VERSION ""

NS_ :

BS_:

BU_: FUSION ESC eBST FCM EPS SRR_M ABM

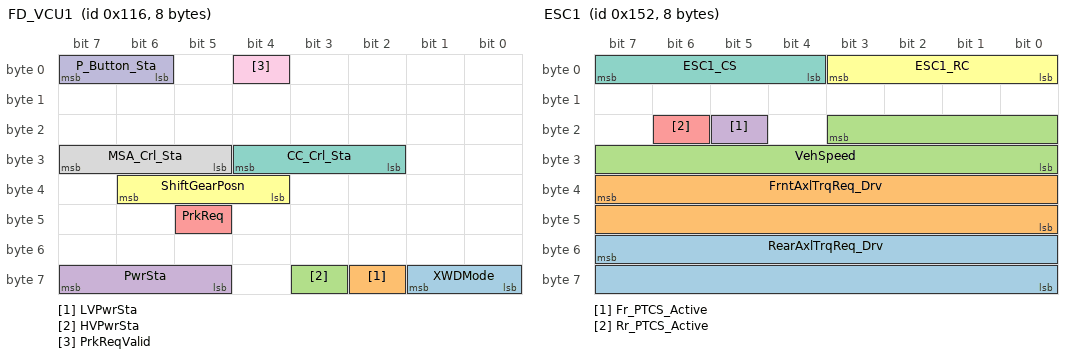
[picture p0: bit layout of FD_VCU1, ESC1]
BO_ 278 FD_VCU1: 8 FUSION
 SG_ XWDMode : 57|2@0+ (1,0) [0|2] "" ESC
 SG_ LVPwrSta : 58|1@0+ (1,0) [0|1] "" Vector__XXX
 SG_ HVPwrSta : 59|1@0+ (1,0) [0|1] "" Vector__XXX
 SG_ PwrSta : 63|3@0+ (1,0) [0|5] "" ESC,eBST,FCM,EPS,SRR_M,ABM
 SG_ PrkReq : 45|1@0+ (1,0) [0|1] "" ESC
 SG_ ShiftGearPosn : 38|3@0+ (1,0) [0|7] "" ESC,eBST,FCM,SRR_M,ABM
 SG_ CC_Crl_Sta : 28|3@0+ (1,0) [0|7] "" Vector__XXX
 SG_ MSA_Crl_Sta : 31|3@0+ (1,0) [0|7] "" Vector__XXX
 SG_ PrkReqValid : 4|1@0+ (1,0) [0|1] "" ESC
 SG_ P_Button_Sta : 7|2@0+ (1,0) [0|3] "" ESC

BO_ 338 ESC1: 8 ESC
 SG_ RearAxlTrqReq_Drv : 55|16@0+ (0.5,-5300) [0|5300] "Nm" FUSION
 SG_ FrntAxlTrqReq_Drv : 39|16@0+ (0.5,-5300) [0|5300] "Nm" FUSION
 SG_ VehSpeed : 19|12@0+ (0.125,0) [0|255.875] "km/h" FUSION
 SG_ Fr_PTCS_Active : 21|1@0+ (1,0) [0|1] "" FUSION
 SG_ Rr_PTCS_Active : 22|1@0+ (1,0) [0|1] "" FUSION
 SG_ ESC1_RC : 3|4@0+ (1,0) [0|15] "" FUSION
 SG_ ESC1_CS : 7|4@0+ (1,0) [0|15] "" FUSION

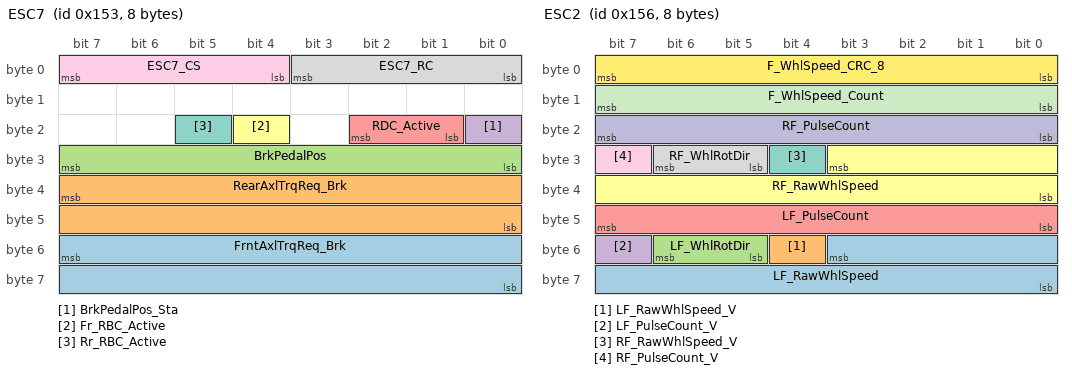
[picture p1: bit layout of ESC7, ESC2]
BO_ 339 ESC7: 8 ESC
 SG_ FrntAxlTrqReq_Brk : 55|16@0+ (0.5,-5300) [-5300|0] "Nm" FUSION
 SG_ RearAxlTrqReq_Brk : 39|16@0+ (0.5,-5300) [-5300|0] "Nm" FUSION
 SG_ BrkPedalPos : 31|8@0+ (0.4,0) [0|100] "%" FUSION
 SG_ BrkPedalPos_Sta : 16|1@0+ (1,0) [0|1] "" FUSION
 SG_ RDC_Active : 18|2@0+ (1,0) [0|2] "" FUSION
 SG_ Fr_RBC_Active : 20|1@0+ (1,0) [0|1] "" FUSION
 SG_ Rr_RBC_Active : 21|1@0+ (1,0) [0|1] "" FUSION
 SG_ ESC7_RC : 3|4@0+ (1,0) [0|15] "" FUSION
 SG_ ESC7_CS : 7|4@0+ (1,0) [0|15] "" FUSION

BO_ 340 FD_VCU2: 16 FUSION
 SG_ ActAPSPosn : 127|8@0+ (0.394,0) [0|100.076] "%" ESC,FCM,ABM
 SG_ DriverTq : 111|16@0+ (1,-4300) [-4300|4300] "Nm" FCM
 SG_ VehActPwr : 87|24@0+ (1,-600000) [-600000|600000] "W" Vector__XXX
 SG_ Rr_DriverTq : 39|16@0+ (0.5,-5300) [-5300|5300] "Nm" ESC
 SG_ Fr_DriverTq : 23|16@0+ (0.5,-5300) [-5300|5300] "Nm" ESC
 SG_ AccPedal_Override : 14|1@0+ (1,0) [0|1] "" FCM
 SG_ ACC_CtrlAvail : 15|1@0+ (1,0) [0|1] "" FCM
 SG_ CS_VCU2_CAN1 : 7|8@0+ (1,0) [0|255] "" FCM
 SG_ RC_VCU2_CAN1 : 11|4@0+ (1,0) [0|15] "" FCM

BO_ 342 ESC2: 8 ESC
 SG_ LF_RawWhlSpeed : 51|12@0+ (0.0625,0) [0|255.9375] "km/h" FUSION
 SG_ LF_RawWhlSpeed_V : 52|1@0+ (1,0) [0|1] "" FUSION
 SG_ LF_WhlRotDir : 54|2@0+ (1,0) [0|3] "" FUSION
 SG_ LF_PulseCount_V : 55|1@0+ (1,0) [0|1] "" FUSION
 SG_ LF_PulseCount : 47|8@0+ (1,0) [0|255] "" FUSION
 SG_ RF_RawWhlSpeed : 27|12@0+ (0.0625,0) [0|255.9375] "km/h" FUSION
 SG_ RF_RawWhlSpeed_V : 28|1@0+ (1,0) [0|1] "" FUSION
 SG_ RF_WhlRotDir : 30|2@0+ (1,0) [0|3] "" FUSION
 SG_ RF_PulseCount_V : 31|1@0+ (1,0) [0|1] "" FUSION
 SG_ RF_PulseCount : 23|8@0+ (1,0) [0|255] "" FUSION
 SG_ F_WhlSpeed_Count : 15|8@0+ (1,0) [0|255] "" FUSION
 SG_ F_WhlSpeed_CRC_8 : 7|8@0+ (1,0) [0|255] "" FUSION

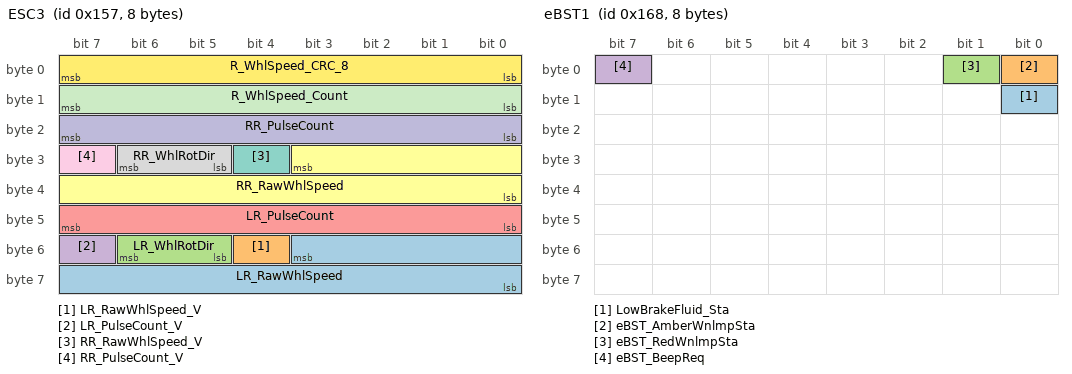
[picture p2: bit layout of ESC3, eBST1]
BO_ 343 ESC3: 8 ESC
 SG_ LR_RawWhlSpeed : 51|12@0+ (0.0625,0) [0|255.9375] "km/h" FUSION
 SG_ LR_RawWhlSpeed_V : 52|1@0+ (1,0) [0|1] "" FUSION
 SG_ LR_WhlRotDir : 54|2@0+ (1,0) [0|3] "" FUSION
 SG_ LR_PulseCount_V : 55|1@0+ (1,0) [0|1] "" FUSION
 SG_ LR_PulseCount : 47|8@0+ (1,0) [0|255] "" FUSION
 SG_ RR_RawWhlSpeed : 27|12@0+ (0.0625,0) [0|255.9375] "km/h" FUSION
 SG_ RR_RawWhlSpeed_V : 28|1@0+ (1,0) [0|1] "" FUSION
 SG_ RR_WhlRotDir : 30|2@0+ (1,0) [0|3] "" FUSION
 SG_ RR_PulseCount_V : 31|1@0+ (1,0) [0|1] "" FUSION
 SG_ RR_PulseCount : 23|8@0+ (1,0) [0|255] "" FUSION
 SG_ R_WhlSpeed_Count : 15|8@0+ (1,0) [0|255] "" FUSION
 SG_ R_WhlSpeed_CRC_8 : 7|8@0+ (1,0) [0|255] "" FUSION

BO_ 345 FD_VCU3: 20 FUSION
 SG_ Fr_EDURealDrvOrBRgnTq : 151|16@0+ (0.5,-5300) [-5300|5300] "Nm" ESC,eBST
 SG_ Fr_EDUAvailBrkRgnTq : 135|16@0+ (0.5,-5300) [-5300|0] "Nm" ESC,eBST
 SG_ Fr_EDURealARgnTq : 119|16@0+ (1,-5300) [-5300|5300] "Nm" ESC
 SG_ Fr_EDUSpd : 99|12@0+ (1,-2000) [-2000|2000] "RPM" ESC
 SG_ Fr_EDUAvailBrkRgnTqValid : 102|1@0+ (1,0) [0|1] "" ESC,eBST
 SG_ Rr_EDUAvailBrkRgnTqValid : 103|1@0+ (1,0) [0|1] "" ESC,eBST
 SG_ Rr_EDURealDrvOrBRgnTq : 87|16@0+ (0.5,-5300) [-5300|5300] "Nm" ESC,eBST
 SG_ Rr_EDUAvailBrkRgnTq : 71|16@0+ (0.5,-5300) [-5300|0] "Nm" ESC,eBST
 SG_ Rr_EDURealARgnTq : 55|16@0+ (1,-5300) [-5300|5300] "Nm" ESC
 SG_ Rr_EDUSpd : 35|12@0+ (1,-2000) [-2000|2000] "RPM" ESC
 SG_ EquivAccPedalSWSta : 38|1@0+ (1,0) [0|1] "" ESC,eBST
 SG_ PTCS_PermSta : 39|1@0+ (1,0) [0|1] "" ESC
 SG_ Rr_RgnPermSta : 24|1@0+ (1,0) [0|1] "" ESC
 SG_ Fr_RgnPermSta : 25|1@0+ (1,0) [0|1] "" ESC
 SG_ Rr_RgnDecrSta : 26|1@0+ (1,0) [0|1] "" ESC
 SG_ Fr_RgnDecrSta : 27|1@0+ (1,0) [0|1] "" ESC
 SG_ RgnAbnorSta : 28|1@0+ (1,0) [0|1] "" ESC
 SG_ Rr_EDUSpdValid : 29|1@0+ (1,0) [0|1] "" ESC
 SG_ Fr_EDUSpdValid : 30|1@0+ (1,0) [0|1] "" ESC
 SG_ RC_VCU3_CAN1 : 15|4@0+ (1,0) [0|15] "" ESC,eBST
 SG_ CS_VCU3_CAN1 : 7|8@0+ (1,0) [0|255] "" ESC,eBST

BO_ 360 eBST1: 8 eBST
 SG_ LowBrakeFluid_Sta : 8|1@0+ (1,0) [0|1] "" FUSION
 SG_ eBST_AmberWnlmpSta : 0|1@0+ (1,0) [0|1] "" FUSION
 SG_ eBST_RedWnlmpSta : 1|1@0+ (1,0) [0|1] "" FUSION
 SG_ eBST_BeepReq : 7|1@0+ (1,0) [0|1] "" FUSION

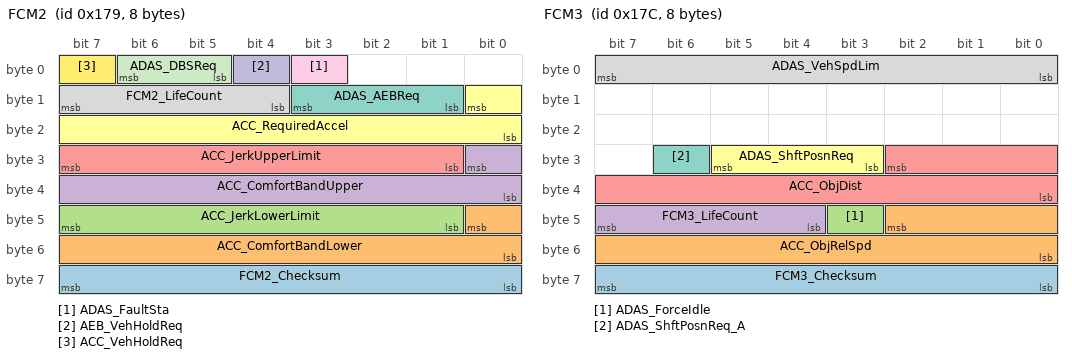
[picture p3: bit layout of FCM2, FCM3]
BO_ 377 FCM2: 8 FCM
 SG_ FCM2_Checksum : 63|8@0+ (1,0) [0|255] "" FUSION
 SG_ ACC_ComfortBandLower : 40|9@0+ (0.05,-15) [-15|10.55] "m/s^2" FUSION
 SG_ ACC_JerkLowerLimit : 47|7@0+ (0.1,-6) [-6|6.7] "m/s^3" FUSION
 SG_ ACC_ComfortBandUpper : 24|9@0+ (0.05,-15) [-15|10.55] "m/s^2" FUSION
 SG_ ACC_JerkUpperLimit : 31|7@0+ (0.1,-6) [-6|6.7] "m/s^3" FUSION
 SG_ ACC_RequiredAccel : 8|9@0+ (0.05,-15) [-15|10.55] "m/s^2" FUSION
 SG_ ADAS_AEBReq : 11|3@0+ (1,0) [0|7] "" FUSION
 SG_ FCM2_LifeCount : 15|4@0+ (1,0) [0|15] "" FUSION
 SG_ ADAS_FaultSta : 3|1@0+ (1,0) [0|1] "" FUSION
 SG_ AEB_VehHoldReq : 4|1@0+ (1,0) [0|1] "" FUSION
 SG_ ADAS_DBSReq : 6|2@0+ (1,0) [0|3] "" FUSION
 SG_ ACC_VehHoldReq : 7|1@0+ (1,0) [0|1] "" FUSION

BO_ 380 FCM3: 8 FCM
 SG_ FCM3_Checksum : 63|8@0+ (1,0) [0|255] "" FUSION
 SG_ ACC_ObjRelSpd : 42|11@0+ (0.1,-100) [-100|104.6] "m/s" FUSION
 SG_ ADAS_ForceIdle : 43|1@0+ (1,0) [0|1] "" FUSION
 SG_ FCM3_LifeCount : 47|4@0+ (1,0) [0|15] "" FUSION
 SG_ ACC_ObjDist : 26|11@0+ (0.1,0) [0|204.6] "m" FUSION
 SG_ ADAS_ShftPosnReq : 29|3@0+ (1,0) [0|7] "" FUSION
 SG_ ADAS_ShftPosnReq_A : 30|1@0+ (1,0) [0|1] "" FUSION
 SG_ ADAS_VehSpdLim : 7|8@0+ (1,0) [0|254] "" FUSION

BO_ 386 FD_THCM1: 20 FUSION
 SG_ Rr_Coolanttemp : 144|9@0+ (1,-40) [-40|214] "Deg^C" Vector__XXX
 SG_ Rr_Coolantflow : 150|6@0+ (0.25,0) [0|15.75] "L/min" Vector__XXX
 SG_ FD_AGS_Cmd : 143|8@0+ (1,0) [0|255] "" Vector__XXX
 SG_ sigClntTHvBattOut : 135|8@0+ (0.5,-40) [-40|85] "Deg^C" Vector__XXX
 SG_ sigCbnSolarLeft : 127|8@0+ (5,0) [0|1265] "W" Vector__XXX
 SG_ CabinMode : 115|4@0+ (1,0) [0|9] "" Vector__XXX
 SG_ BatteryMode : 118|3@0+ (1,0) [0|5] "" Vector__XXX
 SG_ FD_RecyAuto_Cmd : 111|3@0+ (1,0) [0|6] "" Vector__XXX
 SG_ sigCbnSolarRight : 103|8@0+ (5,0) [0|1265] "W" Vector__XXX
 SG_ sigAmbAirT : 95|8@0+ (0.5,-40) [-40|85] "Deg^C" ESC
 SG_ sigCbnAirT : 87|8@0+ (0.5,-40) [-40|85] "Deg^C" Vector__XXX
 SG_ sigCbnPTCPwrAct : 79|8@0+ (50,0) [0|12650] "W" Vector__XXX
 SG_ sigClmtCmprPwrAct : 71|8@0+ (50,0) [0|12650] "W" Vector__XXX
 SG_ Fr_Coolantflow : 61|6@0+ (0.25,0) [0|15.75] "L/min" Vector__XXX
 SG_ EDriveMode : 63|2@0+ (1,0) [0|2] "" Vector__XXX
 SG_ sigSetTempZon1St : 53|6@0+ (0.5,17) [17|32] "Deg^C" Vector__XXX
 SG_ HPThermalRecoveryReq : 55|2@0+ (1,0) [0|1] "" Vector__XXX
 SG_ sigSetTempZon2St : 45|6@0+ (0.5,17) [17|32] "Deg^C" Vector__XXX
 SG_ sigHvacSt : 46|1@0+ (1,0) [0|1] "" Vector__XXX
 SG_ sigRecircSt : 47|1@0+ (1,0) [0|1] "" Vector__XXX
 SG_ sigSetTempZon3St : 37|6@0+ (0.5,17) [17|32] "Deg^C" Vector__XXX
 SG_ sigDfrstSt : 38|1@0+ (1,0) [0|1] "" Vector__XXX
 SG_ CCU_SyncLampSts : 39|1@0+ (1,0) [0|1] "" Vector__XXX
 SG_ sigAirIntenZon3St : 27|4@0+ (1,0) [0|15] "" Vector__XXX
 SG_ sigAirIntenZon1St : 31|4@0+ (1,0) [0|15] "" Vector__XXX
 SG_ sigWindDirZon3St : 18|3@0+ (1,0) [0|7] "" Vector__XXX
 SG_ CCU_FrtOnOffLampSts : 19|1@0+ (1,0) [0|1] "" Vector__XXX
 SG_ sigWindDirZon1St : 22|3@0+ (1,0) [0|7] "" Vector__XXX
 SG_ CCU_RrOnOffLampSts : 23|1@0+ (1,0) [0|1] "" Vector__XXX
 SG_ Fr_Coolanttemp : 0|9@0+ (1,-40) [-40|214] "Deg^C" Vector__XXX
 SG_ CCU_ACMaxLampSts : 1|1@0+ (1,0) [0|1] "" Vector__XXX
 SG_ CCU_AutoLampSts : 2|1@0+ (1,0) [0|1] "" Vector__XXX
 SG_ CCU_AutoMidLampSts : 3|1@0+ (1,0) [0|1] "" Vector__XXX
 SG_ CCU_EcoSts : 4|1@0+ (1,0) [0|1] "" Vector__XXX
 SG_ CCU_Dispaly_Request : 5|1@0+ (1,0) [0|1] "" Vector__XXX
 SG_ CCU_ACLampSts : 6|1@0+ (1,0) [0|1] "" Vector__XXX
 SG_ CCU_HEATMaxLampSts : 7|1@0+ (1,0) [0|1] "" Vector__XXX

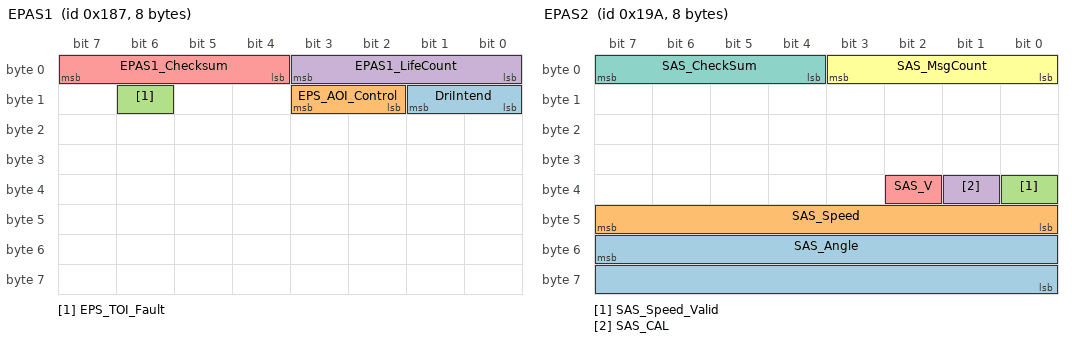
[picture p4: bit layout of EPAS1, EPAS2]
BO_ 391 EPAS1: 8 EPS
 SG_ DriIntend : 9|2@0+ (1,0) [0|2] "" FUSION
 SG_ EPS_AOI_Control : 11|2@0+ (1,0) [0|3] "" FUSION
 SG_ EPS_TOI_Fault : 14|1@0+ (1,0) [0|1] "" FUSION
 SG_ EPAS1_LifeCount : 3|4@0+ (1,0) [0|15] "" FUSION
 SG_ EPAS1_Checksum : 7|4@0+ (1,0) [0|15] "" FUSION

BO_ 410 EPAS2: 8 EPS
 SG_ SAS_Angle : 55|16@0+ (0.1,-900) [-900|900] "Deg" FUSION
 SG_ SAS_Speed : 47|8@0+ (4,0) [0|1020] "Deg/s" FUSION
 SG_ SAS_Speed_Valid : 32|1@0+ (1,0) [0|1] "" FUSION
 SG_ SAS_CAL : 33|1@0+ (1,0) [0|1] "" FUSION
 SG_ SAS_V : 34|1@0+ (1,0) [0|1] "" FUSION
 SG_ SAS_MsgCount : 3|4@0+ (1,0) [0|15] "" FUSION
 SG_ SAS_CheckSum : 7|4@0+ (1,0) [0|15] "" FUSION

BO_ 419 ESC4: 8 ESC
 SG_ Red_WnlmpSta : 59|1@0+ (1,0) [0|1] "" FUSION
 SG_ ABS_WnlmpSta : 60|1@0+ (1,0) [0|1] "" FUSION
 SG_ ESC_Off_lmpSta : 61|1@0+ (1,0) [0|1] "" FUSION
 SG_ ESC_WnlmpSta : 63|2@0+ (1,0) [0|2] "" FUSION
 SG_ GRADE : 55|8@0+ (0.354331,-45) [-45|45] "Deg" FUSION
 SG_ EBD_Active : 44|1@0+ (1,0) [0|1] "" FUSION
 SG_ ABS_Active : 45|1@0+ (1,0) [0|1] "" FUSION
 SG_ TCS_Active : 46|1@0+ (1,0) [0|1] "" FUSION
 SG_ ESC_Active : 47|1@0+ (1,0) [0|1] "" FUSION
 SG_ HBB_Active : 32|1@0+ (1,0) [0|1] "" FUSION
 SG_ PBA_Active : 33|1@0+ (1,0) [0|1] "" FUSION
 SG_ HSA_Active : 34|1@0+ (1,0) [0|1] "" FUSION
 SG_ AVH_Active : 35|1@0+ (1,0) [0|1] "" FUSION
 SG_ Amber_WnlmpSta : 36|1@0+ (1,0) [0|1] "" FUSION
 SG_ BTCS_Active : 37|1@0+ (1,0) [0|1] "" FUSION
 SG_ ESS_Active : 38|1@0+ (1,0) [0|1] "" FUSION
 SG_ HDD_Active : 39|1@0+ (1,0) [0|1] "" FUSION
 SG_ EBD_Failed : 24|1@0+ (1,0) [0|1] "" FUSION
 SG_ ABS_Failed : 25|1@0+ (1,0) [0|1] "" FUSION
 SG_ TCS_Failed : 26|1@0+ (1,0) [0|1] "" FUSION
 SG_ ESC_Failed : 27|1@0+ (1,0) [0|1] "" FUSION
 SG_ HBB_Failed : 28|1@0+ (1,0) [0|1] "" FUSION
 SG_ PBA_Failed : 29|1@0+ (1,0) [0|1] "" FUSION
 SG_ HSA_Failed : 30|1@0+ (1,0) [0|1] "" FUSION
 SG_ AVH_Failed : 31|1@0+ (1,0) [0|1] "" FUSION
 SG_ HDD_Failed : 16|1@0+ (1,0) [0|1] "" FUSION
 SG_ ESC_OFF_Status : 18|2@0+ (1,0) [0|2] "" FUSION
 SG_ ESC_BeepReq : 15|1@0+ (1,0) [0|1] "" FUSION
 SG_ SystemVoltage : 7|8@0+ (0.08,0) [0|20.32] "V" FUSION

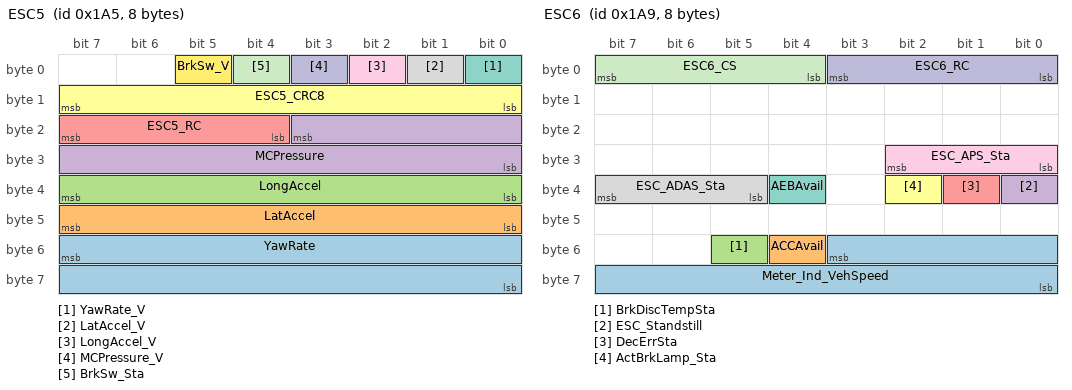
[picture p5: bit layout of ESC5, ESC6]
BO_ 421 ESC5: 8 ESC
 SG_ YawRate : 55|16@0+ (0.1,-100) [-100|100] "Deg/s" FUSION
 SG_ LatAccel : 47|8@0+ (0.01,-1.27) [-1.27|1.27] "G's" FUSION
 SG_ LongAccel : 39|8@0+ (0.01,-1.27) [-1.27|1.27] "G's" FUSION
 SG_ MCPressure : 19|12@0+ (0.1,-9.7) [-9.7|195] "bar" FUSION
 SG_ ESC5_RC : 23|4@0+ (1,0) [0|15] "" FUSION
 SG_ ESC5_CRC8 : 15|8@0+ (1,0) [0|255] "" FUSION
 SG_ YawRate_V : 0|1@0+ (1,0) [0|1] "" FUSION
 SG_ LatAccel_V : 1|1@0+ (1,0) [0|1] "" FUSION
 SG_ LongAccel_V : 2|1@0+ (1,0) [0|1] "" FUSION
 SG_ MCPressure_V : 3|1@0+ (1,0) [0|1] "" FUSION
 SG_ BrkSw_Sta : 4|1@0+ (1,0) [0|1] "" FUSION
 SG_ BrkSw_V : 5|1@0+ (1,0) [0|1] "" FUSION

BO_ 425 ESC6: 8 ESC
 SG_ Meter_Ind_VehSpeed : 51|12@0+ (0.125,0) [0|300] "km/h" FUSION
 SG_ ACCAvail : 52|1@0+ (1,0) [0|1] "" FUSION
 SG_ BrkDiscTempSta : 53|1@0+ (1,0) [0|1] "" FUSION
 SG_ ESC_Standstill : 32|1@0+ (1,0) [0|1] "" FUSION
 SG_ DecErrSta : 33|1@0+ (1,0) [0|1] "" FUSION
 SG_ ActBrkLamp_Sta : 34|1@0+ (1,0) [0|1] "" FUSION
 SG_ AEBAvail : 36|1@0+ (1,0) [0|1] "" FUSION
 SG_ ESC_ADAS_Sta : 39|3@0+ (1,0) [0|6] "" FUSION
 SG_ ESC_APS_Sta : 26|3@0+ (1,0) [0|5] "" FUSION
 SG_ ESC6_RC : 3|4@0+ (1,0) [0|15] "" FUSION
 SG_ ESC6_CS : 7|4@0+ (1,0) [0|15] "" FUSION

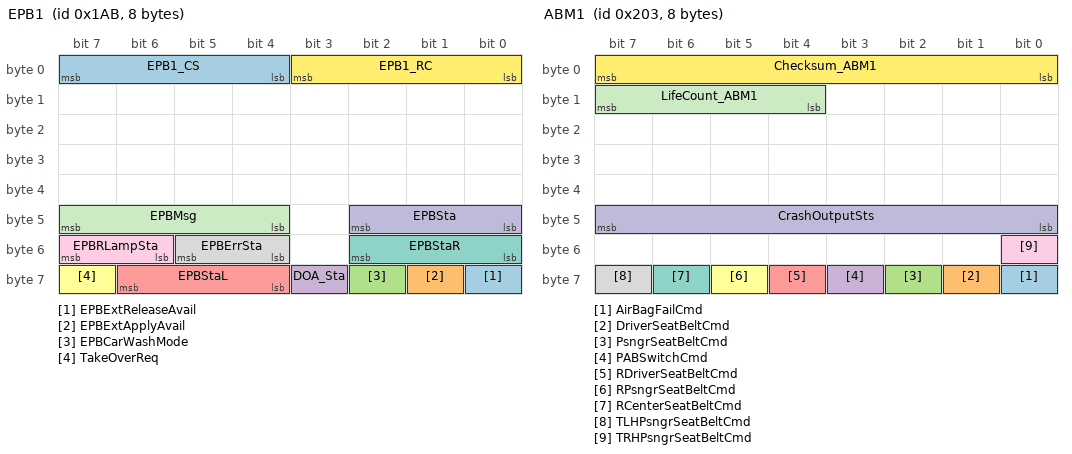
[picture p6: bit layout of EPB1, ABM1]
BO_ 427 EPB1: 8 ESC
 SG_ EPBExtReleaseAvail : 56|1@0+ (1,0) [0|1] "" FUSION
 SG_ EPBExtApplyAvail : 57|1@0+ (1,0) [0|1] "" FUSION
 SG_ EPBCarWashMode : 58|1@0+ (1,0) [0|1] "" FUSION
 SG_ DOA_Sta : 59|1@0+ (1,0) [0|1] "" FUSION
 SG_ EPBStaL : 62|3@0+ (1,0) [0|7] "" FUSION
 SG_ TakeOverReq : 63|1@0+ (1,0) [0|1] "" FUSION
 SG_ EPBStaR : 50|3@0+ (1,0) [0|7] "" FUSION
 SG_ EPBErrSta : 53|2@0+ (1,0) [0|2] "" FUSION
 SG_ EPBRLampSta : 55|2@0+ (1,0) [0|2] "" FUSION
 SG_ EPBSta : 42|3@0+ (1,0) [0|4] "" FUSION
 SG_ EPBMsg : 47|4@0+ (1,0) [0|12] "" FUSION
 SG_ EPB1_RC : 3|4@0+ (1,0) [0|15] "" FUSION
 SG_ EPB1_CS : 7|4@0+ (1,0) [0|15] "" FUSION

BO_ 515 ABM1: 8 ABM
 SG_ AirBagFailCmd : 56|1@0+ (1,0) [0|1] "" FUSION
 SG_ DriverSeatBeltCmd : 57|1@0+ (1,0) [0|1] "" FUSION
 SG_ PsngrSeatBeltCmd : 58|1@0+ (1,0) [0|1] "" FUSION
 SG_ PABSwitchCmd : 59|1@0+ (1,0) [0|1] "" FUSION
 SG_ RDriverSeatBeltCmd : 60|1@0+ (1,0) [0|1] "" FUSION
 SG_ RPsngrSeatBeltCmd : 61|1@0+ (1,0) [0|1] "" FUSION
 SG_ RCenterSeatBeltCmd : 62|1@0+ (1,0) [0|1] "" FUSION
 SG_ TLHPsngrSeatBeltCmd : 63|1@0+ (1,0) [0|1] "" FUSION
 SG_ TRHPsngrSeatBeltCmd : 48|1@0+ (1,0) [0|1] "" FUSION
 SG_ CrashOutputSts : 47|8@0+ (1,0) [0|16] "" FUSION
 SG_ LifeCount_ABM1 : 15|4@0+ (1,0) [0|15] "" FUSION
 SG_ Checksum_ABM1 : 7|8@0+ (1,0) [0|255] "" FUSION

BO_ 517 SRR1: 8 SRR_M
 SG_ SRR1_Chksum : 63|8@0+ (1,0) [0|255] "" FUSION
 SG_ SRR_RCTA_WarnR : 48|1@0+ (1,0) [0|1] "" FUSION
 SG_ SRR_RCTA_WarnL : 49|1@0+ (1,0) [0|1] "" FUSION
 SG_ SRR_BSD_WarnR : 41|2@0+ (1,0) [0|3] "" FUSION
 SG_ SRR_BSD_WarnL : 43|2@0+ (1,0) [0|3] "" FUSION
 SG_ SRR_BSD_SoundR : 44|1@0+ (1,0) [0|1] "" FUSION
 SG_ SRR_BSD_SoundL : 45|1@0+ (1,0) [0|1] "" FUSION
 SG_ SRR_BSD_Mute : 46|1@0+ (1,0) [0|1] "" FUSION
 SG_ SRR_ODA_WarnR : 33|2@0+ (1,0) [0|3] "" FUSION
 SG_ SRR_ODA_WarnL : 35|2@0+ (1,0) [0|3] "" FUSION
 SG_ SRR_ODA_SoundR : 36|1@0+ (1,0) [0|1] "" FUSION
 SG_ SRR_ODA_SoundL : 37|1@0+ (1,0) [0|1] "" FUSION
 SG_ SRR_ODA_Mute : 38|1@0+ (1,0) [0|1] "" FUSION
 SG_ SRR_ODA_Sta : 18|3@0+ (1,0) [0|7] "" FUSION
 SG_ SRR_BSD_Sta : 10|3@0+ (1,0) [0|7] "" FUSION
 SG_ SRR_RCTA_Sta : 14|3@0+ (1,0) [0|7] "" FUSION
 SG_ SRR_FltWrnReq : 15|1@0+ (1,0) [0|1] "" FUSION
 SG_ SRR1_LifeCount : 7|4@0+ (1,0) [0|15] "" FUSION

BO_ 528 FD_APS2: 32 FUSION
 SG_ PAS_A_FCL : 219|4@0+ (1,0) [0|15] "" Vector__XXX
 SG_ PAS_Chime : 223|4@0+ (1,0) [0|15] "" Vector__XXX
 SG_ APS_Progress_PCT : 215|8@0+ (1,0) [0|100] "%" Vector__XXX
 SG_ APS_RQ_Display : 207|8@0+ (1,0) [0|255] "" Vector__XXX
 SG_ PAS_D_RMR : 199|8@0+ (1,0) [0|150] "" Vector__XXX
 SG_ PAS_D_RML : 191|8@0+ (1,0) [0|150] "" Vector__XXX
 SG_ PAS_D_RCR : 183|8@0+ (1,0) [0|150] "" Vector__XXX
 SG_ PAS_D_RCL : 175|8@0+ (1,0) [0|150] "" Vector__XXX
 SG_ APS_SW_Ver : 167|8@0+ (1,0) [0|255] "" Vector__XXX
 SG_ APS_HW_Ver : 159|8@0+ (1,0) [0|255] "" Vector__XXX
 SG_ APS_ExitCondition : 151|8@0+ (1,0) [0|255] "" Vector__XXX
 SG_ PAS_D_FMR : 143|8@0+ (1,0) [0|150] "" Vector__XXX
 SG_ PAS_D_FML : 135|8@0+ (1,0) [0|150] "" Vector__XXX
 SG_ PAS_D_FCR : 127|8@0+ (1,0) [0|150] "" Vector__XXX
 SG_ PAS_D_FCL : 119|8@0+ (1,0) [0|150] "" Vector__XXX
 SG_ APS_D_RLR : 97|10@0+ (1,0) [0|1023] "" Vector__XXX
 SG_ APS_D_RLL : 81|10@0+ (1,0) [0|1023] "" Vector__XXX
 SG_ APS_D_FLR : 65|10@0+ (1,0) [0|1023] "" Vector__XXX
 SG_ APS_D_FLL : 49|10@0+ (1,0) [0|1023] "" Vector__XXX
 SG_ PAS_SNSR_Layout : 43|4@0+ (1,0) [0|15] "" Vector__XXX
 SG_ PAS_A_RMR : 47|4@0+ (1,0) [0|15] "" Vector__XXX
 SG_ PAS_A_RML : 35|4@0+ (1,0) [0|15] "" Vector__XXX
 SG_ PAS_A_RCR : 39|4@0+ (1,0) [0|15] "" Vector__XXX
 SG_ PAS_A_RCL : 27|4@0+ (1,0) [0|15] "" Vector__XXX
 SG_ PAS_A_FMR : 31|4@0+ (1,0) [0|15] "" Vector__XXX
 SG_ PAS_A_FML : 19|4@0+ (1,0) [0|15] "" Vector__XXX
 SG_ PAS_A_FCR : 23|4@0+ (1,0) [0|15] "" Vector__XXX
 SG_ PAS_Sta_F_Sys : 9|1@0+ (1,0) [0|1] "" Vector__XXX
 SG_ PAS_Mod_Operation : 11|2@0+ (1,0) [0|3] "" Vector__XXX
 SG_ USS_Sta_RMR : 12|1@0+ (1,0) [0|1] "" Vector__XXX
 SG_ USS_Sta_RML : 13|1@0+ (1,0) [0|1] "" Vector__XXX
 SG_ USS_Sta_RLR : 14|1@0+ (1,0) [0|1] "" Vector__XXX
 SG_ USS_Sta_RLL : 15|1@0+ (1,0) [0|1] "" Vector__XXX
 SG_ USS_Sta_RCR : 0|1@0+ (1,0) [0|1] "" Vector__XXX
 SG_ USS_Sta_RCL : 1|1@0+ (1,0) [0|1] "" Vector__XXX
 SG_ USS_Sta_FMR : 2|1@0+ (1,0) [0|1] "" Vector__XXX
 SG_ USS_Sta_FML : 3|1@0+ (1,0) [0|1] "" Vector__XXX
 SG_ USS_Sta_FLR : 4|1@0+ (1,0) [0|1] "" Vector__XXX
 SG_ USS_Sta_FLL : 5|1@0+ (1,0) [0|1] "" Vector__XXX
 SG_ USS_Sta_FCR : 6|1@0+ (1,0) [0|1] "" Vector__XXX
 SG_ USS_Sta_FCL : 7|1@0+ (1,0) [0|1] "" Vector__XXX

BO_ 534 FD_BCM1: 16 FUSION
 SG_ DrDoorSW : 120|1@0+ (1,0) [0|1] "" ESC,FCM,SRR_M
 SG_ PsDoorSW : 121|1@0+ (1,0) [0|1] "" FCM,SRR_M
 SG_ RLDoorSW : 122|1@0+ (1,0) [0|1] "" FCM,SRR_M
 SG_ RRDoorSW : 123|1@0+ (1,0) [0|1] "" FCM,SRR_M
 SG_ AllDoorSW : 124|1@0+ (1,0) [0|1] "" FCM
 SG_ DoorLockIND : 125|1@0+ (1,0) [0|1] "" Vector__XXX
 SG_ HoodSW : 126|1@0+ (1,0) [0|1] "" Vector__XXX
 SG_ Tailgate_SW : 127|1@0+ (1,0) [0|1] "" FCM
 SG_ CTDCtrl : 113|2@0+ (1,0) [0|3] "" Vector__XXX
 SG_ Fr_ChargingDoorCtrl : 115|2@0+ (1,0) [0|3] "" Vector__XXX
 SG_ Rr_ChargingDoorCtrl : 117|2@0+ (1,0) [0|3] "" Vector__XXX
 SG_ CTDLockSW : 118|1@0+ (1,0) [0|1] "" Vector__XXX
 SG_ CTDUnlockSW : 119|1@0+ (1,0) [0|1] "" Vector__XXX
 SG_ MirrorDefog : 104|1@0+ (1,0) [0|1] "" Vector__XXX
 SG_ Rr_Defog : 105|1@0+ (1,0) [0|1] "" Vector__XXX
 SG_ TrunkRel : 106|1@0+ (1,0) [0|1] "" Vector__XXX
 SG_ TailgateHDSW : 107|1@0+ (1,0) [0|1] "" Vector__XXX
 SG_ MirrorCtrl : 109|2@0+ (1,0) [0|3] "" Vector__XXX
 SG_ Fr_Wiper_H : 110|1@0+ (1,0) [0|1] "" FCM
 SG_ Fr_Wiper_L : 111|1@0+ (1,0) [0|1] "" FCM
 SG_ Rr_Wiper : 96|1@0+ (1,0) [0|1] "" Vector__XXX
 SG_ WiperFixMode : 97|1@0+ (1,0) [0|1] "" Vector__XXX
 SG_ WasherCtrl : 99|2@0+ (1,0) [0|3] "" Vector__XXX
 SG_ L_Beam : 100|1@0+ (1,0) [0|1] "" FCM
 SG_ H_Beam : 101|1@0+ (1,0) [0|1] "" FCM
 SG_ PosLamp : 102|1@0+ (1,0) [0|1] "" Vector__XXX
 SG_ LDRL : 103|1@0+ (1,0) [0|1] "" Vector__XXX
 SG_ RDRL : 88|1@0+ (1,0) [0|1] "" Vector__XXX
 SG_ ReverseLamp : 89|1@0+ (1,0) [0|1] "" Vector__XXX
 SG_ BrakeLamp : 90|1@0+ (1,0) [0|1] "" Vector__XXX
 SG_ LBSD : 91|1@0+ (1,0) [0|1] "" SRR_M
 SG_ RBSD : 92|1@0+ (1,0) [0|1] "" SRR_M
 SG_ Fr_FogLamp : 93|1@0+ (1,0) [0|1] "" Vector__XXX
 SG_ Rr_FogLamp : 94|1@0+ (1,0) [0|1] "" Vector__XXX
 SG_ HazardSW : 95|1@0+ (1,0) [0|1] "" FCM
 SG_ LTurnLP : 80|1@0+ (1,0) [0|1] "" FCM,SRR_M
 SG_ RTurnLP : 81|1@0+ (1,0) [0|1] "" FCM,SRR_M
 SG_ AntitheftSta : 83|2@0+ (1,0) [0|3] "" SRR_M
 SG_ AntiTheftSeatFold : 84|1@0+ (1,0) [0|1] "" Vector__XXX
 SG_ Dimmer : 78|7@0+ (1,0) [0|100] "%" Vector__XXX
 SG_ LockSetting : 79|1@0+ (1,0) [0|1] "" Vector__XXX
 SG_ BCM_Buzzer_Req : 64|1@0+ (1,0) [0|1] "" Vector__XXX
 SG_ TailgateRemote : 66|2@0+ (1,0) [0|3] "" Vector__XXX
 SG_ RoomLampL : 67|1@0+ (1,0) [0|1] "" Vector__XXX
 SG_ RoomLampH : 68|1@0+ (1,0) [0|1] "" Vector__XXX
 SG_ DimmerEN : 69|1@0+ (1,0) [0|1] "" Vector__XXX
 SG_ BCM_DoorLock_Sta : 70|1@0+ (1,0) [0|1] "" Vector__XXX
 SG_ HornCtrl : 71|1@0+ (1,0) [0|1] "" Vector__XXX
 SG_ CrashDetd : 85|1@0+ (1,0) [0|1] "" Vector__XXX
 SG_ L_APM_WdwEnable : 87|1@0+ (1,0) [0|1] "" Vector__XXX

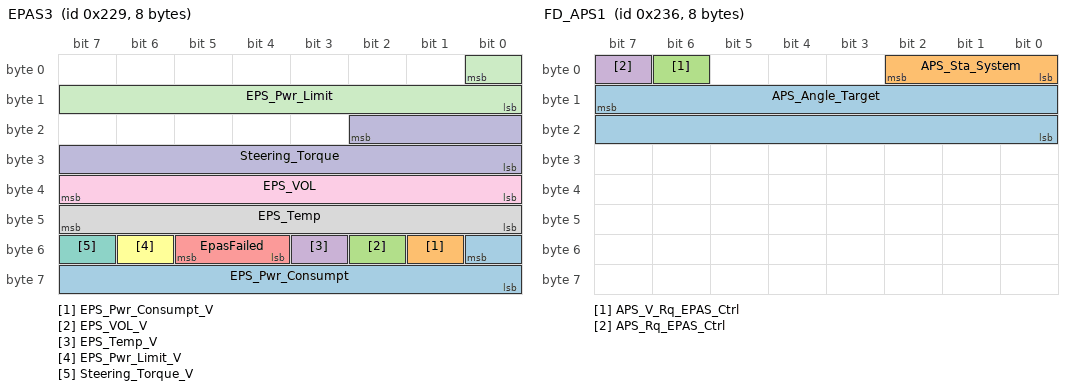
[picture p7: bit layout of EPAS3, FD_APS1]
BO_ 553 EPAS3: 8 EPS
 SG_ EPS_Pwr_Consumpt : 48|9@0+ (0.5,0) [0|135] "A" FUSION
 SG_ EPS_Pwr_Consumpt_V : 49|1@0+ (1,0) [0|1] "" FUSION
 SG_ EPS_VOL_V : 50|1@0+ (1,0) [0|1] "" FUSION
 SG_ EPS_Temp_V : 51|1@0+ (1,0) [0|1] "" FUSION
 SG_ EpasFailed : 53|2@0+ (1,0) [0|2] "" FUSION
 SG_ EPS_Pwr_Limit_V : 54|1@0+ (1,0) [0|1] "" FUSION
 SG_ Steering_Torque_V : 55|1@0+ (1,0) [0|1] "" FUSION
 SG_ EPS_Temp : 47|8@0+ (1,-100) [-100|155] "Deg^C" FUSION
 SG_ EPS_VOL : 39|8@0+ (0.1,0) [0|25.5] "V" FUSION
 SG_ Steering_Torque : 18|11@0+ (0.01,-10) [-10|10] "Nm" FUSION
 SG_ EPS_Pwr_Limit : 0|9@0+ (0.5,0) [0|135] "A" FUSION

BO_ 566 FD_APS1: 8 FUSION
 SG_ APS_Angle_Target : 15|16@0+ (0.1,-900) [-900|900] "Deg" EPS
 SG_ APS_Sta_System : 2|3@0+ (1,0) [0|7] "" ESC,FCM
 SG_ APS_V_Rq_EPAS_Ctrl : 6|1@0+ (1,0) [0|1] "" EPS
 SG_ APS_Rq_EPAS_Ctrl : 7|1@0+ (1,0) [0|1] "" EPS

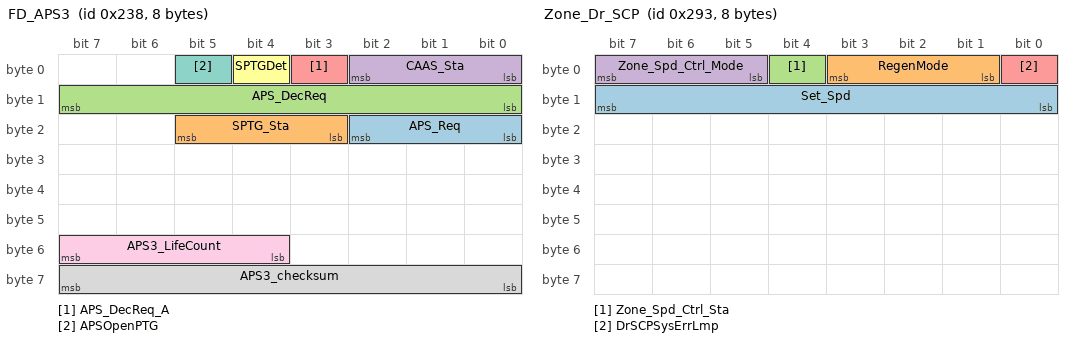
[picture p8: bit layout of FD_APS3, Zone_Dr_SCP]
BO_ 568 FD_APS3: 8 FUSION
 SG_ APS_Req : 18|3@0+ (1,0) [0|7] "" ESC
 SG_ SPTG_Sta : 21|3@0+ (1,0) [0|7] "" Vector__XXX
 SG_ APS_DecReq : 15|8@0+ (0.1,0) [0|25.4] "m/s^2" ESC
 SG_ CAAS_Sta : 2|3@0+ (1,0) [0|7] "" Vector__XXX
 SG_ APS_DecReq_A : 3|1@0+ (1,0) [0|1] "" ESC
 SG_ SPTGDet : 4|1@0+ (1,0) [0|1] "" Vector__XXX
 SG_ APSOpenPTG : 5|1@0+ (1,0) [0|1] "" Vector__XXX
 SG_ APS3_checksum : 63|8@0+ (1,0) [0|255] "" ESC
 SG_ APS3_LifeCount : 55|4@0+ (1,0) [0|15] "" ESC

BO_ 570 FCM4: 8 FCM
 SG_ FCM4_Checksum : 63|8@0+ (1,0) [0|255] "" FUSION
 SG_ ADAS_SLIF_SpdLim : 52|5@0+ (1,0) [0|31] "" FUSION
 SG_ Target_Type : 40|4@0+ (1,0) [0|15] "" FUSION
 SG_ ADAS_CAM_SpdLim : 47|5@0+ (1,0) [0|31] "" FUSION
 SG_ ADAS_WarningMsg : 35|4@0+ (1,0) [0|15] "" FUSION
 SG_ ACC_TakeoverReq : 36|1@0+ (1,0) [0|1] "" FUSION
 SG_ ACCSetSpeed_Disp : 39|3@0+ (1,0) [0|7] "" FUSION
 SG_ ACCSetSpeed : 31|8@0+ (1,0) [0|254] "" FUSION
 SG_ TimeGapLevel : 18|3@0+ (1,0) [0|7] "" FUSION
 SG_ ForceLowBeam : 20|2@0+ (1,0) [0|1] "" FUSION
 SG_ ACC_ObjDstLvl : 23|3@0+ (1,0) [0|7] "" FUSION
 SG_ ADAS_ACC_Sta : 10|3@0+ (1,0) [0|7] "" FUSION
 SG_ ADAS_FltWrnReq : 11|1@0+ (1,0) [0|1] "" FUSION
 SG_ ADAS_LDW_Sta : 14|3@0+ (1,0) [0|7] "" FUSION
 SG_ LeftTurnLightReq : 15|1@0+ (1,0) [0|1] "" FUSION
 SG_ ADAS_FCW_Sta : 2|3@0+ (1,0) [0|7] "" FUSION
 SG_ RightTurnLightReq : 3|1@0+ (1,0) [0|1] "" FUSION
 SG_ ADAS_AEB_Sta : 6|3@0+ (1,0) [0|7] "" FUSION
 SG_ HazardWarningReq : 7|1@0+ (1,0) [0|1] "" FUSION

BO_ 572 FCM5: 8 FCM
 SG_ FCM5_Checksum : 63|8@0+ (1,0) [0|255] "" FUSION
 SG_ ADAS_LFC_Warn_Sound : 55|8@0+ (1,0) [0|255] "" FUSION
 SG_ LVDA_ACCStatusInformation : 40|1@0+ (1,0) [0|1] "" FUSION
 SG_ LVDA_Warning : 41|1@0+ (1,0) [0|1] "" FUSION
 SG_ LVDA_Failinfo : 42|1@0+ (1,0) [0|1] "" FUSION
 SG_ LVDA_Mute_Sta : 44|2@0+ (1,0) [0|3] "" FUSION
 SG_ LVDA_Disabled : 45|1@0+ (1,0) [0|1] "" FUSION
 SG_ ADAS_LFC_Hands_Off_Warning : 47|2@0+ (1,0) [0|3] "" FUSION
 SG_ ADAS_FCW_Mute : 32|1@0+ (1,0) [0|1] "" FUSION
 SG_ ADAS_LDW_Mute : 34|1@0+ (1,0) [0|1] "" FUSION
 SG_ ADAS_ISA_Sta : 36|2@0+ (1,0) [0|3] "" FUSION
 SG_ ADAS_SLIF_Sta : 30|3@0+ (1,0) [0|5] "" FUSION
 SG_ ADAS_LaneModeR : 22|3@0+ (1,0) [0|7] "" FUSION
 SG_ ADAS_LaneModeL : 10|3@0+ (1,0) [0|7] "" FUSION
 SG_ ADAS_LFC_Sta : 2|3@0+ (1,0) [0|7] "" FUSION
 SG_ LKA_HOD_Sound_Warning : 3|1@0+ (1,0) [0|1] "" FUSION
 SG_ ADAS_LKA_Sta : 6|3@0+ (1,0) [0|7] "" FUSION
 SG_ LKA_HOD_Display_Warning : 7|1@0+ (1,0) [0|1] "" FUSION

BO_ 602 GW_METER1: 24 FUSION
 SG_ ODOMETER : 175|24@0+ (0.1,0) [0|999999.9] "KM" ESC,eBST,FCM
 SG_ Trip_A : 151|24@0+ (0.1,0) [0|99999.9] "KM" Vector__XXX
 SG_ Trip_B : 127|24@0+ (0.1,0) [0|99999.9] "KM" Vector__XXX
 SG_ ParkBrake : 112|1@0+ (1,0) [0|1] "" Vector__XXX
 SG_ Charge : 113|1@0+ (1,0) [0|1] "" Vector__XXX
 SG_ LEDlitWarnReq : 114|1@0+ (1,0) [0|1] "" Vector__XXX
 SG_ Spd_Crl_Sta : 115|1@0+ (1,0) [0|1] "" FCM
 SG_ Spd_Crl_Mode : 118|3@0+ (1,0) [0|7] "" FCM
 SG_ AvailableTrip : 103|16@0+ (0.1,0) [0|999.9] "KM" Vector__XXX
 SG_ APCforDTE : 87|16@0+ (0.1,-999.9) [-999.9|999.9] "Wh/km" Vector__XXX
 SG_ AVGPwrConsumption : 71|16@0+ (0.1,-999.9) [-999.9|999.9] "Wh/km" Vector__XXX
 SG_ Averaged_vehspeed : 49|10@0+ (1,0) [0|300] "km/h" Vector__XXX
 SG_ METER_MPH_Real : 35|12@0+ (0.077675,0) [0|160.0105] "mph" FCM,SRR_M
 SG_ METER_KPH_Real : 31|12@0+ (0.125,0) [0|255.875] "km/h" FCM,SRR_M
 SG_ METER_MPH_Calcu : 23|8@0+ (1,0) [0|160] "mph" FCM,SRR_M
 SG_ METER_KPH_Calcu : 15|8@0+ (1,0) [0|254] "km/h" FCM,SRR_M

BO_ 659 Zone_Dr_SCP: 8 FUSION
 SG_ Set_Spd : 15|8@0+ (1,0) [0|255] "km/h" FCM
 SG_ RegenMode : 3|3@0+ (1,0) [0|7] "" Vector__XXX
 SG_ Zone_Spd_Ctrl_Sta : 4|1@0+ (1,0) [0|1] "" FCM
 SG_ Zone_Spd_Ctrl_Mode : 7|3@0+ (1,0) [0|7] "" FCM
 SG_ DrSCPSysErrLmp : 0|1@0+ (1,0) [0|1] "" Vector__XXX

BO_ 826 GW_ZoneDR2: 8 FUSION
 SG_ SWC_LKA_Sta : 61|1@0+ (1,0) [0|1] "" FCM
 SG_ SWC_Undefined_Sta : 62|1@0+ (1,0) [0|1] "" Vector__XXX
 SG_ SWC_VR_Sta : 63|1@0+ (1,0) [0|1] "" Vector__XXX
 SG_ SWC_Up_Sta : 48|1@0+ (1,0) [0|1] "" Vector__XXX
 SG_ SWC_Trip_Sta : 50|1@0+ (1,0) [0|1] "" Vector__XXX
 SG_ SWC_Set_down_Sta : 51|1@0+ (1,0) [0|1] "" FCM
 SG_ SWC_Right_Sta : 52|1@0+ (1,0) [0|1] "" Vector__XXX
 SG_ SWC_RegenDown : 53|1@0+ (1,0) [0|1] "" Vector__XXX
 SG_ SWC_Res_Up_Sta : 54|1@0+ (1,0) [0|1] "" FCM
 SG_ SWC_resp_error : 55|1@0+ (1,0) [0|1] "" Vector__XXX
 SG_ SWC_mode_Sta : 43|1@0+ (1,0) [0|1] "" Vector__XXX
 SG_ SWC_Left_Sta : 45|1@0+ (1,0) [0|1] "" Vector__XXX
 SG_ SWC_RegenUp : 46|1@0+ (1,0) [0|1] "" Vector__XXX
 SG_ SWC_Down_Sta : 47|1@0+ (1,0) [0|1] "" Vector__XXX
 SG_ SWC_Distance_Sta : 32|1@0+ (1,0) [0|1] "" FCM
 SG_ SWC_A_Resp_Err : 34|1@0+ (1,0) [0|1] "" Vector__XXX
 SG_ SWC_ACC_Sta : 36|1@0+ (1,0) [0|1] "" FCM
 SG_ SWC_CANCEL_Sta : 37|1@0+ (1,0) [0|1] "" FCM
 SG_ SWC_Drivemode_Sta : 39|2@0+ (1,0) [0|1] "" Vector__XXX
 SG_ SWC_A_HW_version : 23|16@0+ (0.01,0) [0|99.99] "" Vector__XXX
 SG_ SWC_A_SW_version : 7|16@0+ (0.01,0) [0|99.99] "" Vector__XXX

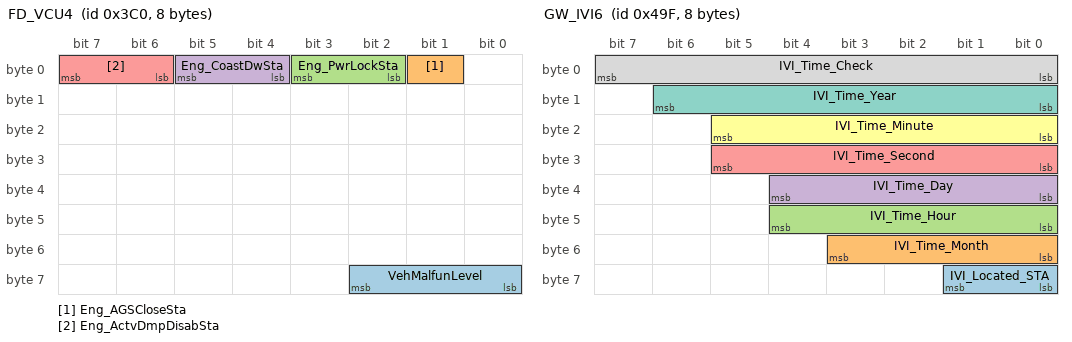
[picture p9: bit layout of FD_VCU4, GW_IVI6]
BO_ 960 FD_VCU4: 8 FUSION
 SG_ VehMalfunLevel : 58|3@0+ (1,0) [0|5] "" FCM
 SG_ Eng_AGSCloseSta : 1|1@0+ (1,0) [0|1] "" Vector__XXX
 SG_ Eng_PwrLockSta : 3|2@0+ (1,0) [0|2] "" Vector__XXX
 SG_ Eng_CoastDwSta : 5|2@0+ (1,0) [0|2] "" Vector__XXX
 SG_ Eng_ActvDmpDisabSta : 7|2@0+ (1,0) [0|2] "" Vector__XXX

BO_ 1008 APA_Debug0: 32 FUSION

BO_ 1009 APA_Debug1: 32 FUSION

BO_ 1010 APA_Debug2: 32 FUSION

BO_ 1011 APA_Debug3: 32 FUSION

BO_ 1012 APA_Debug4: 32 FUSION

BO_ 1013 APA_Debug5: 32 FUSION

BO_ 1014 APA_Debug6: 32 FUSION

BO_ 1015 APA_Debug7: 32 FUSION

BO_ 1173 GW_IVI2: 64 FUSION
 SG_ AVM_parking_cancel : 505|2@0+ (1,0) [0|3] "" Vector__XXX
 SG_ AVM_parking_excute : 507|2@0+ (1,0) [0|3] "" Vector__XXX
 SG_ AVM_OFF_Rec_Butt : 508|1@0+ (1,0) [0|1] "" Vector__XXX
 SG_ IVI_AGSCloseSW : 511|2@0+ (1,0) [0|3] "" Vector__XXX
 SG_ IVI_LVChrgFuncSW : 497|2@0+ (1,0) [0|3] "" Vector__XXX
 SG_ IVI_PwrLockSW : 499|2@0+ (1,0) [0|3] "" Vector__XXX
 SG_ IVI_CoastDwSW : 501|2@0+ (1,0) [0|3] "" Vector__XXX
 SG_ IVI_ActvDmpDisabSW : 503|2@0+ (1,0) [0|3] "" Vector__XXX
 SG_ Roll_Mode_SW_Cmd : 473|2@0+ (1,0) [0|3] "" ESC
 SG_ TCS_SW_Cmd : 475|2@0+ (1,0) [0|3] "" ESC
 SG_ SLIF_BUTT : 477|2@0+ (1,0) [0|2] "" FCM
 SG_ Roll_Eng_Mode : 478|1@0+ (1,0) [0|1] "" ESC
 SG_ SOC_Limit_Set : 468|5@0+ (2,50) [50|100] "%" Vector__XXX
 SG_ CDL_Lock_Butt : 469|1@0+ (1,0) [0|1] "" Vector__XXX
 SG_ CDL_Unlock_Butt : 470|1@0+ (1,0) [0|1] "" Vector__XXX
 SG_ SOC_ADJ_BUTT : 471|1@0+ (1,0) [0|1] "" Vector__XXX
 SG_ AC_Chg_Cur_Set : 462|7@0+ (1,5) [5|132] "A" Vector__XXX
 SG_ IVI_ISA_OffsetSpd : 451|4@0+ (1,0) [0|14] "" FCM
 SG_ RoomLampMode : 455|1@0+ (1,0) [0|1] "" Vector__XXX
 SG_ NAVI_SpeedLimit : 444|5@0+ (1,0) [0|31] "km/h" FCM
 SG_ NAVI_RoadClass : 447|3@0+ (1,0) [0|7] "" FCM
 SG_ NAVI_Tollgate : 427|12@0+ (1,0) [0|2000] "m" FCM
 SG_ NAVI_LinkClass : 431|4@0+ (1,0) [0|15] "" FCM
 SG_ NAVI_Tunnel : 411|12@0+ (1,0) [0|2000] "m" FCM
 SG_ NAVI_ForwardLinkLevel : 415|4@0+ (1,0) [0|15] "" FCM
 SG_ SenstivityPosition : 403|4@0+ (1,0) [0|15] "" Vector__XXX
 SG_ AVM_Parking_mode : 407|4@0+ (1,0) [0|15] "" Vector__XXX
 SG_ Hood_Latch_SW : 393|2@0+ (1,0) [0|3] "" Vector__XXX
 SG_ RCTA_BUTT : 396|2@0+ (1,0) [0|3] "" SRR_M
 SG_ IVI_Pwroff_req : 397|1@0+ (1,0) [0|1] "" Vector__XXX
 SG_ IVI_Trigger_req : 398|1@0+ (1,0) [0|1] "" Vector__XXX
 SG_ AVM_Err_STA : 399|1@0+ (1,0) [0|1] "" Vector__XXX
 SG_ NAVI_Distance_info : 375|24@0+ (1,0) [0|1.6777215E7] "m" Vector__XXX
 SG_ IVI_Mute_Sta : 360|1@0+ (1,0) [0|1] "" Vector__XXX
 SG_ IVI_PTG_USSta_SW : 361|1@0+ (1,0) [0|1] "" Vector__XXX
 SG_ IVI_WI_MAIN_SW : 362|1@0+ (1,0) [0|1] "" Vector__XXX
 SG_ IVI_RR_Def_Req : 363|1@0+ (1,0) [0|1] "" Vector__XXX
 SG_ IVI_Night_Mode_Sta : 364|1@0+ (1,0) [0|1] "" Vector__XXX
 SG_ IVI_Status : 365|1@0+ (1,0) [0|1] "" Vector__XXX
 SG_ LVDAMute_BUTT : 367|2@0+ (1,0) [0|3] "" FCM
 SG_ CAAS_Sw : 353|2@0+ (1,0) [0|3] "" Vector__XXX
 SG_ DSEAT_entryfun_set : 354|1@0+ (1,0) [0|1] "" Vector__XXX
 SG_ DSEAT_anti_set : 355|1@0+ (1,0) [0|1] "" Vector__XXX
 SG_ TPMS_Res_Butt : 357|1@0+ (1,0) [0|1] "" Vector__XXX
 SG_ FollowMeSW : 358|1@0+ (1,0) [0|1] "" Vector__XXX
 SG_ SetUnlockSingle : 359|1@0+ (1,0) [0|1] "" Vector__XXX
 SG_ IVI_PTG_Mode_SW : 345|2@0+ (1,0) [0|3] "" Vector__XXX
 SG_ IVI_PTG_Sta_SW : 347|2@0+ (1,0) [0|3] "" Vector__XXX
 SG_ SLG_Sw : 349|2@0+ (1,0) [0|3] "" Vector__XXX
 SG_ FS_Off_Sw : 351|2@0+ (1,0) [0|3] "" Vector__XXX
 SG_ PSEAT_vent_req : 338|3@0+ (1,0) [0|7] "" Vector__XXX
 SG_ FFogLampSW : 339|1@0+ (1,0) [0|1] "" Vector__XXX
 SG_ DSEAT_vent_req : 342|3@0+ (1,0) [0|7] "" Vector__XXX
 SG_ RFogLampSW : 343|1@0+ (1,0) [0|1] "" Vector__XXX
 SG_ MFRD_N_Bright_Req : 334|7@0+ (1,0) [0|100] "%" Vector__XXX
 SG_ User_p_download : 335|1@0+ (1,0) [0|1] "" Vector__XXX
 SG_ HeadLampSW : 321|2@0+ (1,0) [0|3] "" FCM
 SG_ NAVI_State : 323|2@0+ (1,0) [0|3] "" FCM
 SG_ Wifi_Sta_IVI_TBOX : 327|4@0+ (1,0) [0|15] "" Vector__XXX
 SG_ IVI_Panel_Y_Coor : 307|12@0+ (1,0) [0|4095] "" Vector__XXX
 SG_ IVI_Panel_X_Coor : 303|12@0+ (1,0) [0|4095] "" Vector__XXX
 SG_ NAVI_Cam_Dist_info : 295|8@0+ (1,0) [0|255] "m" Vector__XXX
 SG_ OFF_AC_MODE : 282|3@0+ (1,0) [0|7] "" Vector__XXX
 SG_ IVI_PW_Mode_Req : 284|2@0+ (1,0) [0|3] "" Vector__XXX
 SG_ User_p_upload : 285|1@0+ (1,0) [0|1] "" Vector__XXX
 SG_ CameraWrn : 286|1@0+ (1,0) [0|1] "" Vector__XXX
 SG_ Wifi_Reset : 287|1@0+ (1,0) [0|1] "" Vector__XXX
 SG_ NAVI_Direction_STA : 279|8@0+ (1,0) [0|255] "" Vector__XXX
 SG_ IVI_Screen : 269|6@0+ (1,0) [0|62] "" Vector__XXX
 SG_ TurnSwTimeSet : 271|2@0+ (1,0) [0|3] "" Vector__XXX
 SG_ Pressure_unit : 263|8@0+ (1,0) [0|255] "" Vector__XXX
 SG_ Time_system : 255|8@0+ (1,0) [0|255] "" Vector__XXX
 SG_ NAVI_Speed_Limit_A : 241|2@0+ (1,0) [0|3] "" Vector__XXX
 SG_ Temperature_unit : 242|1@0+ (1,0) [0|1] "" Vector__XXX
 SG_ Distance_unit : 243|1@0+ (1,0) [0|1] "" FCM,SRR_M
 SG_ ESC_SW_Cmd : 245|2@0+ (1,0) [0|3] "" ESC
 SG_ IVI_Panel_Act : 246|1@0+ (1,0) [0|1] "" Vector__XXX
 SG_ sigHvacRearReq : 247|1@0+ (1,0) [0|1] "" Vector__XXX
 SG_ FCWMute_BUTT : 233|2@0+ (1,0) [0|3] "" FCM
 SG_ LKA_BUTT : 235|2@0+ (1,0) [0|3] "" FCM
 SG_ ODAMute_BUTT : 237|2@0+ (1,0) [0|3] "" SRR_M
 SG_ LDWMute_BUTT : 239|2@0+ (1,0) [0|3] "" FCM
 SG_ BSDMute_BUTT : 225|2@0+ (1,0) [0|3] "" SRR_M
 SG_ sigWindDirZon3Req : 228|3@0+ (1,0) [0|7] "" Vector__XXX
 SG_ sigAirIntenZon3Req : 219|4@0+ (1,0) [0|15] "" Vector__XXX
 SG_ sigAirIntenZon1Req : 223|4@0+ (1,0) [0|15] "" Vector__XXX
 SG_ AEB_BUTT : 209|2@0+ (1,0) [0|3] "" FCM
 SG_ sigSetTempZon3Req : 215|6@0+ (0.5,17) [17|32] "Deg^C" Vector__XXX
 SG_ sigSetTempZon2Req : 205|6@0+ (0.5,17) [17|32] "Deg^C" Vector__XXX
 SG_ sigRecircReq : 206|1@0+ (1,0) [0|1] "" Vector__XXX
 SG_ sigHvacReq : 207|1@0+ (1,0) [0|1] "" Vector__XXX
 SG_ sigSetTempZon1Req : 197|6@0+ (0.5,17) [17|32] "Deg^C" Vector__XXX
 SG_ sigHvacFrontReq : 198|1@0+ (1,0) [0|1] "" Vector__XXX
 SG_ sigDfrstReq : 199|1@0+ (1,0) [0|1] "" Vector__XXX
 SG_ GPS_LAT : 167|32@0+ (1,0) [0|4.294967295E9] "SECOND" Vector__XXX
 SG_ GPS_LONG : 135|32@0+ (1,0) [0|4.294967295E9] "" Vector__XXX
 SG_ L_Drv_ControlCommand : 126|7@0+ (1,0) [0|127] "%" Vector__XXX
 SG_ TPMS_Cali_Butt : 127|1@0+ (1,0) [0|1] "" Vector__XXX
 SG_ L_Pas_ControlCommand : 118|7@0+ (1,0) [0|127] "%" Vector__XXX
 SG_ IVI_Unlock_Chg_req : 119|1@0+ (1,0) [0|1] "" Vector__XXX
 SG_ L_RLD_ControlCommand : 110|7@0+ (1,0) [0|127] "%" Vector__XXX
 SG_ IVI_Stop_Chg_req : 111|1@0+ (1,0) [0|1] "" Vector__XXX
 SG_ L_RRD_ControlCommand : 102|7@0+ (1,0) [0|127] "%" Vector__XXX
 SG_ IVI_Start_Chg_req : 103|1@0+ (1,0) [0|1] "" Vector__XXX
 SG_ METER_Malfunc_Sta : 89|2@0+ (1,0) [0|2] "" Vector__XXX
 SG_ sigFootReq : 90|1@0+ (1,0) [0|1] "" Vector__XXX
 SG_ sigFaceReq : 91|1@0+ (1,0) [0|1] "" Vector__XXX
 SG_ Sched_Chg_Start : 92|1@0+ (1,0) [0|1] "" Vector__XXX
 SG_ Sched_Chg_wake : 93|1@0+ (1,0) [0|1] "" Vector__XXX
 SG_ Sched_Chg_butt : 94|1@0+ (1,0) [0|1] "" Vector__XXX
 SG_ Sched_Chg_Stop : 95|1@0+ (1,0) [0|1] "" Vector__XXX
 SG_ Sched_Chg_limit : 84|5@0+ (2,50) [50|100] "%" Vector__XXX
 SG_ IVI_Req_V2L : 15|1@0+ (1,0) [0|1] "" Vector__XXX
 SG_ Perd_V2L : 3|4@0+ (1,0) [0|15] "" Vector__XXX
 SG_ SOC_V2LLimit : 7|4@0+ (5,20) [20|80] "%" Vector__XXX
 SG_ IVI_PTG_Open_Height : 14|3@0+ (1,0) [0|7] "" Vector__XXX
 SG_ IVI_CreepSW_Req : 11|1@0+ (1,0) [0|1] "" Vector__XXX
 SG_ FalseNPrevent_SW : 10|1@0+ (1,0) [0|1] "" Vector__XXX
 SG_ Approach_Unlock_SW : 9|1@0+ (1,0) [0|1] "" Vector__XXX
 SG_ Walkaway_Lock_SW : 8|1@0+ (1,0) [0|1] "" Vector__XXX

BO_ 1183 GW_IVI6: 8 FUSION
 SG_ IVI_Located_STA : 57|2@0+ (1,0) [0|3] "" Vector__XXX
 SG_ IVI_Time_Month : 51|4@0+ (1,0) [0|12] "MONTH" ESC,eBST,FCM,EPS,SRR_M,ABM
 SG_ IVI_Time_Hour : 44|5@0+ (1,0) [0|31] "HOUR" ESC,eBST,FCM,EPS,SRR_M,ABM
 SG_ IVI_Time_Day : 36|5@0+ (1,0) [0|31] "DAY" ESC,eBST,FCM,EPS,SRR_M,ABM
 SG_ IVI_Time_Second : 29|6@0+ (1,0) [0|63] "SECOND" ESC,eBST,FCM,EPS,SRR_M,ABM
 SG_ IVI_Time_Minute : 21|6@0+ (1,0) [0|63] "MINUTE" ESC,eBST,FCM,EPS,SRR_M,ABM
 SG_ IVI_Time_Year : 14|7@0+ (1,2000) [2000|2127] "YEAR" Vector__XXX
 SG_ IVI_Time_Check : 7|8@0+ (1,0) [0|255] "" ESC,eBST,FCM,EPS,SRR_M,ABM

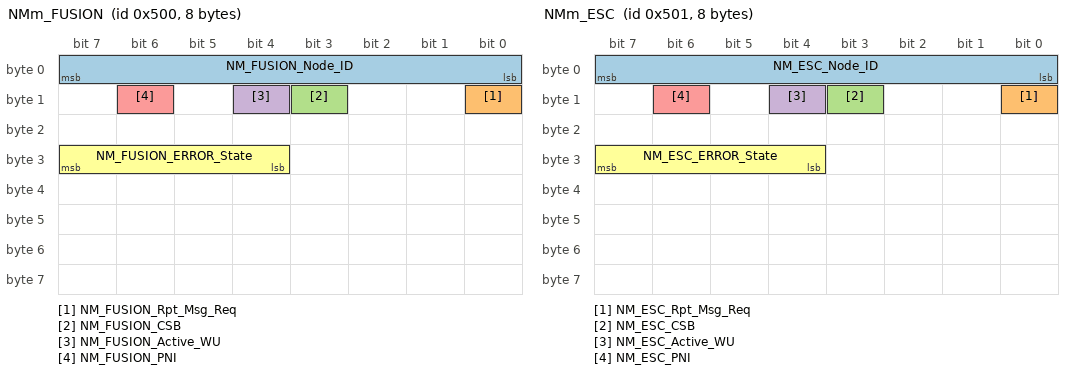
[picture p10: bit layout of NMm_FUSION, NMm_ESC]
BO_ 1280 NMm_FUSION: 8 FUSION
 SG_ NM_FUSION_Node_ID : 7|8@0+ (1,0) [0|127] "" ESC,eBST,FCM,EPS,SRR_M,ABM
 SG_ NM_FUSION_Rpt_Msg_Req : 8|1@0+ (1,0) [0|1] "" ESC,eBST,FCM,EPS,SRR_M,ABM
 SG_ NM_FUSION_CSB : 11|1@0+ (1,0) [0|1] "" ESC,eBST,FCM,EPS,SRR_M,ABM
 SG_ NM_FUSION_Active_WU : 12|1@0+ (1,0) [0|1] "" ESC,eBST,FCM,EPS,SRR_M,ABM
 SG_ NM_FUSION_PNI : 14|1@0+ (1,0) [0|1] "" ESC,eBST,FCM,EPS,SRR_M,ABM
 SG_ NM_FUSION_ERROR_State : 31|4@0+ (1,0) [0|8] "" ESC,eBST,FCM,EPS,SRR_M,ABM

BO_ 1281 NMm_ESC: 8 ESC
 SG_ NM_ESC_Node_ID : 7|8@0+ (1,0) [0|127] "" FUSION
 SG_ NM_ESC_Rpt_Msg_Req : 8|1@0+ (1,0) [0|1] "" FUSION
 SG_ NM_ESC_CSB : 11|1@0+ (1,0) [0|1] "" FUSION
 SG_ NM_ESC_Active_WU : 12|1@0+ (1,0) [0|1] "" FUSION
 SG_ NM_ESC_PNI : 14|1@0+ (1,0) [0|1] "" FUSION
 SG_ NM_ESC_ERROR_State : 31|4@0+ (1,0) [0|8] "" FUSION

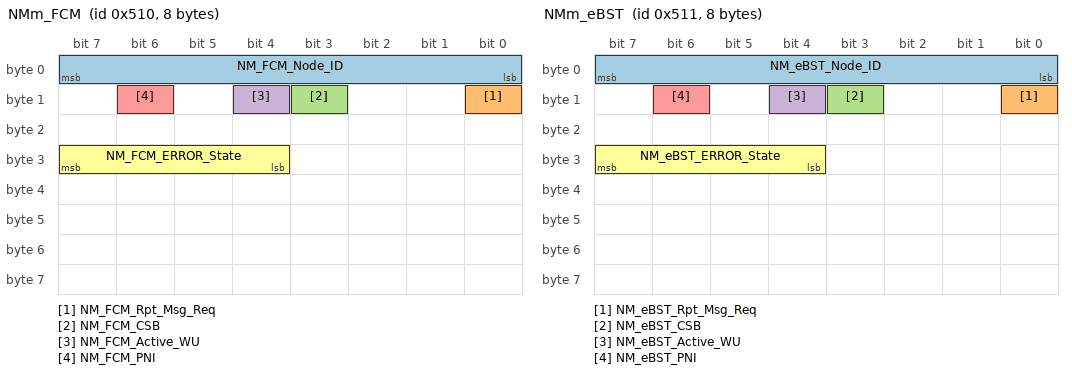
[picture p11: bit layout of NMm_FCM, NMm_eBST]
BO_ 1296 NMm_FCM: 8 FCM
 SG_ NM_FCM_Node_ID : 7|8@0+ (1,0) [0|127] "" FUSION
 SG_ NM_FCM_Rpt_Msg_Req : 8|1@0+ (1,0) [0|1] "" FUSION
 SG_ NM_FCM_CSB : 11|1@0+ (1,0) [0|1] "" FUSION
 SG_ NM_FCM_Active_WU : 12|1@0+ (1,0) [0|1] "" FUSION
 SG_ NM_FCM_PNI : 14|1@0+ (1,0) [0|1] "" FUSION
 SG_ NM_FCM_ERROR_State : 31|4@0+ (1,0) [0|8] "" FUSION

BO_ 1297 NMm_eBST: 8 eBST
 SG_ NM_eBST_Node_ID : 7|8@0+ (1,0) [0|127] "" FUSION
 SG_ NM_eBST_Rpt_Msg_Req : 8|1@0+ (1,0) [0|1] "" FUSION
 SG_ NM_eBST_CSB : 11|1@0+ (1,0) [0|1] "" FUSION
 SG_ NM_eBST_Active_WU : 12|1@0+ (1,0) [0|1] "" FUSION
 SG_ NM_eBST_PNI : 14|1@0+ (1,0) [0|1] "" FUSION
 SG_ NM_eBST_ERROR_State : 31|4@0+ (1,0) [0|8] "" FUSION

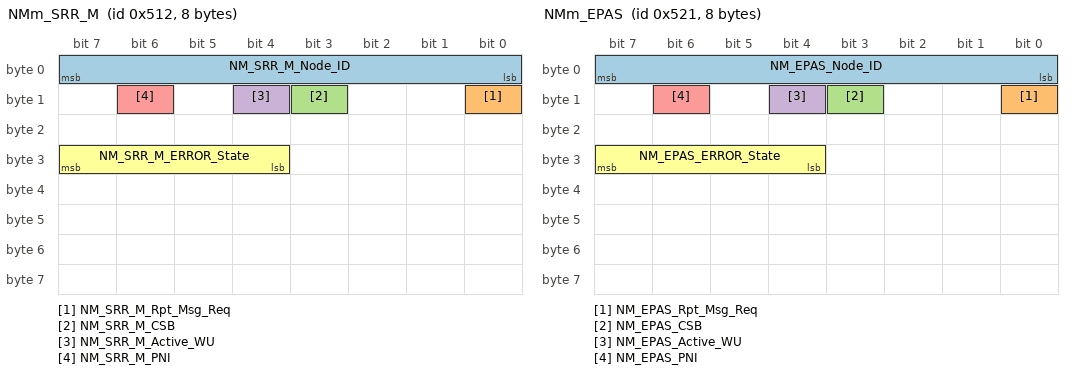
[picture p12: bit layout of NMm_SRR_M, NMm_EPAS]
BO_ 1298 NMm_SRR_M: 8 SRR_M
 SG_ NM_SRR_M_Node_ID : 7|8@0+ (1,0) [0|127] "" FUSION
 SG_ NM_SRR_M_Rpt_Msg_Req : 8|1@0+ (1,0) [0|1] "" FUSION
 SG_ NM_SRR_M_CSB : 11|1@0+ (1,0) [0|1] "" FUSION
 SG_ NM_SRR_M_Active_WU : 12|1@0+ (1,0) [0|1] "" FUSION
 SG_ NM_SRR_M_PNI : 14|1@0+ (1,0) [0|1] "" FUSION
 SG_ NM_SRR_M_ERROR_State : 31|4@0+ (1,0) [0|8] "" FUSION

BO_ 1313 NMm_EPAS: 8 EPS
 SG_ NM_EPAS_Node_ID : 7|8@0+ (1,0) [0|127] "" FUSION
 SG_ NM_EPAS_Rpt_Msg_Req : 8|1@0+ (1,0) [0|1] "" FUSION
 SG_ NM_EPAS_CSB : 11|1@0+ (1,0) [0|1] "" FUSION
 SG_ NM_EPAS_Active_WU : 12|1@0+ (1,0) [0|1] "" FUSION
 SG_ NM_EPAS_PNI : 14|1@0+ (1,0) [0|1] "" FUSION
 SG_ NM_EPAS_ERROR_State : 31|4@0+ (1,0) [0|8] "" FUSION

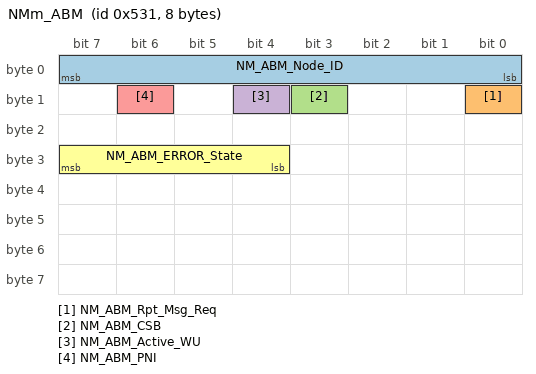
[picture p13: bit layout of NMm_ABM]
BO_ 1329 NMm_ABM: 8 ABM
 SG_ NM_ABM_Node_ID : 7|8@0+ (1,0) [0|127] "" FUSION
 SG_ NM_ABM_Rpt_Msg_Req : 8|1@0+ (1,0) [0|1] "" FUSION
 SG_ NM_ABM_CSB : 11|1@0+ (1,0) [0|1] "" FUSION
 SG_ NM_ABM_Active_WU : 12|1@0+ (1,0) [0|1] "" FUSION
 SG_ NM_ABM_PNI : 14|1@0+ (1,0) [0|1] "" FUSION
 SG_ NM_ABM_ERROR_State : 31|4@0+ (1,0) [0|8] "" FUSION

BO_ 1537 DiagRespFromESC: 8 ESC
 SG_ DiagRespFromESC : 7|64@0+ (1,0) [0|0] "" FUSION

BO_ 1552 DiagRespFromFCM: 8 FCM
 SG_ DiagRespFromFCM : 7|64@0+ (1,0) [0|0] "" FUSION

BO_ 1553 DiagRespFromeBST: 8 eBST
 SG_ DiagRespFromeBST : 7|64@0+ (1,0) [0|0] "" FUSION

BO_ 1554 DiagRespFromSRR_M: 8 SRR_M
 SG_ DiagRespFromSRR_M : 7|64@0+ (1,0) [0|0] "" FUSION

BO_ 1557 DiagRespFromMRR: 8 FCM
 SG_ DiagRespFromMRR : 7|64@0+ (1,0) [0|0] "" FUSION

BO_ 1569 DiagRespFromEPAS: 8 EPS
 SG_ DiagRespFromEPAS : 7|64@0+ (1,0) [0|0] "" FUSION

BO_ 1585 DiagRespFromABM: 8 ABM
 SG_ DiagRespFromABM : 7|64@0+ (1,0) [0|0] "" FUSION

BO_ 1665 DiagPhysReqToESC: 8 FUSION
 SG_ DiagPhysReqToESC : 7|64@0+ (1,0) [0|0] "" ESC

BO_ 1680 DiagPhysReqToFCM: 8 FUSION
 SG_ DiagPhysReqToFCM : 7|64@0+ (1,0) [0|0] "" FCM

BO_ 1681 DiagPhysReqToeBST: 8 FUSION
 SG_ DiagPhysReqToeBST : 7|64@0+ (1,0) [0|0] "" eBST

BO_ 1682 DiagPhysReqToSRR_M: 8 FUSION
 SG_ DiagPhysReqToSRR_M : 7|64@0+ (1,0) [0|0] "" SRR_M

BO_ 1685 DiagPhysReqToMRR: 8 FUSION
 SG_ DiagPhysReqToMRR : 7|64@0+ (1,0) [0|0] "" FCM

BO_ 1697 DiagPhysReqToEPAS: 8 FUSION
 SG_ DiagPhysReqToEPAS : 7|64@0+ (1,0) [0|0] "" EPS

BO_ 1713 DiagPhysReqToABM: 8 FUSION
 SG_ DiagPhysReqToABM : 7|64@0+ (1,0) [0|0] "" ABM

BO_ 2000 DiagFuncReqFT: 8 FUSION
 SG_ DiagFuncReqFT : 7|64@0+ (1,0) [0|0] "" ESC,eBST,FCM,EPS,SRR_M,ABM

BO_ 2002 XCPReqToESC: 8 FUSION
 SG_ XCPReqToESC : 7|64@0+ (1,0) [0|1.8446744073709551E19] "" ESC

BO_ 2003 XCPRespFromESC: 8 ESC
 SG_ XCPRespFromESC : 7|64@0+ (1,0) [0|1.8446744073709551E19] "" FUSION

BO_ 2004 XCPReqToeBST: 8 FUSION
 SG_ XCPReqToeBST : 7|64@0+ (1,0) [0|1.8446744073709551E19] "" eBST

BO_ 2005 XCPRespFromeBST: 8 eBST
 SG_ XCPRespFromeBST : 7|64@0+ (1,0) [0|1.8446744073709551E19] "" FUSION

BO_ 2040 CCP1ReqToEPAS: 8 FUSION
 SG_ CCP1ReqToEPAS : 7|64@0+ (1,0) [0|1.8446744073709551E19] "" EPS

BO_ 2041 CCP1RespFromEPAS: 8 EPS
 SG_ CCP1RespFromEPAS : 7|64@0+ (1,0) [0|1.8446744073709551E19] "" FUSION

BO_ 550 GW_ZoneDR1: 16 FUSION
 SG_ DrLockSta : 56|1@0+ (1,0) [0|1] "" Vector__XXX
 SG_ PsLockSta : 57|1@0+ (1,0) [0|1] "" Vector__XXX
 SG_ RLLockSta : 58|1@0+ (1,0) [0|1] "" Vector__XXX
 SG_ RRLockSta : 59|1@0+ (1,0) [0|1] "" Vector__XXX
 SG_ AllLockSta : 60|1@0+ (1,0) [0|1] "" Vector__XXX
 SG_ MIRROR_FOLD_SW : 61|1@0+ (1,0) [0|1] "" Vector__XXX
 SG_ RWiperAS : 62|1@0+ (1,0) [0|1] "" Vector__XXX
 SG_ RWiperProtection : 63|1@0+ (1,0) [0|1] "" Vector__XXX
 SG_ Wip_Speed : 49|2@0+ (1,0) [0|3] "" Vector__XXX
 SG_ CSW_RWipIntSw_Sta : 51|2@0+ (1,0) [0|3] "" Vector__XXX
 SG_ CSW_DimSw : 52|1@0+ (1,0) [0|1] "" FCM
 SG_ BrakeLampFail : 53|1@0+ (1,0) [0|1] "" Vector__XXX
 SG_ CSW_PassSW_Sta : 54|1@0+ (1,0) [0|1] "" FCM
 SG_ RLS_Exist : 55|1@0+ (1,0) [0|1] "" Vector__XXX
 SG_ RLTurnLampC : 47|8@0+ (10,0) [0|2550] "mA" Vector__XXX
 SG_ RRTurnLampC : 39|8@0+ (10,0) [0|2550] "mA" Vector__XXX
 SG_ CSW_FWasSw_Sta : 25|2@0+ (1,0) [0|3] "" Vector__XXX
 SG_ CSW_RWasSW_Sta : 27|2@0+ (1,0) [0|3] "" Vector__XXX
 SG_ CSW_TurnSw_Sta : 29|2@0+ (1,0) [0|3] "" FCM,SRR_M
 SG_ HornSW : 30|1@0+ (1,0) [0|1] "" Vector__XXX
 SG_ CSW_FWipSw_Sta : 18|3@0+ (1,0) [0|7] "" FCM
 SG_ RLS_RainSnrWiperCmd : 22|3@0+ (1,0) [0|7] "" Vector__XXX
 SG_ RLS_Lamp_Sta : 23|1@0+ (1,0) [0|1] "" Vector__XXX
 SG_ RLS_LIN_Resp_Err : 7|1@0+ (1,0) [0|1] "" Vector__XXX
 SG_ RLS_LightSnrErr : 6|1@0+ (1,0) [0|1] "" Vector__XXX
 SG_ RLS_RainSnrErr : 5|1@0+ (1,0) [0|1] "" Vector__XXX
 SG_ WiperSWPos : 15|8@0+ (1,0) [0|255] "" Vector__XXX
 SG_ WiperZeroPosSW : 4|1@0+ (1,0) [0|1] "" Vector__XXX
 SG_ AutoLightSW : 3|1@0+ (1,0) [0|1] "" Vector__XXX
 SG_ CSW_HW_version : 71|16@0+ (0.01,0) [0|99.99] "" Vector__XXX
 SG_ CSW_SW_version : 87|16@0+ (0.01,0) [0|99.99] "" Vector__XXX
 SG_ CSW_resp_error : 2|1@0+ (1,0) [0|1] "" Vector__XXX

CM_ BO_ 2002 "XCP Request to ESC";
CM_ BO_ 2003 "XCP Response From ESC";
CM_ SG_ 278 XWDMode "Driving Wheel Selection Mode (RWD/FWD/AWD)";
CM_ SG_ 278 LVPwrSta "LV Power Status";
CM_ SG_ 278 HVPwrSta "HV Power Status";
CM_ SG_ 278 PwrSta "Vehicle Power Status";
CM_ SG_ 278 PrkReq "Parking Request";
CM_ SG_ 278 ShiftGearPosn "EV Selector Position Status/ Selector Position Status Signal Failure";
CM_ SG_ 278 CC_Crl_Sta "Cruise Control Status";
CM_ SG_ 278 MSA_Crl_Sta "MSA Status";
CM_ SG_ 278 PrkReqValid "Parking Request Validity";
CM_ SG_ 278 P_Button_Sta "P demand pressed status";
CM_ SG_ 338 RearAxlTrqReq_Drv "Rear Axle DrivingTorque Limitation";
CM_ SG_ 338 FrntAxlTrqReq_Drv "Front Axle Driving Torque Limitation";
CM_ SG_ 338 VehSpeed "Vehicle Speed";
CM_ SG_ 338 Fr_PTCS_Active "Front Axle Torque Reduction Active";
CM_ SG_ 338 Rr_PTCS_Active "Rear Axle Torque Reduction Active";
CM_ SG_ 338 ESC1_RC "Rolling Counter of ESC1";
CM_ SG_ 338 ESC1_CS "Checksum of ESC1

complement = ((Sigma(first 15 halfbytes) + 2) XOR 0xFF)Checksum = complement MOD 0x10";
CM_ SG_ 339 FrntAxlTrqReq_Brk "Target Front Axle Braking Torque";
CM_ SG_ 339 RearAxlTrqReq_Brk "Target Rear Axle Braking Torque";
CM_ SG_ 339 BrkPedalPos "Brake Pedal Position";
CM_ SG_ 339 BrkPedalPos_Sta "Brake Pedal Position Status";
CM_ SG_ 339 RDC_Active "Regen Drag Control Active";
CM_ SG_ 339 Fr_RBC_Active "Front Regenerative Brake Control Active";
CM_ SG_ 339 Rr_RBC_Active "Rear Regenerative Brake Control Active";
CM_ SG_ 339 ESC7_RC "Rolling Counter";
CM_ SG_ 339 ESC7_CS "Checksum of ESC7

complement = ((Sigma(first 15 halfbytes) + 2) XOR 0xFF)Checksum = complement MOD 0x10";
CM_ SG_ 340 ActAPSPosn "Accelerator Actual Position";
CM_ SG_ 340 DriverTq "Driver's Torque";
CM_ SG_ 340 VehActPwr "Vehicle Actual Power";
CM_ SG_ 340 Rr_DriverTq "Driver's Torque on Rear Axle";
CM_ SG_ 340 Fr_DriverTq "Driver's Torque on Front Axle";
CM_ SG_ 340 AccPedal_Override "Drvier Acceleration (Pedal) Override";
CM_ SG_ 340 ACC_CtrlAvail "VCU available for ACC control";
CM_ SG_ 340 CS_VCU2_CAN1 "VCU2 frame checksum(SAEJ1850)
x^8+x^4+x^3+x^2+1 
It shall use 0xFF as the start value and XOR value.";
CM_ SG_ 340 RC_VCU2_CAN1 "VCU2 4-bit rolling counter";
CM_ SG_ 342 LF_RawWhlSpeed "Left Front Raw Wheel Speed";
CM_ SG_ 342 LF_RawWhlSpeed_V "Left Front Raw Wheel Speed Validity";
CM_ SG_ 342 LF_WhlRotDir "Left Front Wheel Rotation Direction";
CM_ SG_ 342 LF_PulseCount_V "Left Front Wheel Pulse Counter Validity";
CM_ SG_ 342 LF_PulseCount "Left Front Wheel Pulse Counter";
CM_ SG_ 342 RF_RawWhlSpeed "Right Front Raw Wheel Speed";
CM_ SG_ 342 RF_RawWhlSpeed_V "Right Front Raw Wheel Speed Validity";
CM_ SG_ 342 RF_WhlRotDir "Right Front Wheel Rotation Direction";
CM_ SG_ 342 RF_PulseCount_V "Right Front Wheel Pulse Counter Validity";
CM_ SG_ 342 RF_PulseCount "Right Front Wheel Pulse Counter";
CM_ SG_ 342 F_WhlSpeed_Count "Front Wheel Speed Life Counter";
CM_ SG_ 342 F_WhlSpeed_CRC_8 "Front Wheel Speed Checksum(SAE-J1850-CRC8)";
CM_ SG_ 343 LR_RawWhlSpeed "Left Rear Raw Wheel Speed";
CM_ SG_ 343 LR_RawWhlSpeed_V "Left Rear Raw Wheel Speed Validity";
CM_ SG_ 343 LR_WhlRotDir "Left Rear Wheel Rotation Direction";
CM_ SG_ 343 LR_PulseCount_V "Left Rear Wheel Pulse Counter Validity";
CM_ SG_ 343 LR_PulseCount "Left Rear Wheel Pulse Counter";
CM_ SG_ 343 RR_RawWhlSpeed "Right Rear Raw Wheel Speed";
CM_ SG_ 343 RR_RawWhlSpeed_V "Right Rear Raw Wheel Speed Validity";
CM_ SG_ 343 RR_WhlRotDir "Right Rear Wheel Rotation Direction";
CM_ SG_ 343 RR_PulseCount_V "Right Rear Wheel Pulse Counter Validity";
CM_ SG_ 343 RR_PulseCount "Right Rear Wheel Pulse Counter";
CM_ SG_ 343 R_WhlSpeed_Count "Rear Wheel Speed Life Counter";
CM_ SG_ 343 R_WhlSpeed_CRC_8 "Rear Wheel Speed Checksum(SAE-J1850-CRC8)";
CM_ SG_ 345 Fr_EDURealDrvOrBRgnTq "Front side driving or brake regen torque";
CM_ SG_ 345 Fr_EDUAvailBrkRgnTq "Front EDU(Electric Drive Unit) Available Braking Regeneration Torque (Maximum available regeneration torque - current rolling regeneration torque)";
CM_ SG_ 345 Fr_EDURealARgnTq "Front side real A-regen torque";
CM_ SG_ 345 Fr_EDUSpd "Front EDU(Electric Drive Unit) Rotational Speed(After Gearbox)";
CM_ SG_ 345 Fr_EDUAvailBrkRgnTqValid "Front EDU(Electric Drive Unit) Available Braking Regeneration Torque Validity";
CM_ SG_ 345 Rr_EDUAvailBrkRgnTqValid "Rear EDU(Electric Drive Unit) Available Braking Regeneration Torque Validity";
CM_ SG_ 345 Rr_EDURealDrvOrBRgnTq "Rear side driving or brake regen torque";
CM_ SG_ 345 Rr_EDUAvailBrkRgnTq "Rear EDU(Electric Drive Unit) Available Braking Regeneration Torque (Maximum available regeneration torque - current rolling regeneration torque)";
CM_ SG_ 345 Rr_EDURealARgnTq "Rear side real A-regen torque";
CM_ SG_ 345 Rr_EDUSpd "Rear EDU(Electric Drive Unit) Rotational Speed(After Gearbox)";
CM_ SG_ 345 EquivAccPedalSWSta "ADAS equivalent acceleration pedal switch status";
CM_ SG_ 345 PTCS_PermSta "Driving Torque Reduction Permission Status";
CM_ SG_ 345 Rr_RgnPermSta "Rear EDU Regeneration Permission Status";
CM_ SG_ 345 Fr_RgnPermSta "Front EDU Regeneration Permission Status";
CM_ SG_ 345 Rr_RgnDecrSta "Rear EDU Regeneration Decrease Status";
CM_ SG_ 345 Fr_RgnDecrSta "Front EDU Regeneration Decrease Status";
CM_ SG_ 345 RgnAbnorSta "Regeneration Abnormality Status";
CM_ SG_ 345 Rr_EDUSpdValid "Rear EDU Rotational Speed Validity";
CM_ SG_ 345 Fr_EDUSpdValid "Front EDU Rotational Speed Validity";
CM_ SG_ 345 RC_VCU3_CAN1 "VCU3 4-bit rolling counter";
CM_ SG_ 345 CS_VCU3_CAN1 "VCU3 frame checksum(SAEJ1850)
x^8+x^4+x^3+x^2+1 
It shall use 0xFF as the start value and XOR value.";
CM_ SG_ 360 LowBrakeFluid_Sta "Low Brake Fluid Status";
CM_ SG_ 360 eBST_AmberWnlmpSta "eBST Amber Warning Lamp Status";
CM_ SG_ 360 eBST_RedWnlmpSta "eBST Red Warning Lamp Status";
CM_ SG_ 360 eBST_BeepReq "eBST Beep Sound Request";
CM_ SG_ 377 FCM2_Checksum "The [CAN CheckSum] shall be calculated as a CRC8 with the following polynomial: x^8+x^4+x^3+x^2+1 (=0x1D), according with SAE-J1850-CRC8 Start value 0xFF";
CM_ SG_ 377 ACC_ComfortBandLower "Required acceleration lower limit - Comfort";
CM_ SG_ 377 ACC_JerkLowerLimit "Jerk lower limit - Jerk";
CM_ SG_ 377 ACC_ComfortBandUpper "Required acceleration upper limit - Comfort";
CM_ SG_ 377 ACC_JerkUpperLimit "Jerk upper limit - Jerk";
CM_ SG_ 377 ACC_RequiredAccel "Required acceleration";
CM_ SG_ 377 ADAS_AEBReq "AEB Request";
CM_ SG_ 377 FCM2_LifeCount "Rolling Counter of FCM2";
CM_ SG_ 377 ADAS_FaultSta "ADAS Fault Status";
CM_ SG_ 377 AEB_VehHoldReq "Vehicle Hold Request";
CM_ SG_ 377 ADAS_DBSReq "DBS request to ESC";
CM_ SG_ 377 ACC_VehHoldReq "ACC Hold Request";
CM_ SG_ 380 FCM3_Checksum "The [CAN CheckSum] shall be calculated as a CRC8 with the following polynomial: x^8+x^4+x^3+x^2+1 (=0x1D), according with SAE-J1850-CRC8 Start value 0xFF";
CM_ SG_ 380 ACC_ObjRelSpd "Object relative speed";
CM_ SG_ 380 ADAS_ForceIdle "Forced Idle";
CM_ SG_ 380 FCM3_LifeCount "Rolling Counter of FCM3";
CM_ SG_ 380 ACC_ObjDist "Object distance";
CM_ SG_ 380 ADAS_ShftPosnReq "Shifter Position Request";
CM_ SG_ 380 ADAS_ShftPosnReq_A "Shifter Position Request Applicable";
CM_ SG_ 380 ADAS_VehSpdLim "Vehicle Speed Limit(if Distance_unit = 0x0, then UNIT = km/h, else  UNIT = mph)";
CM_ SG_ 386 Rr_Coolanttemp "LLC coolant temp";
CM_ SG_ 386 Rr_Coolantflow "LLC coolant flow rate";
CM_ SG_ 386 FD_AGS_Cmd "Fusion Domain AGS Position Request";
CM_ SG_ 386 sigClntTHvBattOut "battery coolant outlet temperature";
CM_ SG_ 386 sigCbnSolarLeft "Measured cabin sun exposure";
CM_ SG_ 386 CabinMode "Cabin Mode";
CM_ SG_ 386 BatteryMode "Battery Mode";
CM_ SG_ 386 FD_RecyAuto_Cmd "Auto recycle command";
CM_ SG_ 386 sigCbnSolarRight "Measured cabin sun exposure";
CM_ SG_ 386 sigAmbAirT "Environment temperature (outside ambient vehicle temperature)";
CM_ SG_ 386 sigCbnAirT "Cabin air temperature";
CM_ SG_ 386 sigCbnPTCPwrAct "Current power consumption FRONT AirPTC";
CM_ SG_ 386 sigClmtCmprPwrAct "Current power consumption AC compressor";
CM_ SG_ 386 Fr_Coolantflow "LLC coolant flow rate";
CM_ SG_ 386 EDriveMode "E-Drive Mode";
CM_ SG_ 386 sigSetTempZon1St "Feedback: Temperature set in the HVAC for Zone 1";
CM_ SG_ 386 HPThermalRecoveryReq "Heat Pump thermal reuse request";
CM_ SG_ 386 sigSetTempZon2St "Feedback: Temperature set in the HVAC for Zone 2";
CM_ SG_ 386 sigHvacSt "Status of the HVAC (ON / OFF)";
CM_ SG_ 386 sigRecircSt "Recirculation Status in the HVAC (Fre/Rec/Auto)";
CM_ SG_ 386 sigSetTempZon3St "Feedback: Temperature set in the HVAC for Zone 3";
CM_ SG_ 386 sigDfrstSt "Defrost Status in the HVAC (ON / AUTO)";
CM_ SG_ 386 CCU_SyncLampSts "Climate SYNC lamp state";
CM_ SG_ 386 sigAirIntenZon3St "Feedback FAN Level/Air Intensirty : 0-Max or Auto for zone 3";
CM_ SG_ 386 sigAirIntenZon1St "Feedback FAN Level/Air Intensirty : 0-Max or Auto for zone 1";
CM_ SG_ 386 sigWindDirZon3St "Feedback: WInd DirectionZone 3. 
Feed, Body and/or Auto";
CM_ SG_ 386 CCU_FrtOnOffLampSts "Front Climate On Off lamp state";
CM_ SG_ 386 sigWindDirZon1St "Feedback: WInd DirectionZone 1. 
Feed, Body, WIndscreen and/or Auto";
CM_ SG_ 386 CCU_RrOnOffLampSts "Rear Climate On Off lamp state";
CM_ SG_ 386 Fr_Coolanttemp "LLC coolant temp";
CM_ SG_ 386 CCU_ACMaxLampSts "Climate AC Max lamp state";
CM_ SG_ 386 CCU_AutoLampSts "Climate air conditionning Front  automatic mode lamp state";
CM_ SG_ 386 CCU_AutoMidLampSts "Climate air conditionning middle left automatic mode lamp state";
CM_ SG_ 386 CCU_EcoSts "Economic mode status";
CM_ SG_ 386 CCU_Dispaly_Request "Air Conditioner display reuqest trigger";
CM_ SG_ 386 CCU_ACLampSts "Climate AC lamp state";
CM_ SG_ 386 CCU_HEATMaxLampSts "Climate HEATING Max lamp state";
CM_ SG_ 391 DriIntend "Driver Intend";
CM_ SG_ 391 EPS_AOI_Control "EPS AOI Control";
CM_ SG_ 391 EPS_TOI_Fault "EPS TOI Fault";
CM_ SG_ 391 EPAS1_LifeCount "Rolling Counter of EPAS1";
CM_ SG_ 391 EPAS1_Checksum "Checksum of EPAS1";
CM_ SG_ 410 SAS_Angle "Absoluted Steering Wheel Angle
(Positive value is clockwise.
When not being calibrated, invalid = 'FFFFh')";
CM_ SG_ 410 SAS_Speed "Steering Wheel rotation speed
(When not being, calibrated, this value = '0')";
CM_ SG_ 410 SAS_Speed_Valid "Steering Wheel rotation speed validity";
CM_ SG_ 410 SAS_CAL "SAS Calibrated Status";
CM_ SG_ 410 SAS_V "Steering Wheel Angle validity ( Status of Senosr Failure)";
CM_ SG_ 410 SAS_MsgCount "Number of the Message";
CM_ SG_ 410 SAS_CheckSum "SAS Checksum of all bytes of the CAN matrix";
CM_ SG_ 419 Red_WnlmpSta "Red Warning Lamp Status";
CM_ SG_ 419 ABS_WnlmpSta "ABS Warning Lamp Status";
CM_ SG_ 419 ESC_Off_lmpSta "ESC Off Warning Lamp Status";
CM_ SG_ 419 ESC_WnlmpSta "ESC Warning Lamp Status";
CM_ SG_ 419 GRADE "Surface Grade(dynamic)";
CM_ SG_ 419 EBD_Active "EBD System Active";
CM_ SG_ 419 ABS_Active "Antilock Brake System Active";
CM_ SG_ 419 TCS_Active "Traction Control System Active";
CM_ SG_ 419 ESC_Active "Electronic Stability Control Active";
CM_ SG_ 419 HBB_Active "Hydraulic Brake Boost Active";
CM_ SG_ 419 PBA_Active "Panic Brake Assist Active";
CM_ SG_ 419 HSA_Active "Hill Start Assist Active";
CM_ SG_ 419 AVH_Active "Auto Hold Active";
CM_ SG_ 419 Amber_WnlmpSta "Amber Warning Lamp Status";
CM_ SG_ 419 BTCS_Active "Brake Traction Control System Active";
CM_ SG_ 419 ESS_Active "Emergency Stop Signaling Active";
CM_ SG_ 419 HDD_Active "Hydraulic Dynamic Deceleration Active";
CM_ SG_ 419 EBD_Failed "EBD System Failed";
CM_ SG_ 419 ABS_Failed "Antilock Brake System Failed";
CM_ SG_ 419 TCS_Failed "Traction Control System Failed";
CM_ SG_ 419 ESC_Failed "Electronic Stability Control Failed";
CM_ SG_ 419 HBB_Failed "Hydraulic Brake Boost Failed";
CM_ SG_ 419 PBA_Failed "Panic Brake Assist Failed";
CM_ SG_ 419 HSA_Failed "Hill Start Assist Failed";
CM_ SG_ 419 AVH_Failed "Auto Hold Failed";
CM_ SG_ 419 HDD_Failed "Hydraulic Dynamic Deceleration Failed";
CM_ SG_ 419 ESC_OFF_Status "Electronic Stability Control OFF Status";
CM_ SG_ 419 ESC_BeepReq "ESC Beep Sound Request";
CM_ SG_ 419 SystemVoltage "Battery Voltage";
CM_ SG_ 421 YawRate "Yaw Rate";
CM_ SG_ 421 LatAccel "Lateral Acceleration";
CM_ SG_ 421 LongAccel "Longitudinal Acceleration";
CM_ SG_ 421 MCPressure "Master Cylinder Pressure";
CM_ SG_ 421 ESC5_RC "Rolling Counter of ESC5";
CM_ SG_ 421 ESC5_CRC8 "Checksum of ESC5 (SAE-J1850-CRC8)";
CM_ SG_ 421 YawRate_V "Yaw Rate Validity";
CM_ SG_ 421 LatAccel_V "Lateral Acceleration Validity";
CM_ SG_ 421 LongAccel_V "Longitudinal Acceleration Validity";
CM_ SG_ 421 MCPressure_V "Master Cylinder Pressure Validity";
CM_ SG_ 421 BrkSw_Sta "Brake switch signal status";
CM_ SG_ 421 BrkSw_V "Brake switch signal Vaild";
CM_ SG_ 425 Meter_Ind_VehSpeed "Meter Indicated Vehicle Speed";
CM_ SG_ 425 ACCAvail "ACC Availability";
CM_ SG_ 425 BrkDiscTempSta "Brake Disc Temperature Status";
CM_ SG_ 425 ESC_Standstill "Standstill Status for APS";
CM_ SG_ 425 DecErrSta "Deceleration Error Status";
CM_ SG_ 425 ActBrkLamp_Sta "Active Brake Lamp Status";
CM_ SG_ 425 AEBAvail "AEB Availability";
CM_ SG_ 425 ESC_ADAS_Sta "Resopnse Status to ADAS Request";
CM_ SG_ 425 ESC_APS_Sta "Response Status to APS Request";
CM_ SG_ 425 ESC6_RC "Rolling Counter of ESC6";
CM_ SG_ 425 ESC6_CS "Checksum of ESC6

complement = ((Sigma(first 15 halfbytes) + 2) XOR 0xFF)Checksum = complement MOD 0x10";
CM_ SG_ 427 EPBExtReleaseAvail "EPB External Release Availability";
CM_ SG_ 427 EPBExtApplyAvail "EPB External Control Availability";
CM_ SG_ 427 EPBCarWashMode "EPB Car Wash Mode";
CM_ SG_ 427 DOA_Sta "Door Open Apply Status";
CM_ SG_ 427 EPBStaL "Electric Parking Brake Status Left";
CM_ SG_ 427 TakeOverReq "Backup EPB Take Over Request";
CM_ SG_ 427 EPBStaR "Electric Parking Brake Status Right";
CM_ SG_ 427 EPBErrSta "EPB Error Status";
CM_ SG_ 427 EPBRLampSta "EPB Red Lamp Status";
CM_ SG_ 427 EPBSta "Electric Parking Brake Status";
CM_ SG_ 427 EPBMsg "EPB Message";
CM_ SG_ 427 EPB1_RC "Rolling Counter of EPB1";
CM_ SG_ 427 EPB1_CS "Checksum of EPB1

complement = ((£U(first 15 halfbytes) + 2) XOR 0xFF)Checksum = complement MOD 0x10";
CM_ SG_ 515 AirBagFailCmd "Airbag system lamp status";
CM_ SG_ 515 DriverSeatBeltCmd "Driver Seat Belt lamp status";
CM_ SG_ 515 PsngrSeatBeltCmd "Passenger Seat Belt lamp status";
CM_ SG_ 515 PABSwitchCmd "PAB Switch lamp status";
CM_ SG_ 515 RDriverSeatBeltCmd "Rear driver seat belt lamp status";
CM_ SG_ 515 RPsngrSeatBeltCmd "Rear passenger seat belt lamp status";
CM_ SG_ 515 RCenterSeatBeltCmd "Rear center seat belt lamp status";
CM_ SG_ 515 TLHPsngrSeatBeltCmd "Third LH seatbelt lamp status";
CM_ SG_ 515 TRHPsngrSeatBeltCmd "Third RH seatbelt lamp status";
CM_ SG_ 515 CrashOutputSts "Crash Output Status";
CM_ SG_ 515 LifeCount_ABM1 "RollingCounter of ABM";
CM_ SG_ 515 Checksum_ABM1 "Check sum of ABM";
CM_ SG_ 517 SRR1_Chksum "Checksum of SRR1";
CM_ SG_ 517 SRR_RCTA_WarnR "RCTA Warning Right";
CM_ SG_ 517 SRR_RCTA_WarnL "RCTA Warning Left";
CM_ SG_ 517 SRR_BSD_WarnR "BSD Warning Right";
CM_ SG_ 517 SRR_BSD_WarnL "BSD Warning Left";
CM_ SG_ 517 SRR_BSD_SoundR "BSD Sound Right";
CM_ SG_ 517 SRR_BSD_SoundL "BSD Sound Left";
CM_ SG_ 517 SRR_BSD_Mute "BSD Mute status";
CM_ SG_ 517 SRR_ODA_WarnR "ODA Warning Right";
CM_ SG_ 517 SRR_ODA_WarnL "ODA Warning Left";
CM_ SG_ 517 SRR_ODA_SoundR "ODA Sound Right";
CM_ SG_ 517 SRR_ODA_SoundL "ODA Sound Left";
CM_ SG_ 517 SRR_ODA_Mute "ODA Mute Status";
CM_ SG_ 517 SRR_ODA_Sta "Status of ODA";
CM_ SG_ 517 SRR_BSD_Sta "Status of BSD";
CM_ SG_ 517 SRR_RCTA_Sta "Status of RCTA";
CM_ SG_ 517 SRR_FltWrnReq "SRR Fault Warning Request";
CM_ SG_ 517 SRR1_LifeCount "Rolling Counter of SRR1";
CM_ SG_ 528 PAS_A_FCL "To show the level of distance detected from sensor FCL";
CM_ SG_ 528 PAS_Chime "The types of chime for PSS system";
CM_ SG_ 528 APS_Progress_PCT "information for show the APA operation percentage";
CM_ SG_ 528 APS_RQ_Display "Request to show the APA operation";
CM_ SG_ 528 PAS_D_RMR "To show the distance detected from sensor RMR";
CM_ SG_ 528 PAS_D_RML "To show the distance detected from sensor RML";
CM_ SG_ 528 PAS_D_RCR "To show the distance detected from sensor RCR";
CM_ SG_ 528 PAS_D_RCL "To show the distance detected from sensor RCL";
CM_ SG_ 528 APS_SW_Ver "APS Software Version Number";
CM_ SG_ 528 APS_HW_Ver "APS Hardware Version Number";
CM_ SG_ 528 APS_ExitCondition "APS Disable Cause";
CM_ SG_ 528 PAS_D_FMR "To show the distance detected from sensor FMR";
CM_ SG_ 528 PAS_D_FML "To show the distance detected from sensor FML";
CM_ SG_ 528 PAS_D_FCR "To show the distance detected from sensor FCR";
CM_ SG_ 528 PAS_D_FCL "To show the distance detected from sensor FCL";
CM_ SG_ 528 APS_D_RLR "To show the distance detected from sensor RLR";
CM_ SG_ 528 APS_D_RLL "To show the distance detected from sensor RLL";
CM_ SG_ 528 APS_D_FLR "To show the distance detected from sensor FLR";
CM_ SG_ 528 APS_D_FLL "To show the distance detected from sensor FLL";
CM_ SG_ 528 PAS_SNSR_Layout "To show the sensor layout";
CM_ SG_ 528 PAS_A_RMR "To show the level of distance detected from sensor RMR";
CM_ SG_ 528 PAS_A_RML "To show the level of distance detected from sensor RML";
CM_ SG_ 528 PAS_A_RCR "To show the level of distance detected from sensor RCR";
CM_ SG_ 528 PAS_A_RCL "To show the level of distance detected from sensor RCL";
CM_ SG_ 528 PAS_A_FMR "To show the level of distance detected from sensor FMR";
CM_ SG_ 528 PAS_A_FML "To show the level of distance detected from sensor FML";
CM_ SG_ 528 PAS_A_FCR "To show the level of distance detected from sensor FCR";
CM_ SG_ 528 PAS_Sta_F_Sys "PBS_SYS_FAIL";
CM_ SG_ 528 PAS_Mod_Operation "To show the operation mode of system";
CM_ SG_ 528 USS_Sta_RMR "USS RMR Fault status";
CM_ SG_ 528 USS_Sta_RML "USS RML Fault status";
CM_ SG_ 528 USS_Sta_RLR "USS RLR Fault status";
CM_ SG_ 528 USS_Sta_RLL "USS RLL Fault status";
CM_ SG_ 528 USS_Sta_RCR "USS RCR Fault status";
CM_ SG_ 528 USS_Sta_RCL "USS RCL Fault status";
CM_ SG_ 528 USS_Sta_FMR "USS FMR Fault status";
CM_ SG_ 528 USS_Sta_FML "USS FML Fault status";
CM_ SG_ 528 USS_Sta_FLR "USS FLR Fault status";
CM_ SG_ 528 USS_Sta_FLL "USS FLL Fault status";
CM_ SG_ 528 USS_Sta_FCR "USS FCR Fault status";
CM_ SG_ 528 USS_Sta_FCL "USS FCL Fault status";
CM_ SG_ 534 DrDoorSW "Driver Side Door Switch";
CM_ SG_ 534 PsDoorSW "Passenger Side Door Switch";
CM_ SG_ 534 RLDoorSW "Rear Left Door Switch";
CM_ SG_ 534 RRDoorSW "Rear Right Door Switch";
CM_ SG_ 534 AllDoorSW "All Door Switch";
CM_ SG_ 534 DoorLockIND "Door Lock Indicator";
CM_ SG_ 534 HoodSW "Hood Switch";
CM_ SG_ 534 Tailgate_SW "Tailgate Switch";
CM_ SG_ 534 CTDCtrl "Door Lock Control";
CM_ SG_ 534 Fr_ChargingDoorCtrl "Front Charging Door Control";
CM_ SG_ 534 Rr_ChargingDoorCtrl "Rear Charging Door Control";
CM_ SG_ 534 CTDLockSW "Central Door Lock SW";
CM_ SG_ 534 CTDUnlockSW "Central Door Unlock SW";
CM_ SG_ 534 MirrorDefog "Mirror Defog";
CM_ SG_ 534 Rr_Defog "Rear Defog";
CM_ SG_ 534 TrunkRel "Trunk Release";
CM_ SG_ 534 TailgateHDSW "Tailgate Handle SW";
CM_ SG_ 534 MirrorCtrl "Mirror Control";
CM_ SG_ 534 Fr_Wiper_H "Front Wiper High";
CM_ SG_ 534 Fr_Wiper_L "Front Wiper LOW";
CM_ SG_ 534 Rr_Wiper "Rear Wiper";
CM_ SG_ 534 WiperFixMode "Wiper Fix Mode";
CM_ SG_ 534 WasherCtrl "WasherControl";
CM_ SG_ 534 L_Beam "Low Beam";
CM_ SG_ 534 H_Beam "High Beam";
CM_ SG_ 534 PosLamp "PositionLamp";
CM_ SG_ 534 LDRL "Left DRL";
CM_ SG_ 534 RDRL "Right DRL";
CM_ SG_ 534 ReverseLamp "ReverseLamp";
CM_ SG_ 534 BrakeLamp "BrakeLamp";
CM_ SG_ 534 LBSD "Left BSD";
CM_ SG_ 534 RBSD "Right BSD";
CM_ SG_ 534 Fr_FogLamp "Front Fog Lamp";
CM_ SG_ 534 Rr_FogLamp "Rear Fog Lamp";
CM_ SG_ 534 HazardSW "Hazard SW";
CM_ SG_ 534 LTurnLP "Left Turn Lamp";
CM_ SG_ 534 RTurnLP "Right Turn Lamp";
CM_ SG_ 534 AntitheftSta "Anti-theft Status";
CM_ SG_ 534 AntiTheftSeatFold "Anti-theft Seat Fold";
CM_ SG_ 534 Dimmer "Dimmer";
CM_ SG_ 534 LockSetting "BCM Unlock Single Door Setting";
CM_ SG_ 534 BCM_Buzzer_Req "BCM Buzzer Request";
CM_ SG_ 534 TailgateRemote "Remote Control PTG";
CM_ SG_ 534 RoomLampL "Room Lamp Low";
CM_ SG_ 534 RoomLampH "Room Lamp High";
CM_ SG_ 534 DimmerEN "Dimmer Enable";
CM_ SG_ 534 BCM_DoorLock_Sta "BCM Unlock Single Door Setting";
CM_ SG_ 534 HornCtrl "Horn Control";
CM_ SG_ 534 CrashDetd "Crash Detected";
CM_ SG_ 534 L_APM_WdwEnable "Enable windows movement";
CM_ SG_ 553 EPS_Pwr_Consumpt "EPS Power Consumption";
CM_ SG_ 553 EPS_Pwr_Consumpt_V "EPS Power Consumption Validity";
CM_ SG_ 553 EPS_VOL_V "EPS Voltage Validity";
CM_ SG_ 553 EPS_Temp_V "EPS Temperature Validity";
CM_ SG_ 553 EpasFailed "Epas Failed";
CM_ SG_ 553 EPS_Pwr_Limit_V "EPS Power Limit Validity";
CM_ SG_ 553 Steering_Torque_V "Steering Torque Validity";
CM_ SG_ 553 EPS_Temp "EPS Temperature";
CM_ SG_ 553 EPS_VOL "EPS Voltage";
CM_ SG_ 553 Steering_Torque "Steering Torque(Positive value is clockwise.)";
CM_ SG_ 553 EPS_Pwr_Limit "EPS Power Limit";
CM_ SG_ 566 APS_Angle_Target "to indicate the target steering angle(Positive value is clockwise.
When not being calibrated, invalid = 'FFFFh')";
CM_ SG_ 566 APS_Sta_System "The operation status of APA system";
CM_ SG_ 566 APS_V_Rq_EPAS_Ctrl "to indicate if the signal Request Active is valid or not";
CM_ SG_ 566 APS_Rq_EPAS_Ctrl "This signal is used when the APA need to control the steering wheel";
CM_ SG_ 568 APS_Req "ESC control request";
CM_ SG_ 568 SPTG_Sta "The operation status of SPTG";
CM_ SG_ 568 APS_DecReq "APS Vehicle Deceleration Request";
CM_ SG_ 568 CAAS_Sta "The operation status of CAAS";
CM_ SG_ 568 APS_DecReq_A "APS Vehicle Deceleration Request Applicable";
CM_ SG_ 568 SPTGDet "Smart PTG Detecting";
CM_ SG_ 568 APSOpenPTG "Smart PTG open request";
CM_ SG_ 568 APS3_checksum "checksum of APS3 (SAE-J1850-CRC8)
The [CAN CheckSum] shall be calculated as a CRC8 with the following polynomial: x^8+x^4+x^3+x^2+1 (=0x1D), according with SAE-J1850-CRC8 Start value 0xFF";
CM_ SG_ 568 APS3_LifeCount "Rolling counter of APS3";
CM_ SG_ 570 FCM4_Checksum "The [CAN CheckSum] shall be calculated as a CRC8 with the following polynomial: x^8+x^4+x^3+x^2+1 (=0x1D), according with SAE-J1850-CRC8 Start value 0xFF";
CM_ SG_ 570 ADAS_SLIF_SpdLim "ADAS SLIF Speed Limitation";
CM_ SG_ 570 Target_Type "Target Type";
CM_ SG_ 570 ADAS_CAM_SpdLim "ADAS Camera Speed Limitation";
CM_ SG_ 570 ADAS_WarningMsg "ADAS Warning Message";
CM_ SG_ 570 ACC_TakeoverReq "ACC takeover request";
CM_ SG_ 570 ACCSetSpeed_Disp "ACC Set Speed Display";
CM_ SG_ 570 ACCSetSpeed "ACC Set Speed(if Distance_unit = 0x0, then UNIT = km/h, else  UNIT = mph)";
CM_ SG_ 570 TimeGapLevel "Time Gap Level";
CM_ SG_ 570 ForceLowBeam "Force Low Beam";
CM_ SG_ 570 ACC_ObjDstLvl "Object distance level (lvl.1 ~ lvl.4)";
CM_ SG_ 570 ADAS_ACC_Sta "ACC Status";
CM_ SG_ 570 ADAS_FltWrnReq "ADAS Fault Warning Request";
CM_ SG_ 570 ADAS_LDW_Sta "LDW Status";
CM_ SG_ 570 LeftTurnLightReq "Left Turning Light Request";
CM_ SG_ 570 ADAS_FCW_Sta "FCW Status";
CM_ SG_ 570 RightTurnLightReq "Right Turning Light Request";
CM_ SG_ 570 ADAS_AEB_Sta "AEB Status";
CM_ SG_ 570 HazardWarningReq "Hazard Warning Request";
CM_ SG_ 572 FCM5_Checksum "The [CAN CheckSum] shall be calculated as a CRC8 with the following polynomial: x^8+x^4+x^3+x^2+1 (=0x1D), according with SAE-J1850-CRC8 Start value 0xFF";
CM_ SG_ 572 ADAS_LFC_Warn_Sound "LFC Warning Sound";
CM_ SG_ 572 LVDA_ACCStatusInformation "ACC status information for LVDA";
CM_ SG_ 572 LVDA_Warning "LVDA Warning";
CM_ SG_ 572 LVDA_Failinfo "LVDA Failinfo";
CM_ SG_ 572 LVDA_Mute_Sta "LVDA USM Setting";
CM_ SG_ 572 LVDA_Disabled "LVDA_Disabled";
CM_ SG_ 572 ADAS_LFC_Hands_Off_Warning "LFC Hands-Off Warning";
CM_ SG_ 572 ADAS_FCW_Mute "FCW Mute Status";
CM_ SG_ 572 ADAS_LDW_Mute "LDW Mute Status";
CM_ SG_ 572 ADAS_ISA_Sta "ISA Status";
CM_ SG_ 572 ADAS_SLIF_Sta "SLIF Status";
CM_ SG_ 572 ADAS_LaneModeR "Right Lane Mode";
CM_ SG_ 572 ADAS_LaneModeL "Left Lane Mode";
CM_ SG_ 572 ADAS_LFC_Sta "LFC Status";
CM_ SG_ 572 LKA_HOD_Sound_Warning "LKA hands-off detection sound warning signal";
CM_ SG_ 572 ADAS_LKA_Sta "LKA Status";
CM_ SG_ 572 LKA_HOD_Display_Warning "LKA hands-off detection display warning signal";
CM_ SG_ 602 ODOMETER "Odometer";
CM_ SG_ 602 Trip_A "TripA";
CM_ SG_ 602 Trip_B "TripB";
CM_ SG_ 602 ParkBrake "Park Brake";
CM_ SG_ 602 Charge "Charge";
CM_ SG_ 602 LEDlitWarnReq "LED lit Warning Request";
CM_ SG_ 602 Spd_Crl_Sta "Speed Control Function Status";
CM_ SG_ 602 Spd_Crl_Mode "Speed Control Function Mode";
CM_ SG_ 602 AvailableTrip "Distance to Empty";
CM_ SG_ 602 AVGPwrConsumption "average power consumption";
CM_ SG_ 602 Averaged_vehspeed "Averaged_vehspeed";
CM_ SG_ 602 METER_MPH_Real "METER Real Speed(MPH)";
CM_ SG_ 602 METER_KPH_Real "METER Real Speed(KPH)";
CM_ SG_ 602 METER_MPH_Calcu "METER Calculated Speed(MPH)";
CM_ SG_ 602 METER_KPH_Calcu "METER Calculated Speed(KPH)";
CM_ SG_ 659 Set_Spd "speed setting under speed control function";
CM_ SG_ 659 RegenMode "Regen Mode";
CM_ SG_ 659 Zone_Spd_Ctrl_Sta "Speed Control Function Status";
CM_ SG_ 659 Zone_Spd_Ctrl_Mode "Speed Control Function Mode";
CM_ SG_ 659 DrSCPSysErrLmp "SCP system error lamp  request ";
CM_ SG_ 826 SWC_LKA_Sta "LKA Button Status";
CM_ SG_ 826 SWC_Undefined_Sta "Undefined button Status";
CM_ SG_ 826 SWC_VR_Sta "VR Button Status";
CM_ SG_ 826 SWC_Up_Sta "UP Button Status";
CM_ SG_ 826 SWC_Trip_Sta "Trip Button Status";
CM_ SG_ 826 SWC_Set_down_Sta "SET down Button Status";
CM_ SG_ 826 SWC_Right_Sta "Seek Forward track/radio";
CM_ SG_ 826 SWC_RegenDown "Regen Down";
CM_ SG_ 826 SWC_Res_Up_Sta "Res up Button Status";
CM_ SG_ 826 SWC_mode_Sta "Mode Button Status";
CM_ SG_ 826 SWC_Left_Sta "Seek Backward track/radio";
CM_ SG_ 826 SWC_RegenUp "Regen Up";
CM_ SG_ 826 SWC_Down_Sta "DOWN Button Status";
CM_ SG_ 826 SWC_Distance_Sta "Distance Button Status";
CM_ SG_ 826 SWC_ACC_Sta "ACC Button Status";
CM_ SG_ 826 SWC_CANCEL_Sta "CANCEL Button Status";
CM_ SG_ 960 VehMalfunLevel "Vehicle malfunction level";
CM_ SG_ 960 Eng_AGSCloseSta "AGS close display status";
CM_ SG_ 960 Eng_PwrLockSta "power lock display status";
CM_ SG_ 960 Eng_CoastDwSta "coast down tq map display status";
CM_ SG_ 960 Eng_ActvDmpDisabSta "MCU active damping disable display status";
CM_ SG_ 1173 AVM_parking_cancel "auto parking cancel";
CM_ SG_ 1173 AVM_parking_excute "confirm and start to auto parking";
CM_ SG_ 1173 AVM_OFF_Rec_Butt "AVM KEYOFF Recording Button";
CM_ SG_ 1173 IVI_AGSCloseSW "IVI AGS close switch";
CM_ SG_ 1173 IVI_LVChrgFuncSW "IVI LV Charging function switch";
CM_ SG_ 1173 IVI_PwrLockSW "IVI Power State Lock Switch";
CM_ SG_ 1173 IVI_CoastDwSW "IVI Coastdown switch";
CM_ SG_ 1173 IVI_ActvDmpDisabSW "IVI Active Damping Disable Switch";
CM_ SG_ 1173 Roll_Mode_SW_Cmd "Roll Mode Switch command";
CM_ SG_ 1173 TCS_SW_Cmd "TCS Switch command";
CM_ SG_ 1173 SLIF_BUTT "SLIF  ON/OFF Buttom";
CM_ SG_ 1173 Roll_Eng_Mode "Roll Engine Mode";
CM_ SG_ 1173 SOC_Limit_Set "SOC Charging Limitation Setting";
CM_ SG_ 1173 CDL_Lock_Butt "Central Door Lock_LOCK_Button";
CM_ SG_ 1173 CDL_Unlock_Butt "Central Door Lock_UNLOCK_Button";
CM_ SG_ 1173 SOC_ADJ_BUTT "SOC Charging Limitation Adjust Button";
CM_ SG_ 1173 AC_Chg_Cur_Set "AC Charging Current Setting";
CM_ SG_ 1173 IVI_ISA_OffsetSpd "IVI ISA Offset speed";
CM_ SG_ 1173 RoomLampMode "Room lampt on/off connected with car door open/close";
CM_ SG_ 1173 NAVI_SpeedLimit "Information for Current Link Speed Limit expressed as km/h or mph";
CM_ SG_ 1173 NAVI_RoadClass "Information for Road Class";
CM_ SG_ 1173 NAVI_Tollgate "Information for Tollgate exist (Exist information shall be informed 500m ahead)";
CM_ SG_ 1173 NAVI_LinkClass "Information for Link Class Value of Segment";
CM_ SG_ 1173 NAVI_Tunnel "Information for Tunnel exist (Exist information shall be informed 500m ahead)";
CM_ SG_ 1173 NAVI_ForwardLinkLevel "Information for Forward Link Level in Freeway (Change information shall be informed 500m ahead)";
CM_ SG_ 1173 SenstivityPosition "wiper Senstivity Position";
CM_ SG_ 1173 AVM_Parking_mode "AVM_Parking Mode";
CM_ SG_ 1173 Hood_Latch_SW "Hood Latch Switch";
CM_ SG_ 1173 RCTA_BUTT "RCTA ON/OFF Button";
CM_ SG_ 1173 IVI_Pwroff_req "IVI Power off request";
CM_ SG_ 1173 IVI_Trigger_req "IVI Trigger VCU to Ready request";
CM_ SG_ 1173 AVM_Err_STA "AVM Error Status";
CM_ SG_ 1173 NAVI_Distance_info "NAVI Distance Information";
CM_ SG_ 1173 IVI_Mute_Sta "IVI Mute status";
CM_ SG_ 1173 IVI_PTG_USSta_SW "Power Tail Gate Ultrasonic On/Off Switch";
CM_ SG_ 1173 IVI_WI_MAIN_SW "IVI Wiper Maintance_Switch";
CM_ SG_ 1173 IVI_RR_Def_Req "IVI Rear Deffogger Status";
CM_ SG_ 1173 IVI_Night_Mode_Sta "IVI Night Mode Status";
CM_ SG_ 1173 IVI_Status "IVI Status";
CM_ SG_ 1173 LVDAMute_BUTT "LDW Mute Buttom";
CM_ SG_ 1173 CAAS_Sw "Collision Avoidance Assistance System Switch Status";
CM_ SG_ 1173 DSEAT_entryfun_set "Driver Seat Entry on/off request";
CM_ SG_ 1173 DSEAT_anti_set "Driver Seat Antitheft on/off request";
CM_ SG_ 1173 TPMS_Res_Butt "TPMS_Reset_button";
CM_ SG_ 1173 FollowMeSW "Follow Me Home SW";
CM_ SG_ 1173 SetUnlockSingle "Single Set Unlock DOOR SETTING";
CM_ SG_ 1173 IVI_PTG_Mode_SW "Power Tail Gate Manual and Automatic mode Switch";
CM_ SG_ 1173 IVI_PTG_Sta_SW "Power Tail Gate Open and Close Switch";
CM_ SG_ 1173 SLG_Sw "Smart liftgate Switch Status";
CM_ SG_ 1173 FS_Off_Sw "F_USS Switch Status";
CM_ SG_ 1173 PSEAT_vent_req "Passenger Seat Ventilate request
0= No Request,
1= Vent1,
2= Vent2,
3= Vent3,
4= Off";
CM_ SG_ 1173 FFogLampSW "Front Fog Lamp Switch";
CM_ SG_ 1173 DSEAT_vent_req "Driver Seat ventilate request";
CM_ SG_ 1173 RFogLampSW "Rear Fog Lamp Switch";
CM_ SG_ 1173 MFRD_N_Bright_Req "MFRD night Brightness setting";
CM_ SG_ 1173 User_p_download "User profile download";
CM_ SG_ 1173 HeadLampSW "Head Lamp Switch";
CM_ SG_ 1173 NAVI_State "Information for Navigation Status";
CM_ SG_ 1173 Wifi_Sta_IVI_TBOX "Wifi signal status between IVI and TBOX";
CM_ SG_ 1173 IVI_Panel_Y_Coor "IVI Touch Panel Y coordinate";
CM_ SG_ 1173 IVI_Panel_X_Coor "IVI Touch Panel X coordinate";
CM_ SG_ 1173 NAVI_Cam_Dist_info "Navigation speed camera distance information";
CM_ SG_ 1173 OFF_AC_MODE "OFF AC MODE";
CM_ SG_ 1173 IVI_PW_Mode_Req "IVI Power Mode require";
CM_ SG_ 1173 User_p_upload "User profile upload";
CM_ SG_ 1173 CameraWrn "Speed cameras Warming";
CM_ SG_ 1173 Wifi_Reset "Wifi Reset between VIG and OBU";
CM_ SG_ 1173 NAVI_Direction_STA "NAVI Direction Status";
CM_ SG_ 1173 IVI_Screen "IVI Screen
0x1d~0x3E:undefined";
CM_ SG_ 1173 TurnSwTimeSet "turning switch flash time set";
CM_ SG_ 1173 Pressure_unit "Pressure unit";
CM_ SG_ 1173 Time_system "Time system";
CM_ SG_ 1173 NAVI_Speed_Limit_A "NAVI Speed Limitation Applicable";
CM_ SG_ 1173 Temperature_unit "Temperature unit";
CM_ SG_ 1173 Distance_unit "Distance unit";
CM_ SG_ 1173 ESC_SW_Cmd "ESC ON/OFF Buttom";
CM_ SG_ 1173 IVI_Panel_Act "IVI Touch Panel Active";
CM_ SG_ 1173 sigHvacRearReq "Request for operation for the rear HVAC (ON / OFF)";
CM_ SG_ 1173 FCWMute_BUTT "FCW Mute Buttom";
CM_ SG_ 1173 LKA_BUTT "LKA  ON/OFF Buttom";
CM_ SG_ 1173 ODAMute_BUTT "ODA Mute Buttom";
CM_ SG_ 1173 LDWMute_BUTT "LDW Mute Buttom";
CM_ SG_ 1173 BSDMute_BUTT "BSD Mute Buttom";
CM_ SG_ 1173 sigWindDirZon3Req "Request to HVAC Wind Direction Zone 3. 
Feed, Body and/or Auto";
CM_ SG_ 1173 sigAirIntenZon3Req "Request to HVAC FAN Level/Air Intensirty: 0-Max or Auto for zone 3
0xb~0xE:Reserved
0xb~0xE:Reserved
0xb~0xE:Reserved";
CM_ SG_ 1173 sigAirIntenZon1Req "Request to HVAC FAN Level/Air Intensirty: 0-Max or Auto for zone 1
0xb~0xE:Reserved
0xb~0xE:Reserved
0xb~0xE:Reserved";
CM_ SG_ 1173 AEB_BUTT "AEB  ON/OFF Buttom";
CM_ SG_ 1173 sigSetTempZon3Req "Temperature setpoint  for HVAC Zone 3";
CM_ SG_ 1173 sigSetTempZon2Req "Temperature setpoint  for HVAC Zone 2";
CM_ SG_ 1173 sigRecircReq "Recirculation request for the HVAC (ON / AUTO)";
CM_ SG_ 1173 sigHvacReq "Request for operation for the HVAC (ON / OFF)";
CM_ SG_ 1173 sigSetTempZon1Req "Temperature setpoint  for HVAC Zone 1";
CM_ SG_ 1173 sigHvacFrontReq "Request for operation for the front HVAC (ON / OFF)";
CM_ SG_ 1173 sigDfrstReq "Defrost request for the HVAC (ON / AUTO)";
CM_ SG_ 1173 GPS_LAT "GPS Location_Latitude";
CM_ SG_ 1173 GPS_LONG "GPS Location_Longitude";
CM_ SG_ 1173 L_Drv_ControlCommand "Driver window control command";
CM_ SG_ 1173 TPMS_Cali_Butt "TPMS tire calibrate button";
CM_ SG_ 1173 L_Pas_ControlCommand "Passenger window control command";
CM_ SG_ 1173 IVI_Unlock_Chg_req "IVI unlock Charging port Request";
CM_ SG_ 1173 L_RLD_ControlCommand "Rear Left window control command";
CM_ SG_ 1173 IVI_Stop_Chg_req "IVI Stop Charging Request";
CM_ SG_ 1173 L_RRD_ControlCommand "Rear Right  window control command";
CM_ SG_ 1173 IVI_Start_Chg_req "IVI Start Charging Request";
CM_ SG_ 1173 METER_Malfunc_Sta "Meter Malfunction Status";
CM_ SG_ 1173 sigFootReq "FOOT BLOWER REQUEST";
CM_ SG_ 1173 sigFaceReq "FACE BLOWER REQUEST";
CM_ SG_ 1173 Sched_Chg_Start "Scheduled Charging Start";
CM_ SG_ 1173 Sched_Chg_wake "Scheduled Charging wake up";
CM_ SG_ 1173 Sched_Chg_butt "Scheduled Charging Button";
CM_ SG_ 1173 Sched_Chg_Stop "Scheduled Charging stop";
CM_ SG_ 1173 Sched_Chg_limit "Scheduled Charging charging limit";
CM_ SG_ 1173 IVI_Req_V2L "IVI require V2L on/off";
CM_ SG_ 1173 Perd_V2L "V2L Period Setting";
CM_ SG_ 1173 SOC_V2LLimit "SOC V2LLimitation";
CM_ SG_ 1173 IVI_PTG_Open_Height "IVI 'PTG Open Height' Menu Status";
CM_ SG_ 1173 IVI_CreepSW_Req "IVI Creep On/Off Switch Request";
CM_ SG_ 1173 FalseNPrevent_SW "Prevent FALSE turn GEAR into N";
CM_ SG_ 1173 Approach_Unlock_SW "Unlock when approaching Switch";
CM_ SG_ 1173 Walkaway_Lock_SW "Lock when walking away";
CM_ SG_ 1183 IVI_Located_STA "IVI_GPS Satellite Located status";
CM_ SG_ 1183 IVI_Time_Month "IVI_GPS Satellite Time_Month";
CM_ SG_ 1183 IVI_Time_Hour "IVI_GPS Satellite Time_Hour";
CM_ SG_ 1183 IVI_Time_Day "IVI_GPS Satellite Time_Day";
CM_ SG_ 1183 IVI_Time_Second "IVI_GPS Satellite Time_Second";
CM_ SG_ 1183 IVI_Time_Minute "IVI_GPS Satellite Time_Minute";
CM_ SG_ 1183 IVI_Time_Year "IVI_GPS Satellite Time_Year";
CM_ SG_ 1183 IVI_Time_Check "IVI_GPS Satellite Time_Check Sum";
CM_ SG_ 1280 NM_FUSION_Node_ID "Source Node Identifier";
CM_ SG_ 1280 NM_FUSION_Rpt_Msg_Req "Repeat Message Request";
CM_ SG_ 1280 NM_FUSION_CSB "NM Coordinator Sleep Bit";
CM_ SG_ 1280 NM_FUSION_Active_WU "Active Wakeup Bit";
CM_ SG_ 1280 NM_FUSION_PNI "Partial Network Information Bit (PNI)";
CM_ SG_ 1280 NM_FUSION_ERROR_State "Defined Error states of the CAN Controller";
CM_ SG_ 1281 NM_ESC_Node_ID "Source Node Identifier";
CM_ SG_ 1281 NM_ESC_Rpt_Msg_Req "Repeat Message Request";
CM_ SG_ 1281 NM_ESC_CSB "NM Coordinator Sleep Bit";
CM_ SG_ 1281 NM_ESC_Active_WU "Active Wakeup Bit";
CM_ SG_ 1281 NM_ESC_PNI "Partial Network Information Bit (PNI)";
CM_ SG_ 1281 NM_ESC_ERROR_State "Defined Error states of the CAN Controller";
CM_ SG_ 1296 NM_FCM_Node_ID "Source Node Identifier";
CM_ SG_ 1296 NM_FCM_Rpt_Msg_Req "Repeat Message Request";
CM_ SG_ 1296 NM_FCM_CSB "NM Coordinator Sleep Bit";
CM_ SG_ 1296 NM_FCM_Active_WU "Active Wakeup Bit";
CM_ SG_ 1296 NM_FCM_PNI "Partial Network Information Bit (PNI)";
CM_ SG_ 1296 NM_FCM_ERROR_State "Defined Error states of the CAN Controller";
CM_ SG_ 1297 NM_eBST_Node_ID "Source Node Identifier";
CM_ SG_ 1297 NM_eBST_Rpt_Msg_Req "Repeat Message Request";
CM_ SG_ 1297 NM_eBST_CSB "NM Coordinator Sleep Bit";
CM_ SG_ 1297 NM_eBST_Active_WU "Active Wakeup Bit";
CM_ SG_ 1297 NM_eBST_PNI "Partial Network Information Bit (PNI)";
CM_ SG_ 1297 NM_eBST_ERROR_State "Defined Error states of the CAN Controller";
CM_ SG_ 1298 NM_SRR_M_Node_ID "Source Node Identifier";
CM_ SG_ 1298 NM_SRR_M_Rpt_Msg_Req "Repeat Message Request";
CM_ SG_ 1298 NM_SRR_M_CSB "NM Coordinator Sleep Bit";
CM_ SG_ 1298 NM_SRR_M_Active_WU "Active Wakeup Bit";
CM_ SG_ 1298 NM_SRR_M_PNI "Partial Network Information Bit (PNI)";
CM_ SG_ 1298 NM_SRR_M_ERROR_State "Defined Error states of the CAN Controller";
CM_ SG_ 1313 NM_EPAS_Node_ID "Source Node Identifier";
CM_ SG_ 1313 NM_EPAS_Rpt_Msg_Req "Repeat Message Request";
CM_ SG_ 1313 NM_EPAS_CSB "NM Coordinator Sleep Bit";
CM_ SG_ 1313 NM_EPAS_Active_WU "Active Wakeup Bit";
CM_ SG_ 1313 NM_EPAS_PNI "Partial Network Information Bit (PNI)";
CM_ SG_ 1313 NM_EPAS_ERROR_State "Defined Error states of the CAN Controller";
CM_ SG_ 1329 NM_ABM_Node_ID "Source Node Identifier";
CM_ SG_ 1329 NM_ABM_Rpt_Msg_Req "Repeat Message Request";
CM_ SG_ 1329 NM_ABM_CSB "NM Coordinator Sleep Bit";
CM_ SG_ 1329 NM_ABM_Active_WU "Active Wakeup Bit";
CM_ SG_ 1329 NM_ABM_PNI "Partial Network Information Bit (PNI)";
CM_ SG_ 1329 NM_ABM_ERROR_State "Defined Error states of the CAN Controller";
CM_ SG_ 1537 DiagRespFromESC "Diagnostic Response from ESC";
CM_ SG_ 1552 DiagRespFromFCM "Diagnostic Response from FCM";
CM_ SG_ 1553 DiagRespFromeBST "Diagnostic Response from eBST";
CM_ SG_ 1554 DiagRespFromSRR_M "Diagnostic Response from SRR_M";
CM_ SG_ 1557 DiagRespFromMRR "Diagnostic Response from MRR";
CM_ SG_ 1569 DiagRespFromEPAS "Diagnostic Response from EPAS";
CM_ SG_ 1585 DiagRespFromABM "Diagnostic Response from ABM";
CM_ SG_ 1665 DiagPhysReqToESC "Diagnostic Physical Request to ESC";
CM_ SG_ 1680 DiagPhysReqToFCM "Diagnostic Physical Request to FCM";
CM_ SG_ 1681 DiagPhysReqToeBST "Diagnostic Physical Request to eBST";
CM_ SG_ 1682 DiagPhysReqToSRR_M "Diagnostic Physical Request to SRR_M";
CM_ SG_ 1685 DiagPhysReqToMRR "Diagnostic Physical Request to MRR";
CM_ SG_ 1697 DiagPhysReqToEPAS "Diagnostic Physical Request to EPAS";
CM_ SG_ 1713 DiagPhysReqToABM "Diagnostic Physical Request to ABM";
CM_ SG_ 2000 DiagFuncReqFT "Diagnostic Functional Request from Tester";
CM_ SG_ 2002 XCPReqToESC "XCP Request to ESC";
CM_ SG_ 2003 XCPRespFromESC "XCP Response From ESC";
CM_ SG_ 2004 XCPReqToeBST "XCP Request to eBST";
CM_ SG_ 2005 XCPRespFromeBST "XCP Response From eBST";
CM_ SG_ 2040 CCP1ReqToEPAS "EPAS CCP_Request";
CM_ SG_ 2041 CCP1RespFromEPAS "EPAS_CCP_Response";
CM_ SG_ 550 DrLockSta "Driver Side Door Lock Staus";
CM_ SG_ 550 PsLockSta "Passenger Side Door Lock Status";
CM_ SG_ 550 RLLockSta "Rear Left Door Lock Status";
CM_ SG_ 550 RRLockSta "Rear Right Door Lock Status";
CM_ SG_ 550 AllLockSta "All Door Lock";
CM_ SG_ 550 MIRROR_FOLD_SW "MIRROR_FOLD_SW";
CM_ SG_ 550 RWiperAS "Rear Wiper AS";
CM_ SG_ 550 RWiperProtection "Rear Wiper Protection";
CM_ SG_ 550 Wip_Speed "Wip_Speed";
CM_ SG_ 550 CSW_RWipIntSw_Sta "CSW_RWipSW_Sta";
CM_ SG_ 550 CSW_DimSw "CSW_DimSw";
CM_ SG_ 550 BrakeLampFail "BrakeLamp Failed";
CM_ SG_ 550 CSW_PassSW_Sta "CSW_PassSW_Sta";
CM_ SG_ 550 RLS_Exist "RLS_Exist";
CM_ SG_ 550 RLTurnLampC "Rear Left TurnLamp Current";
CM_ SG_ 550 RRTurnLampC "Rear Right TurnLamp Current";
CM_ SG_ 550 CSW_FWasSw_Sta "CSW_FWasherSW_Sta";
CM_ SG_ 550 CSW_RWasSW_Sta "CSW_RWasherSW_Sta";
CM_ SG_ 550 CSW_TurnSw_Sta "CSW_TurnSw_Sta_CANbus";
CM_ SG_ 550 HornSW "Horn Switch status";
CM_ SG_ 550 RLS_RainSnrWiperCmd "RainSensorWiperCommand";
CM_ SG_ 550 RLS_Lamp_Sta "Lampstatus";
CM_ SG_ 550 RLS_LightSnrErr "LightSensorError";
CM_ SG_ 550 RLS_RainSnrErr "RainSensorError";
CM_ SG_ 550 WiperSWPos "WiperSwitchPosition";
CM_ SG_ 550 WiperZeroPosSW "WiperZeroPositionSwitch";
CM_ SG_ 550 AutoLightSW "LightActivation";

BA_DEF_ "NmType" STRING ;
BA_DEF_ "VersionYear" INT 2010 2999;
BA_DEF_ "ProtocolType" STRING ;
BA_DEF_ "NmMessageCount" INT 0 255;
BA_DEF_ "NmBaseAddress" HEX 1280 1407;
BA_DEF_ "DBName" STRING ;
BA_DEF_ "BusType" STRING ;
BA_DEF_ "Baudrate" INT 0 1000000;
BA_DEF_ "Datarate" INT 0 2000000;
BA_DEF_ BU_ "NodeLayerModules" STRING ;
BA_DEF_ BU_ "NmCAN" INT 1 2;
BA_DEF_ BU_ "ILUsed" ENUM "No","Yes";
BA_DEF_ BU_ "CANFD_CANFD_Gateway" ENUM "Yes","No";
BA_DEF_ BO_ "GenMsgSendType" ENUM "Cycle","NoMsgSendType","IfActive","Event","CA","CE";
BA_DEF_ BO_ "GenMsgNrOfRepetition" INT 0 0;
BA_DEF_ BO_ "GenMsgILSupport" ENUM "No","Yes";
BA_DEF_ BO_ "GenMsgDelayTime" INT 0 0;
BA_DEF_ BO_ "GenMsgCycleTimeFast" INT 0 0;
BA_DEF_ BO_ "GenMsgCycleTime" INT 0 0;
BA_DEF_ BO_ "DiagResponse" ENUM "No","Yes";
BA_DEF_ BO_ "DiagRequest" ENUM "No","Yes";
BA_DEF_ BO_ "NmMessage" ENUM "No","Yes";
BA_DEF_ BO_ "VFrameFormat" ENUM "StandardCAN","ExtendedCAN","reserved","reserved","reserved","reserved","reserved","reserved","reserved","reserved","reserved","reserved","reserved","reserved","StandardCAN_FD","ExtendedCAN_FD";
BA_DEF_ BO_ "GenMsgRequestable" INT 0 1;
BA_DEF_ BO_ "DataID_Hex" HEX 0 65535;
BA_DEF_ BO_ "DoIPLogicalAddress" STRING ;
BA_DEF_ BO_ "DataID" STRING ;
BA_DEF_ BO_ "CANFD_BRS" ENUM "0","1";
BA_DEF_ SG_ "GenSigInvalidValue" HEX 0 0;
BA_DEF_ SG_ "GenSigStartValue" HEX 0 0;
BA_DEF_ SG_ "GenSigInactiveValue" HEX 0 0;
BA_DEF_ SG_ "GenSigRoutingTimeoutValue" HEX 0 0;
BA_DEF_ SG_ "GenSigSendType" ENUM "Cycle","OnWrite","OnWriteWithRepetition","OnChange","OnChangeWithRepetition","IfActive","IfActiveWithRepetition","NoSigSendType","vector_leerstring";
BA_DEF_ SG_ "SigType" ENUM "Default","Range","RangeSigned","ASCII","Discrete","Control","ReferencePGN","DTC","StringDelimiter","StringLength","StringLengthControl","MessageCounter","MessageChecksum";
BA_DEF_ SG_ "GenSigILSupport" ENUM "No","Yes";
BA_DEF_DEF_ "NmType" "AUTOSAR";
BA_DEF_DEF_ "VersionYear" 2023;
BA_DEF_DEF_ "ProtocolType" "CAN";
BA_DEF_DEF_ "NmMessageCount" 128;
BA_DEF_DEF_ "NmBaseAddress" 1280;
BA_DEF_DEF_ "DBName" "";
BA_DEF_DEF_ "BusType" "";
BA_DEF_DEF_ "Baudrate" 500000;
BA_DEF_DEF_ "Datarate" 2000000;
BA_DEF_DEF_ "NodeLayerModules" "CANoeILNLVector.dll";
BA_DEF_DEF_ "NmCAN" 2;
BA_DEF_DEF_ "ILUsed" "Yes";
BA_DEF_DEF_ "CANFD_CANFD_Gateway" "No";
BA_DEF_DEF_ "GenMsgSendType" "Cycle";
BA_DEF_DEF_ "GenMsgNrOfRepetition" 0;
BA_DEF_DEF_ "GenMsgILSupport" "Yes";
BA_DEF_DEF_ "GenMsgDelayTime" 0;
BA_DEF_DEF_ "GenMsgCycleTimeFast" 0;
BA_DEF_DEF_ "GenMsgCycleTime" 100;
BA_DEF_DEF_ "DiagResponse" "No";
BA_DEF_DEF_ "DiagRequest" "No";
BA_DEF_DEF_ "NmMessage" "No";
BA_DEF_DEF_ "VFrameFormat" "StandardCAN";
BA_DEF_DEF_ "GenMsgRequestable" 1;
BA_DEF_DEF_ "DataID_Hex" 0;
BA_DEF_DEF_ "DoIPLogicalAddress" "";
BA_DEF_DEF_ "DataID" "";
BA_DEF_DEF_ "CANFD_BRS" "1";
BA_DEF_DEF_ "GenSigInvalidValue" 0;
BA_DEF_DEF_ "GenSigStartValue" 0;
BA_DEF_DEF_ "GenSigInactiveValue" 0;
BA_DEF_DEF_ "GenSigRoutingTimeoutValue" 0;
BA_DEF_DEF_ "GenSigSendType" "Cycle";
BA_DEF_DEF_ "SigType" "Default";
BA_DEF_DEF_ "GenSigILSupport" "Yes";
BA_ "BusType" "CAN FD";
BA_ "ProtocolType" "CAN FD";
BA_ "DBName" "CAN1";
BA_ "CANFD_CANFD_Gateway" BU_ FUSION 0;
BA_ "GenMsgNrOfRepetition" BO_ 278 1;
BA_ "GenMsgCycleTimeFast" BO_ 278 10;
BA_ "GenMsgSendType" BO_ 278 5;
BA_ "VFrameFormat" BO_ 278 14;
BA_ "DataID_Hex" BO_ 338 24499;
BA_ "GenMsgCycleTime" BO_ 338 10;
BA_ "DataID" BO_ 338 "0x5FB3";
BA_ "VFrameFormat" BO_ 338 14;
BA_ "DataID_Hex" BO_ 339 19397;
BA_ "GenMsgCycleTime" BO_ 339 10;
BA_ "DataID" BO_ 339 "0x4BC5";
BA_ "VFrameFormat" BO_ 339 14;
BA_ "DataID_Hex" BO_ 340 63729;
BA_ "GenMsgCycleTime" BO_ 340 10;
BA_ "DataID" BO_ 340 "0xF8F1";
BA_ "VFrameFormat" BO_ 340 14;
BA_ "GenMsgCycleTime" BO_ 342 10;
BA_ "VFrameFormat" BO_ 342 14;
BA_ "GenMsgCycleTime" BO_ 343 10;
BA_ "VFrameFormat" BO_ 343 14;
BA_ "DataID_Hex" BO_ 345 60360;
BA_ "GenMsgCycleTime" BO_ 345 10;
BA_ "DataID" BO_ 345 "0xEBC8";
BA_ "VFrameFormat" BO_ 345 14;
BA_ "GenMsgCycleTime" BO_ 360 10;
BA_ "VFrameFormat" BO_ 360 14;
BA_ "DataID_Hex" BO_ 377 46625;
BA_ "GenMsgCycleTime" BO_ 377 10;
BA_ "DataID" BO_ 377 "0xB621";
BA_ "VFrameFormat" BO_ 377 14;
BA_ "DataID_Hex" BO_ 380 33440;
BA_ "GenMsgCycleTime" BO_ 380 10;
BA_ "DataID" BO_ 380 "0x82A0";
BA_ "VFrameFormat" BO_ 380 14;
BA_ "VFrameFormat" BO_ 386 14;
BA_ "GenMsgCycleTime" BO_ 391 20;
BA_ "VFrameFormat" BO_ 391 14;
BA_ "GenMsgCycleTime" BO_ 410 10;
BA_ "VFrameFormat" BO_ 410 14;
BA_ "GenMsgCycleTime" BO_ 419 10;
BA_ "VFrameFormat" BO_ 419 14;
BA_ "DataID_Hex" BO_ 421 28249;
BA_ "GenMsgCycleTime" BO_ 421 10;
BA_ "DataID" BO_ 421 "0x6E59";
BA_ "VFrameFormat" BO_ 421 14;
BA_ "GenMsgCycleTime" BO_ 425 10;
BA_ "VFrameFormat" BO_ 425 14;
BA_ "GenMsgCycleTime" BO_ 427 40;
BA_ "VFrameFormat" BO_ 427 14;
BA_ "GenMsgNrOfRepetition" BO_ 515 1;
BA_ "DataID_Hex" BO_ 515 58610;
BA_ "GenMsgCycleTime" BO_ 515 500;
BA_ "DataID" BO_ 515 "0xE4F2";
BA_ "GenMsgCycleTimeFast" BO_ 515 50;
BA_ "GenMsgSendType" BO_ 515 5;
BA_ "VFrameFormat" BO_ 515 14;
BA_ "VFrameFormat" BO_ 517 14;
BA_ "GenMsgCycleTime" BO_ 528 20;
BA_ "VFrameFormat" BO_ 528 14;
BA_ "GenMsgNrOfRepetition" BO_ 534 1;
BA_ "GenMsgCycleTime" BO_ 534 200;
BA_ "GenMsgCycleTimeFast" BO_ 534 60;
BA_ "GenMsgSendType" BO_ 534 5;
BA_ "VFrameFormat" BO_ 534 14;
BA_ "GenMsgCycleTime" BO_ 553 10;
BA_ "VFrameFormat" BO_ 553 14;
BA_ "GenMsgCycleTime" BO_ 566 20;
BA_ "VFrameFormat" BO_ 566 14;
BA_ "GenMsgCycleTime" BO_ 568 10;
BA_ "VFrameFormat" BO_ 568 14;
BA_ "GenMsgNrOfRepetition" BO_ 570 1;
BA_ "DataID_Hex" BO_ 570 29212;
BA_ "DataID" BO_ 570 "0x721C";
BA_ "GenMsgCycleTimeFast" BO_ 570 10;
BA_ "VFrameFormat" BO_ 570 14;
BA_ "GenMsgNrOfRepetition" BO_ 572 1;
BA_ "DataID_Hex" BO_ 572 2289;
BA_ "DataID" BO_ 572 "0x08F1";
BA_ "GenMsgCycleTimeFast" BO_ 572 10;
BA_ "VFrameFormat" BO_ 572 14;
BA_ "GenMsgNrOfRepetition" BO_ 602 1;
BA_ "GenMsgCycleTimeFast" BO_ 602 10;
BA_ "GenMsgSendType" BO_ 602 5;
BA_ "VFrameFormat" BO_ 602 14;
BA_ "GenMsgNrOfRepetition" BO_ 659 1;
BA_ "GenMsgCycleTimeFast" BO_ 659 10;
BA_ "GenMsgSendType" BO_ 659 5;
BA_ "VFrameFormat" BO_ 659 14;
BA_ "GenMsgNrOfRepetition" BO_ 826 1;
BA_ "GenMsgCycleTime" BO_ 826 200;
BA_ "GenMsgCycleTimeFast" BO_ 826 10;
BA_ "GenMsgSendType" BO_ 826 5;
BA_ "VFrameFormat" BO_ 826 14;
BA_ "GenMsgNrOfRepetition" BO_ 960 1;
BA_ "GenMsgCycleTime" BO_ 960 200;
BA_ "GenMsgCycleTimeFast" BO_ 960 50;
BA_ "GenMsgSendType" BO_ 960 5;
BA_ "VFrameFormat" BO_ 960 14;
BA_ "VFrameFormat" BO_ 1008 14;
BA_ "VFrameFormat" BO_ 1009 14;
BA_ "VFrameFormat" BO_ 1010 14;
BA_ "VFrameFormat" BO_ 1011 14;
BA_ "VFrameFormat" BO_ 1012 14;
BA_ "VFrameFormat" BO_ 1013 14;
BA_ "VFrameFormat" BO_ 1014 14;
BA_ "VFrameFormat" BO_ 1015 14;
BA_ "GenMsgNrOfRepetition" BO_ 1173 1;
BA_ "GenMsgCycleTime" BO_ 1173 200;
BA_ "GenMsgDelayTime" BO_ 1173 5;
BA_ "GenMsgCycleTimeFast" BO_ 1173 20;
BA_ "GenMsgSendType" BO_ 1173 5;
BA_ "VFrameFormat" BO_ 1173 14;
BA_ "GenMsgCycleTime" BO_ 1183 1000;
BA_ "VFrameFormat" BO_ 1183 14;
BA_ "GenMsgCycleTime" BO_ 1280 0;
BA_ "NmMessage" BO_ 1280 1;
BA_ "GenMsgSendType" BO_ 1280 3;
BA_ "GenMsgCycleTime" BO_ 1281 0;
BA_ "NmMessage" BO_ 1281 1;
BA_ "GenMsgSendType" BO_ 1281 3;
BA_ "GenMsgCycleTime" BO_ 1296 0;
BA_ "NmMessage" BO_ 1296 1;
BA_ "GenMsgSendType" BO_ 1296 3;
BA_ "GenMsgCycleTime" BO_ 1297 700;
BA_ "NmMessage" BO_ 1297 1;
BA_ "GenMsgCycleTime" BO_ 1298 0;
BA_ "NmMessage" BO_ 1298 1;
BA_ "GenMsgSendType" BO_ 1298 3;
BA_ "GenMsgCycleTime" BO_ 1313 700;
BA_ "NmMessage" BO_ 1313 1;
BA_ "GenMsgCycleTime" BO_ 1329 0;
BA_ "NmMessage" BO_ 1329 1;
BA_ "GenMsgSendType" BO_ 1329 3;
BA_ "GenMsgCycleTime" BO_ 1537 0;
BA_ "DiagResponse" BO_ 1537 1;
BA_ "GenMsgSendType" BO_ 1537 3;
BA_ "DoIPLogicalAddress" BO_ 1537 "0x0681";
BA_ "GenMsgCycleTime" BO_ 1552 0;
BA_ "DiagResponse" BO_ 1552 1;
BA_ "GenMsgSendType" BO_ 1552 3;
BA_ "VFrameFormat" BO_ 1552 14;
BA_ "DoIPLogicalAddress" BO_ 1552 "0x0690";
BA_ "GenMsgCycleTime" BO_ 1553 0;
BA_ "DiagResponse" BO_ 1553 1;
BA_ "GenMsgSendType" BO_ 1553 3;
BA_ "DoIPLogicalAddress" BO_ 1553 "0x0691";
BA_ "GenMsgCycleTime" BO_ 1554 0;
BA_ "DiagResponse" BO_ 1554 1;
BA_ "GenMsgSendType" BO_ 1554 3;
BA_ "VFrameFormat" BO_ 1554 14;
BA_ "DoIPLogicalAddress" BO_ 1554 "0x0692";
BA_ "GenMsgCycleTime" BO_ 1557 0;
BA_ "DiagResponse" BO_ 1557 1;
BA_ "GenMsgSendType" BO_ 1557 3;
BA_ "DoIPLogicalAddress" BO_ 1557 "0x0695";
BA_ "GenMsgCycleTime" BO_ 1569 0;
BA_ "DiagResponse" BO_ 1569 1;
BA_ "GenMsgSendType" BO_ 1569 3;
BA_ "VFrameFormat" BO_ 1569 14;
BA_ "DoIPLogicalAddress" BO_ 1569 "0x06A1";
BA_ "GenMsgCycleTime" BO_ 1585 0;
BA_ "DiagResponse" BO_ 1585 1;
BA_ "GenMsgSendType" BO_ 1585 3;
BA_ "VFrameFormat" BO_ 1585 14;
BA_ "DoIPLogicalAddress" BO_ 1585 "0x06B1";
BA_ "GenMsgCycleTime" BO_ 1665 0;
BA_ "DiagRequest" BO_ 1665 1;
BA_ "GenMsgSendType" BO_ 1665 3;
BA_ "DoIPLogicalAddress" BO_ 1665 "0x0681";
BA_ "GenMsgCycleTime" BO_ 1680 0;
BA_ "DiagRequest" BO_ 1680 1;
BA_ "GenMsgSendType" BO_ 1680 3;
BA_ "VFrameFormat" BO_ 1680 14;
BA_ "DoIPLogicalAddress" BO_ 1680 "0x0690";
BA_ "GenMsgCycleTime" BO_ 1681 0;
BA_ "DiagRequest" BO_ 1681 1;
BA_ "GenMsgSendType" BO_ 1681 3;
BA_ "DoIPLogicalAddress" BO_ 1681 "0x0691";
BA_ "GenMsgCycleTime" BO_ 1682 0;
BA_ "DiagRequest" BO_ 1682 1;
BA_ "GenMsgSendType" BO_ 1682 3;
BA_ "VFrameFormat" BO_ 1682 14;
BA_ "DoIPLogicalAddress" BO_ 1682 "0x0692";
BA_ "GenMsgCycleTime" BO_ 1685 0;
BA_ "DiagRequest" BO_ 1685 1;
BA_ "GenMsgSendType" BO_ 1685 3;
BA_ "DoIPLogicalAddress" BO_ 1685 "0x0695";
BA_ "GenMsgCycleTime" BO_ 1697 0;
BA_ "DiagRequest" BO_ 1697 1;
BA_ "GenMsgSendType" BO_ 1697 3;
BA_ "VFrameFormat" BO_ 1697 14;
BA_ "DoIPLogicalAddress" BO_ 1697 "0x06A1";
BA_ "GenMsgCycleTime" BO_ 1713 0;
BA_ "DiagRequest" BO_ 1713 1;
BA_ "GenMsgSendType" BO_ 1713 3;
BA_ "VFrameFormat" BO_ 1713 14;
BA_ "DoIPLogicalAddress" BO_ 1713 "0x06B1";
BA_ "GenMsgCycleTime" BO_ 2000 0;
BA_ "DiagRequest" BO_ 2000 1;
BA_ "GenMsgSendType" BO_ 2000 3;
BA_ "DoIPLogicalAddress" BO_ 2000 "0xEFFF";
BA_ "GenMsgCycleTime" BO_ 2002 0;
BA_ "GenMsgSendType" BO_ 2002 3;
BA_ "GenMsgCycleTime" BO_ 2003 0;
BA_ "GenMsgSendType" BO_ 2003 3;
BA_ "GenMsgCycleTime" BO_ 2004 0;
BA_ "GenMsgSendType" BO_ 2004 3;
BA_ "VFrameFormat" BO_ 2004 14;
BA_ "GenMsgCycleTime" BO_ 2005 0;
BA_ "GenMsgSendType" BO_ 2005 3;
BA_ "VFrameFormat" BO_ 2005 14;
BA_ "GenMsgCycleTime" BO_ 2040 0;
BA_ "GenMsgSendType" BO_ 2040 3;
BA_ "VFrameFormat" BO_ 2040 14;
BA_ "GenMsgCycleTime" BO_ 2041 0;
BA_ "GenMsgSendType" BO_ 2041 3;
BA_ "VFrameFormat" BO_ 2041 14;
BA_ "GenMsgNrOfRepetition" BO_ 550 1;
BA_ "GenMsgCycleTime" BO_ 550 200;
BA_ "GenMsgCycleTimeFast" BO_ 550 50;
BA_ "GenMsgSendType" BO_ 550 5;
BA_ "VFrameFormat" BO_ 550 14;
BA_ "GenSigSendType" SG_ 278 XWDMode 3;
BA_ "GenSigSendType" SG_ 278 LVPwrSta 3;
BA_ "GenSigSendType" SG_ 278 HVPwrSta 3;
BA_ "GenSigSendType" SG_ 278 PwrSta 3;
BA_ "GenSigSendType" SG_ 278 PrkReq 3;
BA_ "GenSigSendType" SG_ 278 ShiftGearPosn 3;
BA_ "GenSigInvalidValue" SG_ 278 CC_Crl_Sta 6;
BA_ "GenSigSendType" SG_ 278 CC_Crl_Sta 3;
BA_ "GenSigInvalidValue" SG_ 278 MSA_Crl_Sta 6;
BA_ "GenSigSendType" SG_ 278 MSA_Crl_Sta 3;
BA_ "GenSigSendType" SG_ 278 PrkReqValid 3;
BA_ "GenSigInvalidValue" SG_ 338 RearAxlTrqReq_Drv 65535;
BA_ "GenSigStartValue" SG_ 338 RearAxlTrqReq_Drv 10600;
BA_ "GenSigInvalidValue" SG_ 338 FrntAxlTrqReq_Drv 65535;
BA_ "GenSigStartValue" SG_ 338 FrntAxlTrqReq_Drv 10600;
BA_ "GenSigInvalidValue" SG_ 338 VehSpeed 4095;
BA_ "GenSigRoutingTimeoutValue" SG_ 338 VehSpeed 4095;
BA_ "GenSigInvalidValue" SG_ 339 FrntAxlTrqReq_Brk 65535;
BA_ "GenSigStartValue" SG_ 339 FrntAxlTrqReq_Brk 10600;
BA_ "GenSigInvalidValue" SG_ 339 RearAxlTrqReq_Brk 65535;
BA_ "GenSigStartValue" SG_ 339 RearAxlTrqReq_Brk 10600;
BA_ "GenSigInvalidValue" SG_ 339 BrkPedalPos 255;
BA_ "GenSigStartValue" SG_ 340 DriverTq 4300;
BA_ "GenSigStartValue" SG_ 340 VehActPwr 600000;
BA_ "GenSigStartValue" SG_ 340 Rr_DriverTq 10600;
BA_ "GenSigStartValue" SG_ 340 Fr_DriverTq 10600;
BA_ "GenSigInvalidValue" SG_ 342 LF_RawWhlSpeed_V 1;
BA_ "GenSigInvalidValue" SG_ 342 LF_PulseCount_V 1;
BA_ "GenSigInvalidValue" SG_ 342 RF_RawWhlSpeed_V 1;
BA_ "GenSigInvalidValue" SG_ 342 RF_PulseCount_V 1;
BA_ "GenSigInvalidValue" SG_ 343 LR_RawWhlSpeed_V 1;
BA_ "GenSigInvalidValue" SG_ 343 LR_PulseCount_V 1;
BA_ "GenSigInvalidValue" SG_ 343 RR_RawWhlSpeed_V 1;
BA_ "GenSigInvalidValue" SG_ 343 RR_PulseCount_V 1;
BA_ "GenSigStartValue" SG_ 345 Fr_EDURealDrvOrBRgnTq 10600;
BA_ "GenSigStartValue" SG_ 345 Fr_EDUAvailBrkRgnTq 10600;
BA_ "GenSigStartValue" SG_ 345 Fr_EDURealARgnTq 5300;
BA_ "GenSigStartValue" SG_ 345 Fr_EDUSpd 2000;
BA_ "GenSigInvalidValue" SG_ 345 Fr_EDUAvailBrkRgnTqValid 1;
BA_ "GenSigInvalidValue" SG_ 345 Rr_EDUAvailBrkRgnTqValid 1;
BA_ "GenSigStartValue" SG_ 345 Rr_EDURealDrvOrBRgnTq 10600;
BA_ "GenSigStartValue" SG_ 345 Rr_EDUAvailBrkRgnTq 10600;
BA_ "GenSigStartValue" SG_ 345 Rr_EDURealARgnTq 5300;
BA_ "GenSigStartValue" SG_ 345 Rr_EDUSpd 2000;
BA_ "GenSigInvalidValue" SG_ 377 ACC_ComfortBandLower 511;
BA_ "GenSigInvalidValue" SG_ 377 ACC_JerkLowerLimit 127;
BA_ "GenSigInvalidValue" SG_ 377 ACC_ComfortBandUpper 511;
BA_ "GenSigInvalidValue" SG_ 377 ACC_JerkUpperLimit 127;
BA_ "GenSigInvalidValue" SG_ 380 ACC_ObjRelSpd 2047;
BA_ "GenSigInvalidValue" SG_ 380 ACC_ObjDist 2047;
BA_ "GenSigStartValue" SG_ 380 ACC_ObjDist 2046;
BA_ "GenSigStartValue" SG_ 386 Rr_Coolanttemp 40;
BA_ "GenSigStartValue" SG_ 386 sigClntTHvBattOut 120;
BA_ "GenSigStartValue" SG_ 386 sigCbnSolarLeft 253;
BA_ "GenSigStartValue" SG_ 386 sigCbnSolarRight 253;
BA_ "GenSigInvalidValue" SG_ 386 sigAmbAirT 255;
BA_ "GenSigInvalidValue" SG_ 386 sigAirIntenZon1St 15;
BA_ "GenSigStartValue" SG_ 386 Fr_Coolanttemp 40;
BA_ "GenSigInvalidValue" SG_ 410 SAS_Angle 65535;
BA_ "GenSigStartValue" SG_ 410 SAS_Angle 9000;
BA_ "GenSigStartValue" SG_ 419 GRADE 127;
BA_ "GenSigInvalidValue" SG_ 419 SystemVoltage 255;
BA_ "GenSigInvalidValue" SG_ 421 YawRate 2047;
BA_ "GenSigStartValue" SG_ 421 YawRate 1000;
BA_ "GenSigInvalidValue" SG_ 421 LatAccel 255;
BA_ "GenSigStartValue" SG_ 421 LatAccel 127;
BA_ "GenSigInvalidValue" SG_ 421 LongAccel 255;
BA_ "GenSigStartValue" SG_ 421 LongAccel 127;
BA_ "GenSigInvalidValue" SG_ 421 MCPressure 4095;
BA_ "GenSigStartValue" SG_ 421 MCPressure 97;
BA_ "GenSigInvalidValue" SG_ 421 YawRate_V 1;
BA_ "GenSigInvalidValue" SG_ 421 LatAccel_V 1;
BA_ "GenSigInvalidValue" SG_ 421 LongAccel_V 1;
BA_ "GenSigInvalidValue" SG_ 421 MCPressure_V 1;
BA_ "GenSigInvalidValue" SG_ 421 BrkSw_V 1;
BA_ "GenSigInvalidValue" SG_ 425 Meter_Ind_VehSpeed 4095;
BA_ "GenSigInvalidValue" SG_ 427 EPBStaL 7;
BA_ "GenSigInvalidValue" SG_ 427 EPBStaR 7;
BA_ "GenSigSendType" SG_ 515 AirBagFailCmd 3;
BA_ "GenSigSendType" SG_ 515 DriverSeatBeltCmd 3;
BA_ "GenSigSendType" SG_ 515 PsngrSeatBeltCmd 3;
BA_ "GenSigSendType" SG_ 515 PABSwitchCmd 3;
BA_ "GenSigSendType" SG_ 515 RDriverSeatBeltCmd 3;
BA_ "GenSigSendType" SG_ 515 RPsngrSeatBeltCmd 3;
BA_ "GenSigSendType" SG_ 515 RCenterSeatBeltCmd 3;
BA_ "GenSigSendType" SG_ 515 TLHPsngrSeatBeltCmd 3;
BA_ "GenSigSendType" SG_ 515 TRHPsngrSeatBeltCmd 3;
BA_ "GenSigSendType" SG_ 515 CrashOutputSts 3;
BA_ "GenSigSendType" SG_ 515 LifeCount_ABM1 3;
BA_ "GenSigSendType" SG_ 515 Checksum_ABM1 3;
BA_ "GenSigSendType" SG_ 534 DrDoorSW 3;
BA_ "GenSigSendType" SG_ 534 PsDoorSW 3;
BA_ "GenSigSendType" SG_ 534 RLDoorSW 3;
BA_ "GenSigSendType" SG_ 534 RRDoorSW 3;
BA_ "GenSigSendType" SG_ 534 AllDoorSW 3;
BA_ "GenSigSendType" SG_ 534 DoorLockIND 3;
BA_ "GenSigSendType" SG_ 534 HoodSW 3;
BA_ "GenSigSendType" SG_ 534 Tailgate_SW 3;
BA_ "GenSigSendType" SG_ 534 CTDCtrl 3;
BA_ "GenSigSendType" SG_ 534 Fr_ChargingDoorCtrl 3;
BA_ "GenSigSendType" SG_ 534 Rr_ChargingDoorCtrl 3;
BA_ "GenSigSendType" SG_ 534 CTDLockSW 3;
BA_ "GenSigSendType" SG_ 534 CTDUnlockSW 3;
BA_ "GenSigSendType" SG_ 534 MirrorDefog 3;
BA_ "GenSigSendType" SG_ 534 Rr_Defog 3;
BA_ "GenSigSendType" SG_ 534 TrunkRel 3;
BA_ "GenSigSendType" SG_ 534 TailgateHDSW 3;
BA_ "GenSigSendType" SG_ 534 MirrorCtrl 3;
BA_ "GenSigSendType" SG_ 534 Fr_Wiper_H 3;
BA_ "GenSigSendType" SG_ 534 Fr_Wiper_L 3;
BA_ "GenSigSendType" SG_ 534 Rr_Wiper 3;
BA_ "GenSigSendType" SG_ 534 WiperFixMode 3;
BA_ "GenSigSendType" SG_ 534 WasherCtrl 3;
BA_ "GenSigSendType" SG_ 534 L_Beam 3;
BA_ "GenSigSendType" SG_ 534 H_Beam 3;
BA_ "GenSigSendType" SG_ 534 PosLamp 3;
BA_ "GenSigSendType" SG_ 534 LDRL 3;
BA_ "GenSigSendType" SG_ 534 RDRL 3;
BA_ "GenSigSendType" SG_ 534 ReverseLamp 3;
BA_ "GenSigSendType" SG_ 534 BrakeLamp 3;
BA_ "GenSigSendType" SG_ 534 LBSD 3;
BA_ "GenSigSendType" SG_ 534 RBSD 3;
BA_ "GenSigSendType" SG_ 534 Fr_FogLamp 3;
BA_ "GenSigSendType" SG_ 534 Rr_FogLamp 3;
BA_ "GenSigSendType" SG_ 534 HazardSW 3;
BA_ "GenSigSendType" SG_ 534 LTurnLP 3;
BA_ "GenSigSendType" SG_ 534 RTurnLP 3;
BA_ "GenSigSendType" SG_ 534 AntitheftSta 3;
BA_ "GenSigSendType" SG_ 534 AntiTheftSeatFold 3;
BA_ "GenSigInvalidValue" SG_ 534 Dimmer 127;
BA_ "GenSigSendType" SG_ 534 Dimmer 3;
BA_ "GenSigSendType" SG_ 534 LockSetting 3;
BA_ "GenSigSendType" SG_ 534 BCM_Buzzer_Req 3;
BA_ "GenSigSendType" SG_ 534 TailgateRemote 3;
BA_ "GenSigSendType" SG_ 534 RoomLampL 3;
BA_ "GenSigSendType" SG_ 534 RoomLampH 3;
BA_ "GenSigSendType" SG_ 534 DimmerEN 3;
BA_ "GenSigSendType" SG_ 534 BCM_DoorLock_Sta 3;
BA_ "GenSigSendType" SG_ 534 HornCtrl 3;
BA_ "GenSigSendType" SG_ 534 CrashDetd 3;
BA_ "GenSigSendType" SG_ 534 L_APM_WdwEnable 3;
BA_ "GenSigStartValue" SG_ 553 EPS_Pwr_Consumpt_V 1;
BA_ "GenSigStartValue" SG_ 553 EPS_VOL_V 1;
BA_ "GenSigStartValue" SG_ 553 EPS_Temp_V 1;
BA_ "GenSigStartValue" SG_ 553 EPS_Pwr_Limit_V 1;
BA_ "GenSigStartValue" SG_ 553 Steering_Torque_V 1;
BA_ "GenSigStartValue" SG_ 553 EPS_Temp 100;
BA_ "GenSigInvalidValue" SG_ 566 APS_Angle_Target 65535;
BA_ "GenSigSendType" SG_ 602 ODOMETER 3;
BA_ "GenSigSendType" SG_ 602 Trip_A 3;
BA_ "GenSigSendType" SG_ 602 Trip_B 3;
BA_ "GenSigSendType" SG_ 602 ParkBrake 3;
BA_ "GenSigSendType" SG_ 602 Charge 3;
BA_ "GenSigSendType" SG_ 602 LEDlitWarnReq 3;
BA_ "GenSigInvalidValue" SG_ 602 Spd_Crl_Mode 5;
BA_ "GenSigInvalidValue" SG_ 602 AvailableTrip 65535;
BA_ "GenSigInvalidValue" SG_ 602 APCforDTE 65535;
BA_ "GenSigStartValue" SG_ 602 APCforDTE 9999;
BA_ "GenSigInvalidValue" SG_ 602 AVGPwrConsumption 65535;
BA_ "GenSigStartValue" SG_ 602 AVGPwrConsumption 9999;
BA_ "GenSigInvalidValue" SG_ 602 Averaged_vehspeed 1023;
BA_ "GenSigInvalidValue" SG_ 602 METER_MPH_Real 4095;
BA_ "GenSigInvalidValue" SG_ 602 METER_KPH_Real 4095;
BA_ "GenSigInvalidValue" SG_ 602 METER_MPH_Calcu 255;
BA_ "GenSigInvalidValue" SG_ 602 METER_KPH_Calcu 255;
BA_ "GenSigSendType" SG_ 659 Set_Spd 3;
BA_ "GenSigInvalidValue" SG_ 659 RegenMode 7;
BA_ "GenSigSendType" SG_ 659 RegenMode 3;
BA_ "GenSigSendType" SG_ 659 Zone_Spd_Ctrl_Sta 3;
BA_ "GenSigInvalidValue" SG_ 659 Zone_Spd_Ctrl_Mode 5;
BA_ "GenSigSendType" SG_ 659 Zone_Spd_Ctrl_Mode 3;
BA_ "GenSigSendType" SG_ 826 SWC_LKA_Sta 3;
BA_ "GenSigSendType" SG_ 826 SWC_Undefined_Sta 3;
BA_ "GenSigSendType" SG_ 826 SWC_VR_Sta 3;
BA_ "GenSigSendType" SG_ 826 SWC_Up_Sta 3;
BA_ "GenSigSendType" SG_ 826 SWC_Trip_Sta 3;
BA_ "GenSigSendType" SG_ 826 SWC_Set_down_Sta 3;
BA_ "GenSigSendType" SG_ 826 SWC_Right_Sta 3;
BA_ "GenSigSendType" SG_ 826 SWC_RegenDown 3;
BA_ "GenSigSendType" SG_ 826 SWC_Res_Up_Sta 3;
BA_ "GenSigSendType" SG_ 826 SWC_mode_Sta 3;
BA_ "GenSigSendType" SG_ 826 SWC_Left_Sta 3;
BA_ "GenSigSendType" SG_ 826 SWC_RegenUp 3;
BA_ "GenSigSendType" SG_ 826 SWC_Down_Sta 3;
BA_ "GenSigSendType" SG_ 826 SWC_Distance_Sta 3;
BA_ "GenSigSendType" SG_ 826 SWC_ACC_Sta 3;
BA_ "GenSigSendType" SG_ 826 SWC_CANCEL_Sta 3;
BA_ "GenSigSendType" SG_ 960 VehMalfunLevel 3;
BA_ "GenSigSendType" SG_ 960 Eng_AGSCloseSta 3;
BA_ "GenSigInvalidValue" SG_ 960 Eng_PwrLockSta 2;
BA_ "GenSigSendType" SG_ 960 Eng_PwrLockSta 3;
BA_ "GenSigInvalidValue" SG_ 960 Eng_CoastDwSta 2;
BA_ "GenSigSendType" SG_ 960 Eng_CoastDwSta 3;
BA_ "GenSigInvalidValue" SG_ 960 Eng_ActvDmpDisabSta 2;
BA_ "GenSigSendType" SG_ 960 Eng_ActvDmpDisabSta 3;
BA_ "GenSigSendType" SG_ 1173 AVM_parking_cancel 3;
BA_ "GenSigSendType" SG_ 1173 AVM_parking_excute 3;
BA_ "GenSigSendType" SG_ 1173 AVM_OFF_Rec_Butt 3;
BA_ "GenSigInvalidValue" SG_ 1173 IVI_AGSCloseSW 2;
BA_ "GenSigSendType" SG_ 1173 IVI_AGSCloseSW 3;
BA_ "GenSigInvalidValue" SG_ 1173 IVI_LVChrgFuncSW 2;
BA_ "GenSigSendType" SG_ 1173 IVI_LVChrgFuncSW 3;
BA_ "GenSigInvalidValue" SG_ 1173 IVI_PwrLockSW 2;
BA_ "GenSigSendType" SG_ 1173 IVI_PwrLockSW 3;
BA_ "GenSigInvalidValue" SG_ 1173 IVI_CoastDwSW 2;
BA_ "GenSigSendType" SG_ 1173 IVI_CoastDwSW 3;
BA_ "GenSigInvalidValue" SG_ 1173 IVI_ActvDmpDisabSW 2;
BA_ "GenSigSendType" SG_ 1173 IVI_ActvDmpDisabSW 3;
BA_ "GenSigInvalidValue" SG_ 1173 Roll_Mode_SW_Cmd 3;
BA_ "GenSigSendType" SG_ 1173 Roll_Mode_SW_Cmd 3;
BA_ "GenSigInvalidValue" SG_ 1173 TCS_SW_Cmd 3;
BA_ "GenSigSendType" SG_ 1173 TCS_SW_Cmd 3;
BA_ "GenSigInvalidValue" SG_ 1173 SLIF_BUTT 3;
BA_ "GenSigSendType" SG_ 1173 SLIF_BUTT 3;
BA_ "GenSigSendType" SG_ 1173 Roll_Eng_Mode 3;
BA_ "GenSigInvalidValue" SG_ 1173 SOC_Limit_Set 31;
BA_ "GenSigStartValue" SG_ 1173 SOC_Limit_Set 25;
BA_ "GenSigSendType" SG_ 1173 CDL_Lock_Butt 3;
BA_ "GenSigSendType" SG_ 1173 CDL_Unlock_Butt 3;
BA_ "GenSigSendType" SG_ 1173 SOC_ADJ_BUTT 3;
BA_ "GenSigSendType" SG_ 1173 AC_Chg_Cur_Set 3;
BA_ "GenSigInvalidValue" SG_ 1173 IVI_ISA_OffsetSpd 15;
BA_ "GenSigSendType" SG_ 1173 IVI_RR_Def_Req 3;
BA_ "GenSigInvalidValue" SG_ 1173 CAAS_Sw 2;
BA_ "GenSigSendType" SG_ 1173 CAAS_Sw 3;
BA_ "GenSigSendType" SG_ 1173 IVI_PTG_Mode_SW 3;
BA_ "GenSigSendType" SG_ 1173 IVI_PTG_Sta_SW 3;
BA_ "GenSigInvalidValue" SG_ 1173 MFRD_N_Bright_Req 127;
BA_ "GenSigSendType" SG_ 1173 MFRD_N_Bright_Req 3;
BA_ "GenSigSendType" SG_ 1173 HeadLampSW 3;
BA_ "GenSigInvalidValue" SG_ 1173 OFF_AC_MODE 7;
BA_ "GenSigSendType" SG_ 1173 OFF_AC_MODE 3;
BA_ "GenSigSendType" SG_ 1173 TurnSwTimeSet 3;
BA_ "GenSigSendType" SG_ 1173 ESC_SW_Cmd 3;
BA_ "GenSigSendType" SG_ 1173 sigHvacRearReq 3;
BA_ "GenSigStartValue" SG_ 1173 sigWindDirZon3Req 7;
BA_ "GenSigSendType" SG_ 1173 sigWindDirZon3Req 3;
BA_ "GenSigSendType" SG_ 1173 sigAirIntenZon3Req 3;
BA_ "GenSigSendType" SG_ 1173 sigAirIntenZon1Req 3;
BA_ "GenSigSendType" SG_ 1173 sigSetTempZon3Req 3;
BA_ "GenSigSendType" SG_ 1173 sigSetTempZon2Req 3;
BA_ "GenSigSendType" SG_ 1173 sigRecircReq 3;
BA_ "GenSigSendType" SG_ 1173 sigHvacReq 3;
BA_ "GenSigSendType" SG_ 1173 sigSetTempZon1Req 3;
BA_ "GenSigSendType" SG_ 1173 sigHvacFrontReq 3;
BA_ "GenSigSendType" SG_ 1173 sigDfrstReq 3;
BA_ "GenSigStartValue" SG_ 1173 L_Drv_ControlCommand 127;
BA_ "GenSigRoutingTimeoutValue" SG_ 1173 L_Drv_ControlCommand 127;
BA_ "GenSigStartValue" SG_ 1173 L_Pas_ControlCommand 127;
BA_ "GenSigRoutingTimeoutValue" SG_ 1173 L_Pas_ControlCommand 127;
BA_ "GenSigStartValue" SG_ 1173 L_RLD_ControlCommand 127;
BA_ "GenSigRoutingTimeoutValue" SG_ 1173 L_RLD_ControlCommand 127;
BA_ "GenSigStartValue" SG_ 1173 L_RRD_ControlCommand 127;
BA_ "GenSigRoutingTimeoutValue" SG_ 1173 L_RRD_ControlCommand 127;
BA_ "GenSigInvalidValue" SG_ 1173 METER_Malfunc_Sta 3;
BA_ "GenSigSendType" SG_ 1173 sigFootReq 3;
BA_ "GenSigSendType" SG_ 1173 sigFaceReq 3;
BA_ "GenSigSendType" SG_ 1173 Sched_Chg_Start 3;
BA_ "GenSigSendType" SG_ 1173 Sched_Chg_wake 3;
BA_ "GenSigSendType" SG_ 1173 Sched_Chg_Stop 3;
BA_ "GenSigInvalidValue" SG_ 1173 Sched_Chg_limit 31;
BA_ "GenSigStartValue" SG_ 1173 Sched_Chg_limit 25;
BA_ "GenSigInvalidValue" SG_ 1173 SOC_V2LLimit 15;
BA_ "GenSigSendType" SG_ 1173 IVI_PTG_Open_Height 3;
BA_ "GenSigSendType" SG_ 1173 IVI_CreepSW_Req 3;
BA_ "GenSigStartValue" SG_ 1173 FalseNPrevent_SW 1;
BA_ "GenSigStartValue" SG_ 1173 Approach_Unlock_SW 1;
BA_ "GenSigSendType" SG_ 1173 Approach_Unlock_SW 3;
BA_ "GenSigStartValue" SG_ 1173 Walkaway_Lock_SW 1;
BA_ "GenSigSendType" SG_ 1173 Walkaway_Lock_SW 3;
BA_ "GenSigSendType" SG_ 1280 NM_FUSION_Node_ID 7;
BA_ "GenSigSendType" SG_ 1280 NM_FUSION_Rpt_Msg_Req 7;
BA_ "GenSigSendType" SG_ 1280 NM_FUSION_CSB 7;
BA_ "GenSigSendType" SG_ 1280 NM_FUSION_Active_WU 7;
BA_ "GenSigSendType" SG_ 1280 NM_FUSION_PNI 7;
BA_ "GenSigSendType" SG_ 1280 NM_FUSION_ERROR_State 7;
BA_ "GenSigSendType" SG_ 1281 NM_ESC_Node_ID 7;
BA_ "GenSigSendType" SG_ 1281 NM_ESC_Rpt_Msg_Req 7;
BA_ "GenSigSendType" SG_ 1281 NM_ESC_CSB 7;
BA_ "GenSigSendType" SG_ 1281 NM_ESC_Active_WU 7;
BA_ "GenSigSendType" SG_ 1281 NM_ESC_PNI 7;
BA_ "GenSigSendType" SG_ 1281 NM_ESC_ERROR_State 7;
BA_ "GenSigSendType" SG_ 1296 NM_FCM_Node_ID 7;
BA_ "GenSigSendType" SG_ 1296 NM_FCM_Rpt_Msg_Req 7;
BA_ "GenSigSendType" SG_ 1296 NM_FCM_CSB 7;
BA_ "GenSigSendType" SG_ 1296 NM_FCM_Active_WU 7;
BA_ "GenSigSendType" SG_ 1296 NM_FCM_PNI 7;
BA_ "GenSigSendType" SG_ 1296 NM_FCM_ERROR_State 7;
BA_ "GenSigSendType" SG_ 1297 NM_eBST_Node_ID 7;
BA_ "GenSigSendType" SG_ 1297 NM_eBST_Rpt_Msg_Req 7;
BA_ "GenSigSendType" SG_ 1297 NM_eBST_CSB 7;
BA_ "GenSigSendType" SG_ 1297 NM_eBST_Active_WU 7;
BA_ "GenSigSendType" SG_ 1297 NM_eBST_PNI 7;
BA_ "GenSigSendType" SG_ 1297 NM_eBST_ERROR_State 7;
BA_ "GenSigSendType" SG_ 1298 NM_SRR_M_Node_ID 7;
BA_ "GenSigSendType" SG_ 1298 NM_SRR_M_Rpt_Msg_Req 7;
BA_ "GenSigSendType" SG_ 1298 NM_SRR_M_CSB 7;
BA_ "GenSigSendType" SG_ 1298 NM_SRR_M_Active_WU 7;
BA_ "GenSigSendType" SG_ 1298 NM_SRR_M_PNI 7;
BA_ "GenSigSendType" SG_ 1298 NM_SRR_M_ERROR_State 7;
BA_ "GenSigSendType" SG_ 1313 NM_EPAS_Node_ID 7;
BA_ "GenSigSendType" SG_ 1313 NM_EPAS_Rpt_Msg_Req 7;
BA_ "GenSigSendType" SG_ 1313 NM_EPAS_CSB 7;
BA_ "GenSigSendType" SG_ 1313 NM_EPAS_Active_WU 7;
BA_ "GenSigSendType" SG_ 1313 NM_EPAS_PNI 7;
BA_ "GenSigSendType" SG_ 1313 NM_EPAS_ERROR_State 7;
BA_ "GenSigSendType" SG_ 1329 NM_ABM_Node_ID 7;
BA_ "GenSigSendType" SG_ 1329 NM_ABM_Rpt_Msg_Req 7;
BA_ "GenSigSendType" SG_ 1329 NM_ABM_CSB 7;
BA_ "GenSigSendType" SG_ 1329 NM_ABM_Active_WU 7;
BA_ "GenSigSendType" SG_ 1329 NM_ABM_PNI 7;
BA_ "GenSigSendType" SG_ 1329 NM_ABM_ERROR_State 7;
BA_ "GenSigSendType" SG_ 1537 DiagRespFromESC 3;
BA_ "GenSigSendType" SG_ 1552 DiagRespFromFCM 3;
BA_ "GenSigSendType" SG_ 1553 DiagRespFromeBST 3;
BA_ "GenSigSendType" SG_ 1554 DiagRespFromSRR_M 3;
BA_ "GenSigSendType" SG_ 1557 DiagRespFromMRR 3;
BA_ "GenSigSendType" SG_ 1569 DiagRespFromEPAS 3;
BA_ "GenSigSendType" SG_ 1585 DiagRespFromABM 3;
BA_ "GenSigSendType" SG_ 1665 DiagPhysReqToESC 3;
BA_ "GenSigSendType" SG_ 1680 DiagPhysReqToFCM 3;
BA_ "GenSigSendType" SG_ 1681 DiagPhysReqToeBST 3;
BA_ "GenSigSendType" SG_ 1682 DiagPhysReqToSRR_M 3;
BA_ "GenSigSendType" SG_ 1685 DiagPhysReqToMRR 3;
BA_ "GenSigSendType" SG_ 1697 DiagPhysReqToEPAS 3;
BA_ "GenSigSendType" SG_ 1713 DiagPhysReqToABM 3;
BA_ "GenSigSendType" SG_ 2000 DiagFuncReqFT 3;
BA_ "GenSigSendType" SG_ 2002 XCPReqToESC 3;
BA_ "GenSigSendType" SG_ 2003 XCPRespFromESC 3;
BA_ "GenSigSendType" SG_ 2004 XCPReqToeBST 3;
BA_ "GenSigSendType" SG_ 2005 XCPRespFromeBST 3;
BA_ "GenSigSendType" SG_ 2040 CCP1ReqToEPAS 3;
BA_ "GenSigSendType" SG_ 2041 CCP1RespFromEPAS 3;
BA_ "GenSigSendType" SG_ 550 DrLockSta 3;
BA_ "GenSigSendType" SG_ 550 PsLockSta 3;
BA_ "GenSigSendType" SG_ 550 RLLockSta 3;
BA_ "GenSigSendType" SG_ 550 RRLockSta 3;
BA_ "GenSigSendType" SG_ 550 AllLockSta 3;
BA_ "GenSigSendType" SG_ 550 MIRROR_FOLD_SW 3;
BA_ "GenSigSendType" SG_ 550 RWiperAS 3;
BA_ "GenSigSendType" SG_ 550 RWiperProtection 3;
BA_ "GenSigSendType" SG_ 550 Wip_Speed 3;
BA_ "GenSigRoutingTimeoutValue" SG_ 550 CSW_RWipIntSw_Sta 3;
BA_ "GenSigSendType" SG_ 550 CSW_RWipIntSw_Sta 3;
BA_ "GenSigSendType" SG_ 550 CSW_DimSw 3;
BA_ "GenSigSendType" SG_ 550 BrakeLampFail 3;
BA_ "GenSigSendType" SG_ 550 CSW_PassSW_Sta 3;
BA_ "GenSigSendType" SG_ 550 RLS_Exist 3;
BA_ "GenSigSendType" SG_ 550 RLTurnLampC 3;
BA_ "GenSigSendType" SG_ 550 RRTurnLampC 3;
BA_ "GenSigRoutingTimeoutValue" SG_ 550 CSW_FWasSw_Sta 3;
BA_ "GenSigSendType" SG_ 550 CSW_FWasSw_Sta 3;
BA_ "GenSigRoutingTimeoutValue" SG_ 550 CSW_RWasSW_Sta 3;
BA_ "GenSigSendType" SG_ 550 CSW_RWasSW_Sta 3;
BA_ "GenSigRoutingTimeoutValue" SG_ 550 CSW_TurnSw_Sta 3;
BA_ "GenSigSendType" SG_ 550 CSW_TurnSw_Sta 3;
BA_ "GenSigSendType" SG_ 550 HornSW 3;
BA_ "GenSigRoutingTimeoutValue" SG_ 550 CSW_FWipSw_Sta 7;
BA_ "GenSigSendType" SG_ 550 CSW_FWipSw_Sta 3;
BA_ "GenSigSendType" SG_ 550 RLS_RainSnrWiperCmd 3;
BA_ "GenSigSendType" SG_ 550 RLS_Lamp_Sta 3;
BA_ "GenSigSendType" SG_ 550 RLS_LIN_Resp_Err 3;
BA_ "GenSigSendType" SG_ 550 RLS_LightSnrErr 3;
BA_ "GenSigSendType" SG_ 550 RLS_RainSnrErr 3;
BA_ "GenSigSendType" SG_ 550 WiperSWPos 3;
BA_ "GenSigSendType" SG_ 550 WiperZeroPosSW 3;
BA_ "GenSigSendType" SG_ 550 AutoLightSW 3;
BA_ "GenSigSendType" SG_ 550 CSW_resp_error 3;
VAL_ 278 XWDMode 2 "AWD" 1 "FWD" 0 "RWD";
VAL_ 278 LVPwrSta 1 "LV power active" 0 "LV power inactive";
VAL_ 278 HVPwrSta 1 "HV power active" 0 "HV power inactive";
VAL_ 278 PwrSta 5 "READY" 4 "ON" 3 "STANDBY" 2 "OFF-After-Run" 1 "OFF-Charging" 0 "OFF";
VAL_ 278 PrkReq 1 "Parking Requested" 0 "Parking Released";
VAL_ 278 ShiftGearPosn 7 "Reverse" 6 "Failure" 5 "Drive" 4 "Neutral" 3 "Not used" 2 "Not used" 1 "Not used" 0 "Park";
VAL_ 278 CC_Crl_Sta 7 "Pedal Override" 6 "Invalid" 5 "Error" 4 "Over Speed" 3 "Under Speed" 2 "Active" 1 "Standby" 0 "Off";
VAL_ 278 MSA_Crl_Sta 7 "Pedal Override" 6 "Invalid" 5 "Error" 4 "Over Speed" 3 "Under Speed" 2 "Active" 1 "Standby" 0 "Off";
VAL_ 278 PrkReqValid 1 "Invalid" 0 "Valid";
VAL_ 278 P_Button_Sta 2 "Invalid" 1 "Pressed" 0 "Released";
VAL_ 338 Fr_PTCS_Active 1 "Active" 0 "Inactive";
VAL_ 338 Rr_PTCS_Active 1 "Active" 0 "Inactive";
VAL_ 339 BrkPedalPos_Sta 1 "Valid" 0 "Invalid";
VAL_ 339 RDC_Active 2 "Exit Immediately" 1 "Ramp out" 0 "No Request";
VAL_ 339 Fr_RBC_Active 1 "Active" 0 "Inactive";
VAL_ 339 Rr_RBC_Active 1 "Active" 0 "Inactive";
VAL_ 340 AccPedal_Override 1 "Acceleration Pedal Override" 0 "No Override";
VAL_ 340 ACC_CtrlAvail 1 "Available" 0 "Unavailable";
VAL_ 342 LF_RawWhlSpeed_V 1 "Invalid" 0 "Valid";
VAL_ 342 LF_WhlRotDir 3 "Standstill" 2 "Backward" 1 "Forward" 0 "Unknown/Standby";
VAL_ 342 LF_PulseCount_V 1 "Invalid" 0 "Valid";
VAL_ 342 RF_RawWhlSpeed_V 1 "Invalid" 0 "Valid";
VAL_ 342 RF_WhlRotDir 3 "Standstill" 2 "Backward" 1 "Forward" 0 "Unknown/Standby";
VAL_ 342 RF_PulseCount_V 1 "Invalid" 0 "Valid";
VAL_ 343 LR_RawWhlSpeed_V 1 "Invalid" 0 "Valid";
VAL_ 343 LR_WhlRotDir 3 "Standstill" 2 "Backward" 1 "Forward" 0 "Unknown/Standby";
VAL_ 343 LR_PulseCount_V 1 "Invalid" 0 "Valid";
VAL_ 343 RR_RawWhlSpeed_V 1 "Invalid" 0 "Valid";
VAL_ 343 RR_WhlRotDir 3 "Standstill" 2 "Backward" 1 "Forward" 0 "Unknown/Standby";
VAL_ 343 RR_PulseCount_V 1 "Invalid" 0 "Valid";
VAL_ 345 Fr_EDUAvailBrkRgnTqValid 1 "Invalid" 0 "Valid";
VAL_ 345 Rr_EDUAvailBrkRgnTqValid 1 "Invalid" 0 "Valid";
VAL_ 345 EquivAccPedalSWSta 1 "On" 0 "Off";
VAL_ 345 PTCS_PermSta 1 "Permission" 0 "Prohibition";
VAL_ 345 Rr_RgnPermSta 1 "Permission" 0 "Prohibition or FWD";
VAL_ 345 Fr_RgnPermSta 1 "Permission" 0 "Prohibition or RWD";
VAL_ 345 Rr_RgnDecrSta 1 "Not Decrease" 0 "Decrease or FWD";
VAL_ 345 Fr_RgnDecrSta 1 "Not Decrease" 0 "Decrease or RWD";
VAL_ 345 RgnAbnorSta 1 "Abnormal" 0 "Normal";
VAL_ 345 Rr_EDUSpdValid 1 "Invalid" 0 "Valid";
VAL_ 345 Fr_EDUSpdValid 1 "Invalid" 0 "Valid";
VAL_ 360 LowBrakeFluid_Sta 1 "Low" 0 "Normal";
VAL_ 360 eBST_AmberWnlmpSta 1 "On" 0 "Off";
VAL_ 360 eBST_RedWnlmpSta 1 "On" 0 "Off";
VAL_ 360 eBST_BeepReq 1 "Request" 0 "No Request";
VAL_ 377 ADAS_AEBReq 3 "Request Level III" 2 "Request Level II" 1 "Request Level I" 0 "No Request";
VAL_ 377 ADAS_FaultSta 1 "Fault" 0 "Normal";
VAL_ 377 AEB_VehHoldReq 1 "Request" 0 "No Request";
VAL_ 377 ADAS_DBSReq 3 "DBS Level III" 2 "DBS Level II" 1 "DBS Level I" 0 "No Request";
VAL_ 377 ACC_VehHoldReq 1 "Request" 0 "No Request";
VAL_ 380 ADAS_ForceIdle 1 "Force Idle" 0 "No Force Idle";
VAL_ 380 ADAS_ShftPosnReq 7 "Reverse" 4 "Ds" 3 "D" 2 "Neutral" 1 "Park" 0 "No Request";
VAL_ 380 ADAS_ShftPosnReq_A 1 "Applicable" 0 "Not Applicable";
VAL_ 386 FD_AGS_Cmd 208 "78^Deg" 240 "90^Deg" 176 "66^Deg" 144 "54^Deg" 112 "42^Deg" 80 "30^Deg" 48 "18^Deg" 16 "6^Deg" 224 "84^Deg" 192 "72^Deg" 160 "60^Deg" 128 "48^Deg" 96 "36^Deg" 64 "24^Deg" 32 "12^Deg" 0 "0^Deg";
VAL_ 386 CabinMode 9 "Cabin Heating Mode 2" 8 "Cabin Heating Mode 1" 7 "Cabin Dehumidity Mode 4" 6 "Cabin Dehumidity Mode 3" 5 "Cabin Dehumidity Mode 2" 4 "Cabin Dehumidity Mode 1" 3 "Mode 1" 2 "Comp On" 1 "Comp Off" 0 "OFF";
VAL_ 386 BatteryMode 5 "Active Heating" 4 "Passive Heating" 3 "Isothermal Cycle" 2 "Passive Cooling" 1 "Active Cooling" 0 "OFF";
VAL_ 386 FD_RecyAuto_Cmd 6 "reserved" 5 "reserved" 4 "100% out recycle" 3 "70% out recycle" 2 "50% out recycle" 1 "30% out recycle" 0 "0% out recycle";
VAL_ 386 EDriveMode 2 "Waste Heat Recovery" 1 "Cooling" 0 "OFF";
VAL_ 386 HPThermalRecoveryReq 1 "Request" 0 "Not Request";
VAL_ 386 sigHvacSt 1 "ON" 0 "OFF";
VAL_ 386 sigRecircSt 1 "ON" 0 "OFF";
VAL_ 386 sigDfrstSt 1 "ON" 0 "OFF";
VAL_ 386 CCU_SyncLampSts 1 "Lamp ON" 0 "Lamp OFF";
VAL_ 386 sigAirIntenZon3St 15 "Invalid" 14 "Reserved" 11 "Reserved" 10 "NOT set" 9 "Level 8" 8 "Level 7" 7 "Level 6" 6 "Level 5" 5 "Level 4" 4 "Level 3" 3 "Level 2" 2 "Level 1" 1 "OFF" 0 "NO display / No request";
VAL_ 386 sigAirIntenZon1St 15 "Invalid" 14 "Reserved" 11 "Reserved" 10 "NOT set" 9 "Level 8" 8 "Level 7" 7 "Level 6" 6 "Level 5" 5 "Level 4" 4 "Level 3" 3 "Level 2" 2 "Level 1" 1 "OFF" 0 "NO display / No request";
VAL_ 386 sigWindDirZon3St 7 "NOT Set / Reserved" 6 "All open" 5 "Face + Screen" 4 "DEFOG" 3 "Foot + Screen" 2 "Foot" 1 "Bilevel" 0 "FACE";
VAL_ 386 CCU_FrtOnOffLampSts 1 "Lamp ON" 0 "Lamp OFF";
VAL_ 386 sigWindDirZon1St 7 "NOT Set / Reserved" 6 "All open" 5 "Face + Screen" 4 "DEFOG" 3 "Foot + Screen" 2 "Foot" 1 "Bilevel" 0 "FACE";
VAL_ 386 CCU_RrOnOffLampSts 1 "Lamp ON" 0 "Lamp OFF";
VAL_ 386 CCU_ACMaxLampSts 1 "Lamp ON" 0 "Lamp OFF";
VAL_ 386 CCU_AutoLampSts 1 "Lamp ON" 0 "Lamp OFF";
VAL_ 386 CCU_AutoMidLampSts 1 "Lamp ON" 0 "Lamp OFF";
VAL_ 386 CCU_EcoSts 1 "Lamp ON" 0 "Lamp OFF";
VAL_ 386 CCU_ACLampSts 1 "Lamp ON" 0 "Lamp OFF";
VAL_ 386 CCU_HEATMaxLampSts 1 "Lamp ON" 0 "Lamp OFF";
VAL_ 391 DriIntend 2 "Driver Interrupt" 1 "Hands off steering wheel" 0 "Hands on steering wheel";
VAL_ 391 EPS_AOI_Control 3 "Permanently Fail" 2 "Controlled" 1 "Available for control" 0 "Control Inhibit";
VAL_ 391 EPS_TOI_Fault 1 "Fault" 0 "No Fault";
VAL_ 410 SAS_Speed_Valid 1 "Valid" 0 "Invalid";
VAL_ 410 SAS_CAL 1 "Calibrated" 0 "Non-calibrated";
VAL_ 410 SAS_V 1 "Valid" 0 "Invalid";
VAL_ 419 Red_WnlmpSta 1 "Red Wnlmp constant" 0 "Red Wnlmp Off";
VAL_ 419 ABS_WnlmpSta 1 "ABS Wnlmp constant" 0 "ABS Wnlmp Off";
VAL_ 419 ESC_Off_lmpSta 1 "ESC OFF lmp permanent" 0 "ESC OFF lmp Off";
VAL_ 419 ESC_WnlmpSta 2 "ESC lmp flash" 1 "ESC lmp permanent" 0 "ESC lmp Off";
VAL_ 419 EBD_Active 1 "Active" 0 "Inactive";
VAL_ 419 ABS_Active 1 "Active" 0 "Inactive";
VAL_ 419 TCS_Active 1 "Active" 0 "Inactive";
VAL_ 419 ESC_Active 1 "Active" 0 "Inactive";
VAL_ 419 HBB_Active 1 "Active" 0 "Inactive";
VAL_ 419 PBA_Active 1 "Active" 0 "Inactive";
VAL_ 419 HSA_Active 1 "Active" 0 "Inactive";
VAL_ 419 AVH_Active 1 "Active" 0 "Inactive";
VAL_ 419 Amber_WnlmpSta 1 "Amber Wnlmp constant" 0 "Amber Wnlmp Off";
VAL_ 419 BTCS_Active 1 "Active" 0 "Inactive";
VAL_ 419 ESS_Active 1 "Active" 0 "Inactive";
VAL_ 419 HDD_Active 1 "Active" 0 "Inactive";
VAL_ 419 EBD_Failed 1 "Failed" 0 "Normal";
VAL_ 419 ABS_Failed 1 "Failed" 0 "Normal";
VAL_ 419 TCS_Failed 1 "Failed" 0 "Normal";
VAL_ 419 ESC_Failed 1 "Failed" 0 "Normal";
VAL_ 419 HBB_Failed 1 "Failed" 0 "Normal";
VAL_ 419 PBA_Failed 1 "Failed" 0 "Normal";
VAL_ 419 HSA_Failed 1 "Failed" 0 "Normal";
VAL_ 419 AVH_Failed 1 "Failed" 0 "Normal";
VAL_ 419 HDD_Failed 1 "Failed" 0 "Normal";
VAL_ 419 ESC_OFF_Status 2 "TCS and ESC OFF" 1 "TCS OFF" 0 "Normal";
VAL_ 419 ESC_BeepReq 1 "Request" 0 "No Request";
VAL_ 421 YawRate_V 1 "Invalid" 0 "Valid";
VAL_ 421 LatAccel_V 1 "Invalid" 0 "Valid";
VAL_ 421 LongAccel_V 1 "Invalid" 0 "Valid";
VAL_ 421 MCPressure_V 1 "Invalid" 0 "Valid";
VAL_ 421 BrkSw_Sta 1 "Active" 0 "Inactive";
VAL_ 421 BrkSw_V 1 "Invalid" 0 "Valid";
VAL_ 425 ACCAvail 1 "Available" 0 "Unavailable";
VAL_ 425 BrkDiscTempSta 1 "Over Temperature" 0 "Nomal";
VAL_ 425 ESC_Standstill 1 "Standstill" 0 "Not Standstill";
VAL_ 425 DecErrSta 1 "Error" 0 "Nomal";
VAL_ 425 ActBrkLamp_Sta 1 "On" 0 "Off";
VAL_ 425 AEBAvail 1 "Available" 0 "Unavailable";
VAL_ 425 ESC_ADAS_Sta 6 "Haptic Brake" 5 "Vehicle Standstill" 4 "Vehicle Holding" 3 "Deceleration Control" 2 "AEB Emergency Brake" 1 "Prefill" 0 "Internal";
VAL_ 425 ESC_APS_Sta 5 "APS Unavailable(ESC Failed)" 4 "Standstill with EPB" 3 "Standstill with Brake Hold" 2 "Decel Control" 1 "Standby(Ready)" 0 "Off";
VAL_ 427 EPBExtReleaseAvail 1 "Available" 0 "Unavailable";
VAL_ 427 EPBExtApplyAvail 1 "Available" 0 "Unavailable";
VAL_ 427 EPBCarWashMode 1 "Car Wash mode" 0 "Not Car wash mode";
VAL_ 427 DOA_Sta 1 "Enabled" 0 "Disabled";
VAL_ 427 EPBStaL 7 "Invalid" 6 "CompletelyReleased" 5 "Released" 4 "Releasing" 3 "Applying" 2 "HoldApplied" 1 "ParkApplied" 0 "Unknown";
VAL_ 427 TakeOverReq 1 "On (Controlled by Backup EPB)" 0 "Off (Controlled by ESC)";
VAL_ 427 EPBStaR 7 "Invalid" 6 "CompletelyReleased" 5 "Released" 4 "Releasing" 3 "Applying" 2 "HoldApplied" 1 "ParkApplied" 0 "Unknown";
VAL_ 427 EPBErrSta 2 "Diagnostic Mode" 1 "Failed" 0 "Normal";
VAL_ 427 EPBRLampSta 2 "Flash" 1 "Permanent" 0 "Off";
VAL_ 427 EPBSta 4 "Unknown" 3 "Releasing" 2 "Released" 1 "Applying" 0 "Applied";
VAL_ 427 EPBMsg 12 "Fasten driver seat belt" 11 "Press brake pedal to release Auto-Hold(Reserved)" 10 "Close driver side door(AVH)" 9 "EPB failed while AVH is activate" 8 "Please release park brake" 7 "Recalibration in progress" 6 "Depress Brake Pedal" 5 "Close driver-side door(DAR)" 4 "Rollerbench  Mode" 3 "Maintenance Mode" 2 "Slope Too Steep" 1 "Apply park brake" 0 "None";
VAL_ 515 AirBagFailCmd 1 "Lamp ON" 0 "Lamp OFF";
VAL_ 515 DriverSeatBeltCmd 1 "Lamp ON" 0 "Lamp OFF";
VAL_ 515 PsngrSeatBeltCmd 1 "Lamp ON" 0 "Lamp OFF";
VAL_ 515 PABSwitchCmd 1 "Lamp ON" 0 "Lamp OFF";
VAL_ 515 RDriverSeatBeltCmd 1 "Lamp ON" 0 "Lamp OFF";
VAL_ 515 RPsngrSeatBeltCmd 1 "Lamp ON" 0 "Lamp OFF";
VAL_ 515 RCenterSeatBeltCmd 1 "Lamp ON" 0 "Lamp OFF";
VAL_ 515 TLHPsngrSeatBeltCmd 1 "Lamp ON" 0 "Lamp OFF";
VAL_ 515 TRHPsngrSeatBeltCmd 1 "Lamp ON" 0 "Lamp OFF";
VAL_ 515 CrashOutputSts 8 "Right hand side" 2 "Front First level" 16 "Left hand side" 0 "No crash";
VAL_ 517 SRR_RCTA_WarnR 1 "Warning" 0 "No Warning";
VAL_ 517 SRR_RCTA_WarnL 1 "Warning" 0 "No Warning";
VAL_ 517 SRR_BSD_WarnR 2 "Flash" 1 "Lit" 0 "No Warning";
VAL_ 517 SRR_BSD_WarnL 2 "Flash" 1 "Lit" 0 "No Warning";
VAL_ 517 SRR_BSD_SoundR 1 "On" 0 "Off";
VAL_ 517 SRR_BSD_SoundL 1 "On" 0 "Off";
VAL_ 517 SRR_BSD_Mute 1 "Mute" 0 "No Mute";
VAL_ 517 SRR_ODA_WarnR 2 "Flash" 1 "Lit" 0 "No Warning";
VAL_ 517 SRR_ODA_WarnL 2 "Flash" 1 "Lit" 0 "No Warning";
VAL_ 517 SRR_ODA_SoundR 1 "On" 0 "Off";
VAL_ 517 SRR_ODA_SoundL 1 "On" 0 "Off";
VAL_ 517 SRR_ODA_Mute 1 "Mute" 0 "No Mute";
VAL_ 517 SRR_ODA_Sta 5 "Disable" 4 "Blockage" 3 "Failure" 2 "Active" 1 "Standby" 0 "Off";
VAL_ 517 SRR_BSD_Sta 5 "Disable" 4 "Blockage" 3 "Failure" 2 "Active" 1 "Standby" 0 "Off";
VAL_ 517 SRR_RCTA_Sta 5 "Disable" 4 "Blockage" 3 "Failure" 2 "Active" 1 "Standby" 0 "Off";
VAL_ 517 SRR_FltWrnReq 1 "Warning" 0 "No Warning";
VAL_ 528 PAS_A_FCL 4 "level 4 (Far distance)" 3 "level 3" 2 "level 2" 1 "level 1 (Near distance)" 0 "No signal";
VAL_ 528 PAS_Chime 9 "APS change gear warning" 8 "R_USS Obstacle warning level 3" 7 "R_USS Obstacle warning level 2" 6 "R_USS Obstacle warning level 1" 5 "F_USS Obstacle warning level 3" 4 "F_USS Obstacle warning level 2" 3 "F_USS Obstacle warning level 1" 2 "PAS and APS check fault warning" 1 "PAS and APS check normal warning" 0 "No message";
VAL_ 528 APS_RQ_Display 44 "APS Cancelled because gear position is wrong" 43 "APS Cancelled because POWER is not ready" 42 "Please make sure the doors are closed and the seat belts are fastened." 41 "APS Cancelled because IVI or AVM is not ready" 40 "Driver seat belt is not fastened" 39 "Operation Timeout 2 min Please take over the vehicle" 38 "Operation Timeout 6 min Please take over the vehicle" 37 "Operation Timeout 1 min Please take over the vehicle" 36 "VCU failed Please take over steering" 35 "APS Cancelled because driver enable the EPB" 34 "APS Cancelled because driver intervenes the acceleration pedal" 33 "APS Cancelled because driver Intervention gear Please take over steering" 32 "APS Cancelled because driver Intervention brake Please take over steering" 31 "APS Cancelled because driver Intervention steering Please take over steering" 30 "APS Cancelled by driver" 29 "APS Cancelled because found the unknow object Please take over steering" 28 "APS Cancelled because the door is opened Please take over steering" 27 "The gear is changing to R-gear" 26 "The gear is changing to D-gear" 25 "Vehicle moving backward" 24 "Vehicle moving forward" 23 "APS System Error Please take over steering" 22 "Steering assistant failed Please take over steering" 21 "ESC failed Please take over steering" 20 "Auto parking assistant active Please check around" 19 "Shift to P gear now" 18 "Parking Slot Undersize Please take over steering" 17 "Operation Timeout Please take over the vehicle" 16 "APS Cancelled Please take over the vehicle" 15 "APS Cancelled because the speed is too fast" 14 "Stop and ready for auto parking" 13 "Please drive forward" 12 "Vehicle stop" 11 "Parking achieved" 10 "Parking out Cancelled because the slot is too small" 9 "Obstacles appear on the way of driving" 8 "The left side perpendicular parking slot be found" 7 "The left side parallel parking slot be found" 6 "The right side perpendicular parking slot be found" 5 "The right side  parallel parking slot be found" 4 "Searching for perpendicular parking slot on the left side" 3 "Searching for parallel parking slot on the left side" 2 "Searching for perpendicular parking slot on the right side" 1 "Searching for parallel parking slot on the right side" 0 "No message";
VAL_ 528 PAS_D_RMR 255 "FarDistance" 150 "Max" 0 "Min";
VAL_ 528 PAS_D_RML 255 "FarDistance" 150 "Max" 0 "Min";
VAL_ 528 PAS_D_RCR 255 "FarDistance" 150 "Max" 0 "Min";
VAL_ 528 PAS_D_RCL 255 "FarDistance" 150 "Max" 0 "Min";
VAL_ 528 APS_ExitCondition 51 "ENUM_EXC_OSPARK" 50 "ENUM_EXC_DCTOOFARSlOTFIND" 49 "ENUM_EXC_TO4OBSTFRONT" 48 "ENUM_EXC_TO4OBSTREAR" 46 "ENUM_EXC_OCDRIVERINTERF" 45 "ENUM_EXC_OCPPSTOOSMALL" 44 "ENUM_EXC_OCDOORSOPEN" 43 "ENUM_EXC_OCSWITCHOFFAPA" 42 "ENUM_EXC_OCSWITCHOFFPA" 41 "ENUM_EXC_OCWRONGDIR" 40 "ENUM_EXC_OTEPSERROR" 39 "ENUM_EXC_OTEVCUERROR" 38 "ENUM_EXC_OTBRAKEERROR" 37 "ENUM_EXC_OTGEARERROR" 36 "ENUM_EXC_OTEPBERROR" 35 "ENUM_EXC_OTCANERROR" 34 "ENUM_EXC_OTAPAERROR" 33 "ENUM_EXC_OTSENSORERROR" 32 "ENUM_EXC_OTOEMERROR" 81 "ENUM_EXC_OSSCA" 80 "ENUM_EXC_OSSCAWARNING" 79 "ENUM_EXC_DCTOOFARSCA" 77 "ENUM_EXC_OCSCADOORSOPEN" 76 "ENUM_EXC_OCSCASWITCHOFFAPA" 75 "ENUM_EXC_OCSCASWITCHOFFPA" 74 "ENUM_EXC_OCSCAWRONGDIR" 73 "ENUM_EXC_OTSCACAMERAERROR" 72 "ENUM_EXC_OTSCAEPSERROR" 71 "ENUM_EXC_OTSCAEVCUERROR" 70 "ENUM_EXC_OTSCABRAKEERROR" 69 "ENUM_EXC_OTSCAGEARERROR" 68 "ENUM_EXC_OTSCAEPBERROR" 131 "ENUM_EXC_TO4STANDING" 67 "ENUM_EXC_OTSCACANERROR" 130 "ENUM_EXC_TO4STANDSTILL" 66 "ENUM_EXC_OTSCAAPAERROR" 129 "ENUM_EXC_OCGEARCOUNT" 65 "ENUM_EXC_OTSCASENSORERROR" 64 "ENUM_EXC_OTSCAOEMERROR" 0 "ENUM_EXC_NOERROR";
VAL_ 528 PAS_D_FMR 255 "FarDistance" 150 "Max" 0 "Min";
VAL_ 528 PAS_D_FML 255 "FarDistance" 150 "Max" 0 "Min";
VAL_ 528 PAS_D_FCR 255 "FarDistance" 150 "Max" 0 "Min";
VAL_ 528 PAS_D_FCL 255 "FarDistance" 150 "Max" 0 "Min";
VAL_ 528 PAS_SNSR_Layout 7 "PAS_R2" 6 "PAS_R2F2" 5 "PAS_R4" 4 "PAS_F2R4" 3 "PAS_F4R4" 2 "APA" 1 "APS" 0 "Nomassage";
VAL_ 528 PAS_A_RMR 4 "level 4 (Far distance)" 3 "level 3" 2 "level 2" 1 "level 1 (Near distance)" 0 "No signal";
VAL_ 528 PAS_A_RML 4 "level 4 (Far distance)" 3 "level 3" 2 "level 2" 1 "level 1 (Near distance)" 0 "No signal";
VAL_ 528 PAS_A_RCR 4 "level 4 (Far distance)" 3 "level 3" 2 "level 2" 1 "level 1 (Near distance)" 0 "No signal";
VAL_ 528 PAS_A_RCL 4 "level 4 (Far distance)" 3 "level 3" 2 "level 2" 1 "level 1 (Near distance)" 0 "No signal";
VAL_ 528 PAS_A_FMR 4 "level 4 (Far distance)" 3 "level 3" 2 "level 2" 1 "level 1 (Near distance)" 0 "No signal";
VAL_ 528 PAS_A_FML 4 "level 4 (Far distance)" 3 "level 3" 2 "level 2" 1 "level 1 (Near distance)" 0 "No signal";
VAL_ 528 PAS_A_FCR 4 "level 4 (Far distance)" 3 "level 3" 2 "level 2" 1 "level 1 (Near distance)" 0 "No signal";
VAL_ 528 PAS_Sta_F_Sys 1 "Faliure" 0 "No Faliure";
VAL_ 528 PAS_Mod_Operation 3 "UDS" 2 "FUDS" 1 "RUDS" 0 "Function OFF";
VAL_ 528 USS_Sta_RMR 1 "Checked error" 0 "Checked OK";
VAL_ 528 USS_Sta_RML 1 "Checked error" 0 "Checked OK";
VAL_ 528 USS_Sta_RLR 1 "Checked error" 0 "Checked OK";
VAL_ 528 USS_Sta_RLL 1 "Checked error" 0 "Checked OK";
VAL_ 528 USS_Sta_RCR 1 "Checked error" 0 "Checked OK";
VAL_ 528 USS_Sta_RCL 1 "Checked error" 0 "Checked OK";
VAL_ 528 USS_Sta_FMR 1 "Checked error" 0 "Checked OK";
VAL_ 528 USS_Sta_FML 1 "Checked error" 0 "Checked OK";
VAL_ 528 USS_Sta_FLR 1 "Checked error" 0 "Checked OK";
VAL_ 528 USS_Sta_FLL 1 "Checked error" 0 "Checked OK";
VAL_ 528 USS_Sta_FCR 1 "Checked error" 0 "Checked OK";
VAL_ 528 USS_Sta_FCL 1 "Checked error" 0 "Checked OK";
VAL_ 534 DrDoorSW 1 "Open" 0 "Close";
VAL_ 534 PsDoorSW 1 "Open" 0 "Close";
VAL_ 534 RLDoorSW 1 "Open" 0 "Close";
VAL_ 534 RRDoorSW 1 "Open" 0 "Close";
VAL_ 534 AllDoorSW 1 "Any Door Open" 0 "Close";
VAL_ 534 DoorLockIND 1 "On" 0 "Off";
VAL_ 534 HoodSW 1 "Open" 0 "Close";
VAL_ 534 Tailgate_SW 1 "Open" 0 "Close";
VAL_ 534 CTDCtrl 3 "Lock All Door" 2 "Unlock All Door" 1 "Unlock Driver Door" 0 "No Command";
VAL_ 534 Fr_ChargingDoorCtrl 3 "Undefined" 2 "Lock" 1 "Unlock" 0 "No Command";
VAL_ 534 Rr_ChargingDoorCtrl 3 "Undefined" 2 "Lock" 1 "Unlock" 0 "No Command";
VAL_ 534 CTDLockSW 1 "Press" 0 "Release";
VAL_ 534 CTDUnlockSW 1 "Press" 0 "Release";
VAL_ 534 MirrorDefog 1 "On" 0 "Off";
VAL_ 534 Rr_Defog 1 "On" 0 "Off";
VAL_ 534 TrunkRel 1 "Release" 0 "Off";
VAL_ 534 TailgateHDSW 1 "Press" 0 "Release";
VAL_ 534 MirrorCtrl 3 "Undefined" 2 "Unfold" 1 "Fold" 0 "No Command";
VAL_ 534 Fr_Wiper_H 1 "On" 0 "Off";
VAL_ 534 Fr_Wiper_L 1 "On" 0 "Off";
VAL_ 534 Rr_Wiper 1 "On" 0 "Off";
VAL_ 534 WiperFixMode 1 "On" 0 "Off";
VAL_ 534 WasherCtrl 3 "Undefined" 2 "Rear Washer" 1 "Front Washer" 0 "No Command";
VAL_ 534 L_Beam 1 "On" 0 "Off";
VAL_ 534 H_Beam 1 "On" 0 "Off";
VAL_ 534 PosLamp 1 "On" 0 "Off";
VAL_ 534 LDRL 1 "On" 0 "Off";
VAL_ 534 RDRL 1 "On" 0 "Off";
VAL_ 534 ReverseLamp 1 "On" 0 "Off";
VAL_ 534 BrakeLamp 1 "On" 0 "Off";
VAL_ 534 LBSD 1 "On" 0 "Off";
VAL_ 534 RBSD 1 "On" 0 "Off";
VAL_ 534 Fr_FogLamp 1 "On" 0 "Off";
VAL_ 534 Rr_FogLamp 1 "On" 0 "Off";
VAL_ 534 HazardSW 1 "On" 0 "Off";
VAL_ 534 LTurnLP 1 "On" 0 "Off";
VAL_ 534 RTurnLP 1 "On" 0 "Off";
VAL_ 534 AntitheftSta 3 "Alarm Status" 2 "Wait for Rearm Status" 1 "Arm Status" 0 "Disarm Status";
VAL_ 534 AntiTheftSeatFold 1 "Fold" 0 "No Request";
VAL_ 534 LockSetting 1 "Unlock Single Door" 0 "Unlock All Door";
VAL_ 534 BCM_Buzzer_Req 1 "Request" 0 "No Request";
VAL_ 534 TailgateRemote 3 "Invalid" 2 "Handle Request" 1 "Remote Request" 0 "No Request";
VAL_ 534 RoomLampL 1 "ON" 0 "OFF";
VAL_ 534 RoomLampH 1 "ON" 0 "OFF";
VAL_ 534 DimmerEN 1 "Enable" 0 "Disable";
VAL_ 534 BCM_DoorLock_Sta 1 "Lock" 0 "Unlock";
VAL_ 534 HornCtrl 1 "ON" 0 "OFF";
VAL_ 534 CrashDetd 1 "Crash detected" 0 "Crash not detected";
VAL_ 534 L_APM_WdwEnable 1 "Normal" 0 "Inhibit";
VAL_ 553 EPS_Pwr_Consumpt_V 1 "Valid" 0 "Invalid";
VAL_ 553 EPS_VOL_V 1 "Valid" 0 "Invalid";
VAL_ 553 EPS_Temp_V 1 "Valid" 0 "Invalid";
VAL_ 553 EpasFailed 2 "Perm Faild" 1 "Temp Faild" 0 "Not Faild";
VAL_ 553 EPS_Pwr_Limit_V 1 "Valid" 0 "Invalid";
VAL_ 553 Steering_Torque_V 1 "Failed" 0 "Not Failed";
VAL_ 566 APS_Sta_System 4 "Remote Actived" 3 "Failed" 2 "Active" 1 "Enable" 0 "Disable";
VAL_ 566 APS_V_Rq_EPAS_Ctrl 1 "Valid" 0 "Invalid";
VAL_ 566 APS_Rq_EPAS_Ctrl 1 "Request on EPS Control" 0 "No Request on EPS Control";
VAL_ 568 APS_Req 3 "Standstill with EPB" 2 "Standstill with Brake Hold" 1 "Decel Control" 0 "No request";
VAL_ 568 SPTG_Sta 2 "enable" 1 "disable" 0 "OFF";
VAL_ 568 CAAS_Sta 3 "Active" 2 "enable" 1 "disable" 0 "OFF";
VAL_ 568 APS_DecReq_A 1 "Applicable" 0 "Not Applicable";
VAL_ 568 SPTGDet 1 "request" 0 "no request";
VAL_ 568 APSOpenPTG 1 "request" 0 "no request";
VAL_ 570 ADAS_SLIF_SpdLim 31 "80mph" 30 "75mph" 29 "70mph" 28 "65mph" 27 "60mph" 26 "55mph" 25 "50mph" 24 "45mph" 23 "40mph" 22 "35mph" 21 "30mph" 20 "25mph" 19 "20mph" 18 "15mph" 17 "10mph" 16 "160 km/h" 15 "150 km/h" 14 "140 km/h" 13 "130 km/h" 12 "120 km/h" 11 "110 km/h" 10 "100 km/h" 9 "90 km/h" 8 "80 km/h" 7 "70 km/h" 6 "60 km/h" 5 "50 km/h" 4 "40 km/h" 3 "30 km/h" 2 "20 km/h" 1 "10 km/h" 0 "No request";
VAL_ 570 Target_Type 4 "Truck" 3 "Two Wheel" 2 "Vehicle" 1 "Pedestrian" 0 "None";
VAL_ 570 ADAS_CAM_SpdLim 31 "80mph" 30 "75mph" 29 "70mph" 28 "65mph" 27 "60mph" 26 "55mph" 25 "50mph" 24 "45mph" 23 "40mph" 22 "35mph" 21 "30mph" 20 "25mph" 19 "20mph" 18 "15mph" 17 "10mph" 16 "160 km/h" 15 "150 km/h" 14 "140 km/h" 13 "130 km/h" 12 "120 km/h" 11 "110 km/h" 10 "100 km/h" 9 "90 km/h" 8 "80 km/h" 7 "70 km/h" 6 "60 km/h" 5 "50 km/h" 4 "40 km/h" 3 "30 km/h" 2 "20 km/h" 1 "10 km/h" 0 "No request";
VAL_ 570 ADAS_WarningMsg 15 "reserve" 14 "reserve" 13 "reserve" 12 "reserve" 11 "reserve" 10 "reserve" 9 "reserve" 8 "reserve" 7 "Takeover Request" 6 "Disable to Engage FSRA" 5 "FSRA Disengaged" 4 "Available to resume Acceleration Control" 3 "Object Disappeared" 2 "reserve" 1 "reserve" 0 "None";
VAL_ 570 ACC_TakeoverReq 1 "request" 0 "no request";
VAL_ 570 ACCSetSpeed_Disp 3 "Green" 2 "Grey" 1 "Dash Line" 0 "None";
VAL_ 570 TimeGapLevel 4 "Level 4" 3 "Level 3" 2 "Level 2" 1 "Level 1" 0 "Off";
VAL_ 570 ForceLowBeam 2 "Invalid" 1 "Force Low Beam" 0 "No Request";
VAL_ 570 ACC_ObjDstLvl 4 "Level 4" 3 "Level 3" 2 "Level 2" 1 "Level 1" 0 "None";
VAL_ 570 ADAS_ACC_Sta 6 "Disable" 5 "Error" 4 "Shut-off" 3 "Override" 2 "Active" 1 "Standby" 0 "Off";
VAL_ 570 ADAS_FltWrnReq 1 "Warning Request" 0 "No Warning";
VAL_ 570 ADAS_LDW_Sta 6 "Disable" 5 "Error" 4 "Right warning" 3 "Left warning" 2 "Active" 1 "Standby" 0 "Off";
VAL_ 570 LeftTurnLightReq 1 "Request" 0 "No Request";
VAL_ 570 ADAS_FCW_Sta 4 "Disable" 3 "Error" 2 "Active" 1 "Standby" 0 "Off";
VAL_ 570 RightTurnLightReq 1 "Request" 0 "No Request";
VAL_ 570 ADAS_AEB_Sta 4 "Disable" 3 "Error" 2 "Active" 1 "Standby" 0 "Off";
VAL_ 570 HazardWarningReq 1 "Request" 0 "No Request";
VAL_ 572 ADAS_LFC_Warn_Sound 1 "Warning Sound" 0 "OFF";
VAL_ 572 LVDA_ACCStatusInformation 1 "ACC is in stop-hold mode" 0 "Default";
VAL_ 572 LVDA_Warning 1 "Warning" 0 "No warning";
VAL_ 572 LVDA_Failinfo 1 "Fail" 0 "No fail";
VAL_ 572 LVDA_Mute_Sta 3 "Invalid" 2 "Mute" 1 "No Mute" 0 "Default";
VAL_ 572 LVDA_Disabled 1 "Disabled" 0 "Enabled";
VAL_ 572 ADAS_LFC_Hands_Off_Warning 3 "Automatic release warning" 2 "2nd Warning" 1 "1st Warning" 0 "OFF";
VAL_ 572 ADAS_FCW_Mute 1 "Mute" 0 "No Mute";
VAL_ 572 ADAS_LDW_Mute 1 "Mute" 0 "No Mute";
VAL_ 572 ADAS_ISA_Sta 3 "Disable" 2 "Error" 1 "Active" 0 "Off";
VAL_ 572 ADAS_SLIF_Sta 5 "Disable" 4 "Invalid" 3 "Temporary Unavailable" 2 "System Fail" 1 "Normal (Default)" 0 "OFF";
VAL_ 572 ADAS_LaneModeR 1 "Detected" 0 "Not detected";
VAL_ 572 ADAS_LaneModeL 1 "Detected" 0 "Not detected";
VAL_ 572 ADAS_LFC_Sta 5 "Disable" 4 "Error" 3 "Green Blinking" 2 "Green" 1 "White" 0 "OFF";
VAL_ 572 LKA_HOD_Sound_Warning 1 "Hands-off Warning" 0 "No Warning";
VAL_ 572 ADAS_LKA_Sta 6 "Disable" 5 "Error" 4 "Right Assist" 3 "Left Assist" 2 "Active" 1 "Standby" 0 "Off";
VAL_ 572 LKA_HOD_Display_Warning 1 "Hands-off Warning" 0 "No Warning";
VAL_ 602 ParkBrake 1 "On" 0 "Off";
VAL_ 602 Charge 1 "Disable (LED ON)" 0 "Enable (LED OFF)";
VAL_ 602 LEDlitWarnReq 1 "Warning request" 0 "No warning request";
VAL_ 602 Spd_Crl_Sta 1 "ON" 0 "OFF";
VAL_ 602 Spd_Crl_Mode 5 "invalid" 4 "ISA" 3 "LIM" 2 "CC" 1 "ACC" 0 "OFF";
VAL_ 659 RegenMode 7 "Invalid" 6 "One-Pedal" 5 "Level 5" 4 "Level 4" 3 "Level 3" 2 "Level 2" 1 "Level 1" 0 "Off";
VAL_ 659 Zone_Spd_Ctrl_Sta 1 "ON" 0 "OFF";
VAL_ 659 Zone_Spd_Ctrl_Mode 5 "invalid" 4 "ISA" 3 "LIM" 2 "CC" 1 "ACC" 0 "OFF";
VAL_ 659 DrSCPSysErrLmp 1 "Error" 0 "Normal";
VAL_ 826 SWC_LKA_Sta 1 "Press" 0 "Release";
VAL_ 826 SWC_Undefined_Sta 1 "Press" 0 "Release";
VAL_ 826 SWC_VR_Sta 1 "Press" 0 "Release";
VAL_ 826 SWC_Up_Sta 1 "Press" 0 "Release";
VAL_ 826 SWC_Trip_Sta 1 "Press" 0 "Release";
VAL_ 826 SWC_Set_down_Sta 1 "Press" 0 "Release";
VAL_ 826 SWC_Right_Sta 1 "Press" 0 "Release";
VAL_ 826 SWC_RegenDown 1 "Press" 0 "Release";
VAL_ 826 SWC_Res_Up_Sta 1 "Press" 0 "Release";
VAL_ 826 SWC_resp_error 1 "Error" 0 "Normal";
VAL_ 826 SWC_mode_Sta 1 "Press" 0 "Release";
VAL_ 826 SWC_Left_Sta 1 "Press" 0 "Release";
VAL_ 826 SWC_RegenUp 1 "Press" 0 "Release";
VAL_ 826 SWC_Down_Sta 1 "Press" 0 "Release";
VAL_ 826 SWC_Distance_Sta 1 "Press" 0 "Release";
VAL_ 826 SWC_A_Resp_Err 1 "Error" 0 "Normal";
VAL_ 826 SWC_ACC_Sta 1 "Press" 0 "Release";
VAL_ 826 SWC_CANCEL_Sta 1 "Press" 0 "Release";
VAL_ 826 SWC_Drivemode_Sta 1 "Press" 0 "Release";
VAL_ 960 VehMalfunLevel 5 "Invalid" 4 "4th grade malfunction" 3 "3rd grade malfunction" 2 "2nd grade malfunction" 1 "1st grade malfunction" 0 "Normal";
VAL_ 960 Eng_AGSCloseSta 1 "Closed" 0 "Auto";
VAL_ 960 Eng_PwrLockSta 2 "Invalid" 1 "Locked" 0 "Unlocked";
VAL_ 960 Eng_CoastDwSta 2 "Invalid" 1 "On" 0 "Off";
VAL_ 960 Eng_ActvDmpDisabSta 2 "Invalid" 1 "On" 0 "Off";
VAL_ 1173 AVM_parking_cancel 2 "invalid" 1 "press" 0 "release";
VAL_ 1173 AVM_parking_excute 3 "remote request" 2 "invalid" 1 "press" 0 "release";
VAL_ 1173 AVM_OFF_Rec_Butt 1 "ON" 0 "OFF";
VAL_ 1173 IVI_AGSCloseSW 3 "Undefined" 2 "Invalid" 1 "Press (>0.5s)" 0 "Release";
VAL_ 1173 IVI_LVChrgFuncSW 3 "Undefined" 2 "Invalid" 1 "Press (>0.5s)" 0 "Release";
VAL_ 1173 IVI_PwrLockSW 3 "Undefined" 2 "Invalid" 1 "Press (>0.5s)" 0 "Release";
VAL_ 1173 IVI_CoastDwSW 3 "Undefined" 2 "Invalid" 1 "Press (>0.5s)" 0 "Release";
VAL_ 1173 IVI_ActvDmpDisabSW 3 "Undefined" 2 "Invalid" 1 "Press (>0.5s)" 0 "Release";
VAL_ 1173 Roll_Mode_SW_Cmd 3 "Invaild" 2 "Undefined" 1 "Press" 0 "Release";
VAL_ 1173 TCS_SW_Cmd 3 "Invaild" 2 "Undefined" 1 "Press" 0 "Release";
VAL_ 1173 SLIF_BUTT 2 "Invalid" 1 "Pressed" 0 "No request";
VAL_ 1173 Roll_Eng_Mode 1 "on" 0 "off";
VAL_ 1173 SOC_Limit_Set 31 "invalid" 26 "~0x1E undefined" 0 "~0x19 50%~100%";
VAL_ 1173 CDL_Lock_Butt 1 "Press" 0 "Release";
VAL_ 1173 CDL_Unlock_Butt 1 "Press" 0 "Release";
VAL_ 1173 SOC_ADJ_BUTT 1 "Press" 0 "Release";
VAL_ 1173 IVI_ISA_OffsetSpd 15 "Invalid" 14 "reserve" 13 "reserve" 12 "reserve" 11 "5 mph" 10 "0 mph" 9 "-5 mph" 8 "reserve" 7 "reserve" 6 "reserve" 5 "+10 km/h" 4 "+5 km/h" 3 "0 km/h" 2 "-5 km/h" 1 "-10 km/h" 0 "Off";
VAL_ 1173 RoomLampMode 1 "OFF Mode" 0 "DoorMode";
VAL_ 1173 NAVI_SpeedLimit 31 "80mph" 30 "75mph" 29 "70mph" 28 "65mph" 27 "60mph" 26 "55mph" 25 "50mph" 24 "45mph" 23 "40mph" 22 "35mph" 21 "30mph" 20 "25mph" 19 "20mph" 18 "15mph" 17 "10mph" 16 "160 km/h" 15 "150 km/h" 14 "140 km/h" 13 "130 km/h" 12 "120 km/h" 11 "110 km/h" 10 "100 km/h" 9 "90 km/h" 8 "80 km/h" 7 "70 km/h" 6 "60 km/h" 5 "50 km/h" 4 "40 km/h" 3 "30 km/h" 2 "20 km/h" 1 "10 km/h" 0 "No request";
VAL_ 1173 NAVI_RoadClass 7 "undefined" 6 "undefined" 5 "Freeway" 4 "School" 3 "Street" 2 "Interurban" 1 "City" 0 "NA";
VAL_ 1173 NAVI_LinkClass 15 "undefined" 14 "undefined" 13 "undefined" 12 "undefined" 11 "undefined" 10 "undefined" 9 "undefined" 8 "etc" 7 "shoulder" 6 "ramp" 5 "Freeway" 4 "Bus lane" 3 "Roundabout" 2 "City Lv2" 1 "City Lv1" 0 "NA";
VAL_ 1173 NAVI_ForwardLinkLevel 15 "undefined" 14 "undefined" 13 "undefined" 12 "undefined" 11 "undefined" 10 "undefined" 9 "undefined" 8 "etc" 7 "shoulder" 6 "ramp" 5 "Freeway" 4 "Bus lane" 3 "Roundabout" 2 "City Lv2" 1 "City Lv1" 0 "NA";
VAL_ 1173 SenstivityPosition 15 "not used" 14 "not used" 13 "not used" 12 "not used" 11 "not used" 10 "not used" 9 "not used" 8 "not used" 7 "not used" 6 "not used" 5 "not used" 4 "senstivity level-4" 3 "senstivity level-3" 2 "senstivity level-2" 1 "senstivity level-1" 0 "not used";
VAL_ 1173 AVM_Parking_mode 8 "Forced to end" 7 "emergency stop" 6 "Left parking out" 5 "Right parking out" 4 "Left Perpendicular parking" 3 "Right Perpendicular parking" 2 "Left Parallel parking" 1 "Right Parallel parking" 0 "No message";
VAL_ 1173 Hood_Latch_SW 2 "invalid" 1 "Press" 0 "No Request";
VAL_ 1173 RCTA_BUTT 2 "Invalid" 1 "Pressed" 0 "No request";
VAL_ 1173 IVI_Pwroff_req 1 "Request" 0 "No request";
VAL_ 1173 IVI_Trigger_req 1 "Request" 0 "No request";
VAL_ 1173 AVM_Err_STA 1 "Error" 0 "No Error";
VAL_ 1173 IVI_Mute_Sta 1 "Mute On" 0 "Mute Off";
VAL_ 1173 IVI_PTG_USSta_SW 1 "Off" 0 "On";
VAL_ 1173 IVI_WI_MAIN_SW 1 "ON" 0 "OFF";
VAL_ 1173 IVI_RR_Def_Req 1 "Press" 0 "Release";
VAL_ 1173 IVI_Night_Mode_Sta 1 "ON" 0 "OFF";
VAL_ 1173 IVI_Status 1 "Ready" 0 "Not ready";
VAL_ 1173 LVDAMute_BUTT 2 "Invalid" 1 "Pressed" 0 "No request";
VAL_ 1173 CAAS_Sw 2 "Invalid" 1 "Press" 0 "Release";
VAL_ 1173 DSEAT_entryfun_set 1 "ON" 0 "OFF";
VAL_ 1173 DSEAT_anti_set 1 "ON" 0 "OFF";
VAL_ 1173 TPMS_Res_Butt 1 "Press" 0 "Release";
VAL_ 1173 FollowMeSW 1 "Press" 0 "Release";
VAL_ 1173 SetUnlockSingle 1 "Press" 0 "Release";
VAL_ 1173 IVI_PTG_Mode_SW 2 "Invalid" 1 "Press" 0 "No Request";
VAL_ 1173 IVI_PTG_Sta_SW 2 "Invalid" 1 "Press" 0 "Release";
VAL_ 1173 SLG_Sw 2 "invalid" 1 "ON" 0 "OFF";
VAL_ 1173 FS_Off_Sw 2 "invalid" 1 "ON" 0 "OFF";
VAL_ 1173 PSEAT_vent_req 4 "OFF" 3 "Vent3" 2 "Vent2" 1 "Vent1" 0 "No request";
VAL_ 1173 FFogLampSW 1 "ON" 0 "OFF";
VAL_ 1173 DSEAT_vent_req 7 "Not used" 6 "Not used" 5 "Not used" 4 "OFF" 3 "High" 2 "Middle" 1 "Low" 0 "No request";
VAL_ 1173 RFogLampSW 1 "ON" 0 "OFF";
VAL_ 1173 MFRD_N_Bright_Req 127 "invalid" 100 "Max" 0 "Min";
VAL_ 1173 User_p_download 1 "download" 0 "No Request";
VAL_ 1173 HeadLampSW 3 "OFF" 2 "Low beam" 1 "Postion lamp" 0 "AUTO";
VAL_ 1173 NAVI_State 3 "NAVI error" 2 "NAVI good reception" 1 "NAVI no satellite" 0 "No NAVI";
VAL_ 1173 Wifi_Sta_IVI_TBOX 9 "password error" 8 "Connection error" 6 "Internal Error" 5 "no signal" 4 "4 bar" 3 "3 bar" 2 "2 bar" 1 "1 bar" 0 "Invalid";
VAL_ 1173 NAVI_Cam_Dist_info 255 "Invalid" 150 "MAX" 0 "Min";
VAL_ 1173 OFF_AC_MODE 7 "Invalid" 3 "CAMP" 2 "Pet" 1 "ON" 0 "OFF";
VAL_ 1173 IVI_PW_Mode_Req 3 "No request" 2 "ECO" 1 "Sport" 0 "Normal";
VAL_ 1173 User_p_upload 1 "upload" 0 "No Request";
VAL_ 1173 CameraWrn 1 "Warnning enable" 0 "Off";
VAL_ 1173 Wifi_Reset 1 "reset VIG Wifi" 0 "No Request";
VAL_ 1173 IVI_Screen 63 "invalid" 62 "undefined" 29 "undefined" 28 "APS-all" 27 "AVM-all" 26 "Phone:incoming call popup:upper" 25 "Phone:dialer-upper" 24 "Phone:call history-upper" 23 "Phone:contacts-upper" 22 "System setting-Display-all" 21 "System setting-Sound-all" 20 "System setting-Cellular-all" 19 "System setting-Bluetooth-all" 18 "System setting-WiFi-all" 17 "System setting-account-all" 16 "Setting-About-all" 15 "Setting-Software-all" 14 "Setting-Service-all" 13 "Setting-Security-all" 12 "Setting-ADAS-all" 11 "Setting-Doors-all" 10 "Setting-Charging-all" 9 "Setting-Energy-all" 8 "Setting-Spotlight-all" 7 "Navi page-upper" 6 "3rd party app page-upper" 5 "Android auto-upper" 4 "Car play-upper" 3 "All app page-upper" 2 "DropDown menu-upper" 1 "DropDown menu-all" 0 "Home-up";
VAL_ 1173 TurnSwTimeSet 3 "Undefiend" 2 "7 times" 1 "5 times" 0 "3 times";
VAL_ 1173 Pressure_unit 1 "kg/m2" 0 "PSI";
VAL_ 1173 Time_system 1 "24h" 0 "12h";
VAL_ 1173 NAVI_Speed_Limit_A 3 "invalid" 2 "Not Used" 1 "Applicable" 0 "Not Applicable";
VAL_ 1173 Temperature_unit 1 "Fahrenheit" 0 "Celsius";
VAL_ 1173 Distance_unit 1 "mile" 0 "kilometer";
VAL_ 1173 ESC_SW_Cmd 3 "Invaild" 2 "Undefined" 1 "Press" 0 "Release";
VAL_ 1173 IVI_Panel_Act 1 "PRESS" 0 "RELEASE";
VAL_ 1173 sigHvacRearReq 1 "Press" 0 "Release";
VAL_ 1173 FCWMute_BUTT 2 "Invalid" 1 "Pressed" 0 "No request";
VAL_ 1173 LKA_BUTT 2 "Invalid" 1 "Pressed" 0 "No request";
VAL_ 1173 ODAMute_BUTT 2 "Invalid" 1 "Pressed" 0 "No request";
VAL_ 1173 LDWMute_BUTT 2 "Invalid" 1 "Pressed" 0 "No request";
VAL_ 1173 BSDMute_BUTT 2 "Invalid" 1 "Pressed" 0 "No request";
VAL_ 1173 sigWindDirZon3Req 7 "NOT Set / Reserved" 6 "All open" 5 "Face + Screen" 4 "DEFOG" 3 "Foot + Screen" 2 "Foot" 1 "Bilevel" 0 "FACE";
VAL_ 1173 sigAirIntenZon3Req 15 "Invalid" 14 "Reserved" 11 "Reserved" 10 "NOT set" 9 "Level 8" 8 "Level 7" 7 "Level 6" 6 "Level 5" 5 "Level 4" 4 "Level 3" 3 "Level 2" 2 "Level 1" 1 "OFF" 0 "NO display / No request";
VAL_ 1173 sigAirIntenZon1Req 15 "Invalid" 14 "Reserved" 11 "Reserved" 10 "NOT set" 9 "Level 8" 8 "Level 7" 7 "Level 6" 6 "Level 5" 5 "Level 4" 4 "Level 3" 3 "Level 2" 2 "Level 1" 1 "OFF" 0 "NO display / No request";
VAL_ 1173 AEB_BUTT 2 "Invalid" 1 "Pressed" 0 "No request";
VAL_ 1173 sigRecircReq 1 "Press" 0 "Release";
VAL_ 1173 sigHvacReq 1 "ON" 0 "Off / Auto";
VAL_ 1173 sigHvacFrontReq 1 "Press" 0 "Release";
VAL_ 1173 sigDfrstReq 1 "press" 0 "relesase";
VAL_ 1173 L_Drv_ControlCommand 127 "No Request" 100 "Max" 0 "Min";
VAL_ 1173 TPMS_Cali_Butt 1 "press" 0 "relesase";
VAL_ 1173 L_Pas_ControlCommand 127 "No Request" 100 "Max" 0 "Min";
VAL_ 1173 IVI_Unlock_Chg_req 1 "press" 0 "relesase";
VAL_ 1173 L_RLD_ControlCommand 127 "No Request" 100 "Max" 0 "Min";
VAL_ 1173 IVI_Stop_Chg_req 1 "press" 0 "relesase";
VAL_ 1173 L_RRD_ControlCommand 127 "No Request" 100 "Max" 0 "Min";
VAL_ 1173 IVI_Start_Chg_req 1 "press" 0 "relesase";
VAL_ 1173 METER_Malfunc_Sta 2 "Warning flash" 1 "Warning" 0 "Normal";
VAL_ 1173 sigFootReq 1 "press" 0 "relesase";
VAL_ 1173 sigFaceReq 1 "press" 0 "relesase";
VAL_ 1173 Sched_Chg_Start 1 "press" 0 "release";
VAL_ 1173 Sched_Chg_wake 1 "wake" 0 "standby";
VAL_ 1173 Sched_Chg_butt 1 "on" 0 "off";
VAL_ 1173 Sched_Chg_Stop 1 "press" 0 "release";
VAL_ 1173 Sched_Chg_limit 31 "invalid" 26 "~0x1E undefined" 0 "~0x19 50%~100%";
VAL_ 1173 IVI_Req_V2L 1 "Request" 0 "Not request";
VAL_ 1173 Perd_V2L 15 "8hr" 14 "7.5hr" 13 "7hr" 12 "6.5hr" 11 "6hr" 10 "5.5hr" 9 "5hr" 8 "4.5hr" 7 "4hr" 6 "3.5hr" 5 "3hr" 4 "2.5hr" 3 "2hr" 2 "1.5hr" 1 "1hr" 0 "0.5hr";
VAL_ 1173 SOC_V2LLimit 15 "invalid" 14 "undefined" 13 "undefined" 12 "80%" 11 "75%" 10 "70%" 9 "65%" 8 "60%" 7 "55%" 6 "50%" 5 "45%" 4 "40%" 3 "35%" 2 "30%" 1 "25%" 0 "20%";
VAL_ 1173 IVI_PTG_Open_Height 7 "Invalid" 6 "Invalid" 5 "Invalid" 4 "Set by User" 3 "Lv3(80%)" 2 "Lv2(60%)" 1 "Lv1(40%)" 0 "Full Open";
VAL_ 1173 IVI_CreepSW_Req 1 "Press" 0 "Release";
VAL_ 1173 FalseNPrevent_SW 1 "ON" 0 "OFF";
VAL_ 1173 Approach_Unlock_SW 1 "ON" 0 "OFF";
VAL_ 1173 Walkaway_Lock_SW 1 "ON" 0 "OFF";
VAL_ 1183 IVI_Located_STA 3 "Not Used" 2 "3D fix" 1 "2D fix" 0 "No fix";
VAL_ 1183 IVI_Time_Month 15 "Not Used" 14 "Not Used" 13 "Not Used" 0 "invalid";
VAL_ 1280 NM_FUSION_Rpt_Msg_Req 1 "Repeat Message State requested" 0 "Repeat Message State not requested";
VAL_ 1280 NM_FUSION_CSB 1 "Start of synchronized shutdown is requested by main coordinator" 0 "Start of synchronized shutdown is not requested by main coordinator";
VAL_ 1280 NM_FUSION_Active_WU 1 "Node has woken up the network (active Wakeup)" 0 "Node has not woken up the network (passive wakeup)";
VAL_ 1280 NM_FUSION_PNI 1 "NM PDU contains Partial Network request information" 0 "NM PDU contains no Partial Network request information";
VAL_ 1280 NM_FUSION_ERROR_State 8 "BUS OFF_L2" 4 "BUS OFF_L1" 2 "ERROR PASSIVE" 1 "ERROR ACTIVE" 0 "Inactive";
VAL_ 1281 NM_ESC_Rpt_Msg_Req 1 "Repeat Message State requested" 0 "Repeat Message State not requested";
VAL_ 1281 NM_ESC_CSB 1 "Start of synchronized shutdown is requested by main coordinator" 0 "Start of synchronized shutdown is not requested by main coordinator";
VAL_ 1281 NM_ESC_Active_WU 1 "Node has woken up the network (active Wakeup)" 0 "Node has not woken up the network (passive wakeup)";
VAL_ 1281 NM_ESC_PNI 1 "NM PDU contains Partial Network request information" 0 "NM PDU contains no Partial Network request information";
VAL_ 1281 NM_ESC_ERROR_State 8 "BUS OFF_L2" 4 "BUS OFF_L1" 2 "ERROR PASSIVE" 1 "ERROR ACTIVE" 0 "Inactive";
VAL_ 1296 NM_FCM_Rpt_Msg_Req 1 "Repeat Message State requested" 0 "Repeat Message State not requested";
VAL_ 1296 NM_FCM_CSB 1 "Start of synchronized shutdown is requested by main coordinator" 0 "Start of synchronized shutdown is not requested by main coordinator";
VAL_ 1296 NM_FCM_Active_WU 1 "Node has woken up the network (active Wakeup)" 0 "Node has not woken up the network (passive wakeup)";
VAL_ 1296 NM_FCM_PNI 1 "NM PDU contains Partial Network request information" 0 "NM PDU contains no Partial Network request information";
VAL_ 1296 NM_FCM_ERROR_State 8 "BUS OFF_L2" 4 "BUS OFF_L1" 2 "ERROR PASSIVE" 1 "ERROR ACTIVE" 0 "Inactive";
VAL_ 1297 NM_eBST_Rpt_Msg_Req 1 "Repeat Message State requested" 0 "Repeat Message State not requested";
VAL_ 1297 NM_eBST_CSB 1 "Start of synchronized shutdown is requested by main coordinator" 0 "Start of synchronized shutdown is not requested by main coordinator";
VAL_ 1297 NM_eBST_Active_WU 1 "Node has woken up the network (active Wakeup)" 0 "Node has not woken up the network (passive wakeup)";
VAL_ 1297 NM_eBST_PNI 1 "NM PDU contains Partial Network request information" 0 "NM PDU contains no Partial Network request information";
VAL_ 1297 NM_eBST_ERROR_State 8 "BUS OFF_L2" 4 "BUS OFF_L1" 2 "ERROR PASSIVE" 1 "ERROR ACTIVE" 0 "Inactive";
VAL_ 1298 NM_SRR_M_Rpt_Msg_Req 1 "Repeat Message State requested" 0 "Repeat Message State not requested";
VAL_ 1298 NM_SRR_M_CSB 1 "Start of synchronized shutdown is requested by main coordinator" 0 "Start of synchronized shutdown is not requested by main coordinator";
VAL_ 1298 NM_SRR_M_Active_WU 1 "Node has woken up the network (active Wakeup)" 0 "Node has not woken up the network (passive wakeup)";
VAL_ 1298 NM_SRR_M_PNI 1 "NM PDU contains Partial Network request information" 0 "NM PDU contains no Partial Network request information";
VAL_ 1298 NM_SRR_M_ERROR_State 8 "BUS OFF_L2" 4 "BUS OFF_L1" 2 "ERROR PASSIVE" 1 "ERROR ACTIVE" 0 "Inactive";
VAL_ 1313 NM_EPAS_Rpt_Msg_Req 1 "Repeat Message State requested" 0 "Repeat Message State not requested";
VAL_ 1313 NM_EPAS_CSB 1 "Start of synchronized shutdown is requested by main coordinator" 0 "Start of synchronized shutdown is not requested by main coordinator";
VAL_ 1313 NM_EPAS_Active_WU 1 "Node has woken up the network (active Wakeup)" 0 "Node has not woken up the network (passive wakeup)";
VAL_ 1313 NM_EPAS_PNI 1 "NM PDU contains Partial Network request information" 0 "NM PDU contains no Partial Network request information";
VAL_ 1313 NM_EPAS_ERROR_State 8 "BUS OFF_L2" 4 "BUS OFF_L1" 2 "ERROR PASSIVE" 1 "ERROR ACTIVE" 0 "Inactive";
VAL_ 1329 NM_ABM_Rpt_Msg_Req 1 "Repeat Message State requested" 0 "Repeat Message State not requested";
VAL_ 1329 NM_ABM_CSB 1 "Start of synchronized shutdown is requested by main coordinator" 0 "Start of synchronized shutdown is not requested by main coordinator";
VAL_ 1329 NM_ABM_Active_WU 1 "Node has woken up the network (active Wakeup)" 0 "Node has not woken up the network (passive wakeup)";
VAL_ 1329 NM_ABM_PNI 1 "NM PDU contains Partial Network request information" 0 "NM PDU contains no Partial Network request information";
VAL_ 1329 NM_ABM_ERROR_State 8 "BUS OFF_L2" 4 "BUS OFF_L1" 2 "ERROR PASSIVE" 1 "ERROR ACTIVE" 0 "Inactive";
VAL_ 550 DrLockSta 1 "Lock" 0 "Unlcok";
VAL_ 550 PsLockSta 1 "Lock" 0 "Unlcok";
VAL_ 550 RLLockSta 1 "Lock" 0 "Unlcok";
VAL_ 550 RRLockSta 1 "Lock" 0 "Unlcok";
VAL_ 550 AllLockSta 1 "Lock" 0 "Unlcok";
VAL_ 550 MIRROR_FOLD_SW 1 "Press" 0 "Release";
VAL_ 550 RWiperAS 1 "Not at Stop Position" 0 "Stop Position";
VAL_ 550 RWiperProtection 1 "In protection" 0 "Not in Protectio";
VAL_ 550 Wip_Speed 3 "High speed" 2 "Low speed" 1 "Intermittent" 0 "OFF";
VAL_ 550 CSW_RWipIntSw_Sta 3 "Invalid" 2 "Low" 1 "int" 0 "off";
VAL_ 550 CSW_DimSw 1 "On" 0 "Off";
VAL_ 550 BrakeLampFail 1 "Fail" 0 "Normal";
VAL_ 550 CSW_PassSW_Sta 1 "Press" 0 "Release";
VAL_ 550 RLS_Exist 1 "Exist" 0 "Not Exist";
VAL_ 550 CSW_FWasSw_Sta 3 "invalid" 2 "Mist" 1 "ON" 0 "OFF";
VAL_ 550 CSW_RWasSW_Sta 3 "invalid" 1 "Press" 0 "Release";
VAL_ 550 CSW_TurnSw_Sta 3 "invalid" 2 "Right" 1 "Left" 0 "OFF";
VAL_ 550 HornSW 1 "Press" 0 "Release";
VAL_ 550 CSW_FWipSw_Sta 7 "invalid" 3 "High" 2 "Low" 1 "Auto" 0 "OFF";
VAL_ 550 RLS_RainSnrWiperCmd 7 "Failure" 3 "High Speed" 2 "Low Speed" 0 "Off";
VAL_ 550 RLS_Lamp_Sta 1 "Lamps ON" 0 "Lamps OFF";
VAL_ 550 RLS_LIN_Resp_Err 1 "Error" 0 "Normal";
VAL_ 550 RLS_LightSnrErr 1 "LS error" 0 "LS no error";
VAL_ 550 RLS_RainSnrErr 1 "RS error" 0 "RS no error";
VAL_ 550 WiperSWPos 8 "wash mode" 4 "wiper in HS mode(manual)" 2 "wiper in LS mode(manual)" 1 "wiper in Auto mode" 16 "mist mode" 0 "wiper off";
VAL_ 550 WiperZeroPosSW 1 "Wiper is not in zero position" 0 "Wiper is in zero position";
VAL_ 550 AutoLightSW 1 "EnableAutolamps" 0 "DisableAutolamps";
VAL_ 550 CSW_resp_error 1 "Error" 0 "Normal";
